VERSION ""

NS_ :

BS_:

BU_: CH DIPF DIPR ETH FC HVI HVS PARTY SDCV VEH VIRT

BO_ 1060 PCS_alertLog: 8 VEH
 SG_ PCS_alertSource : 61|3@1+ (1,0) [0|5] ""  gtw
 SG_ PCS_a038_dcdcPwmEnableLine m38 : 60|1@1+ (1,0) [0|1] ""  gtw
 SG_ PCS_a073_cpType m73 : 56|2@1+ (1,0) [0|3] ""  gtw
 SG_ PCS_a027_chgPhCNoFlowBucket m27 : 56|5@1+ (0.2,0) [0|6.2] "-"  gtw
 SG_ PCS_a054_phaseConfig m54 : 56|4@1+ (1,0) [0|8] ""  gtw
 SG_ PCS_a053_phaseConfig m53 : 56|4@1+ (1,0) [0|8] ""  gtw
 SG_ PCS_a079_eepromErrorCount m79 : 56|5@1+ (1,0) [0|31] ""  gtw
 SG_ PCS_a013_inputFrequency m13 : 54|7@1+ (1,40) [40|167] "Hz"  gtw
 SG_ PCS_a006_inputFrequency m6 : 54|7@1+ (1,40) [40|167] "Hz"  gtw
 SG_ PCS_a038_dcdcPwmEnableDeasserted m38 : 53|7@1+ (1,0) [0|127] ""  gtw
 SG_ PCS_a009_intBusV m9 : 52|8@1+ (2,0) [0|510] "V"  gtw
 SG_ PCS_a073_phaseConfig m73 : 52|4@1+ (1,0) [0|8] ""  gtw
 SG_ PCS_a090_evaluatedGridConfig m90 : 52|4@1+ (1,0) [0|8] ""  gtw
 SG_ PCS_a011_outputV m11 : 52|8@1+ (2,0) [0|510] "V"  gtw
 SG_ PCS_a091_phaseTemp m91 : 51|8@1- (1,0) [-40|120] "C"  gtw
 SG_ PCS_a051_intBusVTarget m51 : 49|9@1+ (1,0) [0|511] "V"  gtw
 SG_ PCS_a070_inputFrequency m70 : 49|9@1+ (0.1,40) [40|91.1] "Hz"  gtw
 SG_ PCS_a069_inputFrequency m69 : 49|9@1+ (0.1,40) [40|91.1] "Hz"  gtw
 SG_ PCS_a010_intBusVTarget m10 : 49|9@1+ (1,0) [0|511] "V"  gtw
 SG_ PCS_a089_Freq m89 : 49|10@1+ (0.5,0) [0|500] "kHz"  gtw
 SG_ PCS_a012_transientRetryCount m12 : 49|9@1+ (0.1,0) [0|51.1] "-"  gtw
 SG_ PCS_a088_pchgMinuCommand m88 : 49|12@1+ (0.000244140625,0) [0|1] "-"  gtw
 SG_ PCS_a071_llcFrequency m71 : 48|8@1+ (1,50) [50|305] "kHz"  gtw
 SG_ PCS_a078_ptCoolantTemp m78 : 48|8@1- (1,40) [-40|125] "C"  gtw
 SG_ PCS_a029_phaseConfig m29 : 48|4@1+ (1,0) [0|8] ""  gtw
 SG_ PCS_a027_chgPhBNoFlowBucket m27 : 48|5@1+ (0.2,0) [0|6.2] "-"  gtw
 SG_ PCS_a013_inputVToIntBusDeltaMax m13 : 47|7@1+ (1,0) [0|127] "V"  gtw
 SG_ PCS_a006_inputVToIntBusDeltaMax m6 : 47|7@1+ (1,0) [0|127] "V"  gtw
 SG_ PCS_a053_startingInputVrms m53 : 47|9@1+ (1,0) [0|511] "V"  gtw
 SG_ PCS_a054_startingInputVrms m54 : 47|9@1+ (1,0) [0|511] "V"  gtw
 SG_ PCS_a001_intBusV m1 : 45|9@1+ (1,0) [0|511] "V"  gtw
 SG_ PCS_a011_intBusV m11 : 44|8@1+ (2,0) [0|510] "V"  gtw
 SG_ PCS_a009_llcCurrent m9 : 44|8@1+ (0.1,0) [0|25.5] "A"  gtw
 SG_ PCS_a090_vRmsL1L2 m90 : 43|9@1+ (1,0) [0|511] "V"  gtw
 SG_ PCS_a038_dcdcLvBusCurrent_A m38 : 43|10@1- (0.78125,0) [-400|400] "A"  gtw
 SG_ PCS_a073_inputNGVrms m73 : 43|9@1+ (1,0) [0|511] "V"  gtw
 SG_ PCS_a019_phCFaulted m19 : 42|1@1+ (1,0) [0|1] ""  gtw
 SG_ PCS_a091_phaseInputVrms m91 : 42|9@1+ (1,0) [0|511] "A"  gtw
 SG_ PCS_a089_PhaseShift m89 : 42|7@1+ (0.0078125,0) [0|1] "-"  gtw
 SG_ PCS_a019_phBFaulted m19 : 41|1@1+ (1,0) [0|1] ""  gtw
 SG_ PCS_a010_intBusV m10 : 40|9@1+ (1,0) [0|511] "V"  gtw
 SG_ PCS_a012_batteryV m12 : 40|9@1+ (1,0) [0|511] "V"  gtw
 SG_ PCS_a029_bmsPowerCommand m29 : 40|8@1+ (0.1,0) [0|25.5] "kW"  gtw
 SG_ PCS_a014_phcTemperature m14 : 40|11@1- (0.1,40) [-40|125] "C"  gtw
 SG_ PCS_a082_faultedSubstate m82 : 40|5@1+ (1,0) [0|17] ""  gtw
 SG_ PCS_a007_inputIrms m7 : 40|10@1+ (0.1,0) [0|102.3] "A"  gtw
 SG_ PCS_a069_intBusV m69 : 40|9@1+ (1,0) [0|511] "V"  gtw
 SG_ PCS_a086_vcfrontPTCoolantTemp m86 : 40|12@1- (0.1,0) [-60|128] "C"  gtw
 SG_ PCS_a070_intBusV m70 : 40|9@1+ (1,0) [0|511] "V"  gtw
 SG_ PCS_a054_acChargeCurrentLimit m54 : 40|7@1+ (1,0) [0|127] "A"  gtw
 SG_ PCS_a053_acChargeCurrentLimit m53 : 40|7@1+ (1,0) [0|127] "A"  gtw
 SG_ PCS_a019_phAFaulted m19 : 40|1@1+ (1,0) [0|1] ""  gtw
 SG_ PCS_a081_faultedSubstate m81 : 40|5@1+ (1,0) [0|17] ""  gtw
 SG_ PCS_a043_hvPrechargeTargetV m43 : 40|12@1+ (0.146484375,0) [0|600] "V"  gtw
 SG_ PCS_a008_inputIrms m8 : 40|10@1+ (0.1,0) [0|102.3] "A"  gtw
 SG_ PCS_a078_dcdcTemperature m78 : 40|8@1- (1,40) [-40|125] "C"  gtw
 SG_ PCS_a079_operationAddress m79 : 40|16@1+ (1,0) [0|65535] ""  gtw
 SG_ PCS_a027_chgPhANoFlowBucket m27 : 40|5@1+ (0.2,0) [0|6.2] "-"  gtw
 SG_ PCS_a051_intBusV m51 : 40|9@1+ (1,0) [0|511] "V"  gtw
 SG_ PCS_a071_inputFrequency m71 : 39|9@1+ (0.1,40) [40|91.1] "Hz"  gtw
 SG_ PCS_a006_inputVrms m6 : 38|9@1+ (1,0) [0|511] "V"  gtw
 SG_ PCS_a013_inputVrms m13 : 38|9@1+ (1,0) [0|511] "V"  gtw
 SG_ PCS_a044_vTankPeak_abs_V m44 : 38|10@1+ (1,0) [0|1000] "V"  gtw
 SG_ PCS_a088_pchgLvBusMinPLim m88 : 37|12@1+ (0.000244140625,0) [0|1] "-"  gtw
 SG_ PCS_a011_llcFrequency m11 : 36|8@1+ (1,50) [50|305] "kHz"  gtw
 SG_ PCS_a067_vcfrontVcrightVoltage m67 : 36|10@1+ (0.1,0) [0|102.2] "V"  gtw
 SG_ PCS_a001_pfcCurrentRms m1 : 36|9@1+ (0.1,0) [0|51.1] "A"  gtw
 SG_ PCS_a090_vRmsL3N m90 : 34|9@1+ (1,0) [0|511] "V"  gtw
 SG_ PCS_a073_inputL3NVrms m73 : 34|9@1+ (1,0) [0|511] "V"  gtw
 SG_ PCS_a091_pfcCurrentIrms m91 : 34|8@1+ (0.1,0) [0|25.5] "A"  gtw
 SG_ PCS_a089_HV_busV m89 : 33|9@1+ (0.8203125,0) [0|420] "V"  gtw
 SG_ PCS_a038_dcdcHvBusV m38 : 33|10@1+ (0.5859375,0) [0|600] "V"  gtw
 SG_ PCS_a078_phcTemperature m78 : 32|8@1- (1,40) [-40|125] "C"  gtw
 SG_ PCS_a068_dcdcTankVoltOffset m68 : 32|16@1- (0.001525878906,0) [-50|49.99847] "V"  gtw
 SG_ PCS_a012_llcCurrent m12 : 32|8@1+ (0.1,0) [0|25.5] "A"  gtw
 SG_ PCS_a025_cpu2StoredAppCrcLsb16 m25 : 32|16@1+ (1,0) [0|65535] ""  gtw
 SG_ PCS_a009_pfcCurrentTarget m9 : 32|12@1+ (0.01,0) [0|40.95] "A"  gtw
 SG_ PCS_a029_chgInputPower m29 : 32|8@1+ (0.1,0) [0|25.5] "kW"  gtw
 SG_ PCS_a027_chgPhCTemp m27 : 32|8@1- (1,40) [-40|125] "C"  gtw
 SG_ PCS_a040_dcdcLvOutputCurrent m40 : 32|12@1+ (0.1,0) [0|409.5] "A"  gtw
 SG_ PCS_a019_userPowerRequest m19 : 32|8@1+ (0.1,0) [0|25.5] "kW"  gtw
 SG_ PCS_a010_llcCurrent m10 : 32|8@1+ (0.1,0) [0|25.5] "A"  gtw
 SG_ PCS_a051_llcCurrent m51 : 32|8@1+ (0.1,0) [0|25.5] "A"  gtw
 SG_ PCS_a079_eepromOperationErrorCod m79 : 32|5@1+ (1,0) [0|31] ""  gtw
 SG_ PCS_a001_phState m1 : 32|4@1+ (1,0) [0|6] ""  gtw
 SG_ PCS_a007_inputVrms m7 : 31|9@1+ (1,0) [0|511] "V"  gtw
 SG_ PCS_a008_inputVrms m8 : 31|9@1+ (1,0) [0|511] "V"  gtw
 SG_ PCS_a071_intBusV m71 : 30|9@1+ (1,0) [0|511] "V"  gtw
 SG_ PCS_a070_inputVrms m70 : 30|10@1+ (0.5,0) [0|511] "V"  gtw
 SG_ PCS_a069_inputVrms m69 : 30|10@1+ (0.5,0) [0|511.5] "V"  gtw
 SG_ PCS_a025_bootromRequestStatusFla m25 : 29|1@1+ (1,0) [0|1] ""  gtw
 SG_ PCS_a006_intBusV m6 : 29|9@1+ (1,0) [0|511] "V"  gtw
 SG_ PCS_a026_systemResetRegisters m26 : 29|11@1+ (1,0) [0|2047] ""  gtw
 SG_ PCS_a013_intBusV m13 : 29|9@1+ (1,0) [0|511] "V"  gtw
 SG_ PCS_a086_pcsAmbientTemperature m86 : 28|12@1- (0.1,0) [-60|128] "C"  gtw
 SG_ PCS_a066_hvpHvLinkVoltage m66 : 28|11@1- (1,0) [-550|550] "V"  gtw
 SG_ PCS_a025_bootromRequestFlag m25 : 28|1@1+ (1,0) [0|1] ""  gtw
 SG_ PCS_a044_dcdcLvBusCurrent_A m44 : 28|10@1+ (0.39100684261974583,0) [0|400] "A"  gtw
 SG_ PCS_a011_llcCurrentTarget m11 : 28|8@1+ (0.1,0) [0|25.5] "A"  gtw
 SG_ PCS_a080_phCNVRAMStoredState m80 : 27|3@1+ (1,0) [0|4] ""  gtw
 SG_ PCS_a088_pchgSlewRate m88 : 27|10@1+ (0.0009765625,0) [0|1] "-"  gtw
 SG_ PCS_a014_phbTemperature m14 : 27|11@1- (0.1,40) [-40|125] "C"  gtw
 SG_ PCS_a059_inputOvRmsThreshold m59 : 26|10@1+ (0.5,0) [0|511] "V"  gtw
 SG_ PCS_a057_inputFrequency m57 : 26|9@1+ (0.1,40) [40|91.1] "Hz"  gtw
 SG_ PCS_a074_dcdcHvBusV m74 : 26|12@1+ (0.146484375,0) [0|600] "V"  gtw
 SG_ PCS_a045_hvBusEstimated_R_kOhm m45 : 26|10@1+ (0.04887585532746823,0) [0|50] "kOhm"  gtw
 SG_ PCS_a065_inputFrequency m65 : 26|9@1+ (0.1,40) [40|91.1] "Hz"  gtw
 SG_ PCS_a067_vcfrontPcsEFuseV m67 : 26|10@1+ (0.1,0) [0|102.2] "V"  gtw
 SG_ PCS_a075_dcdcHvBusV m75 : 26|12@1+ (0.146484375,0) [0|600] "V"  gtw
 SG_ PCS_a082_dcdcHvBusV m82 : 26|12@1+ (0.146484375,0) [0|600] "V"  gtw
 SG_ PCS_a081_dcdcHvBusV m81 : 26|12@1+ (0.146484375,0) [0|600] "V"  gtw
 SG_ PCS_a058_inputFrequency m58 : 26|12@1+ (0.01,40) [40|80.95] "Hz"  gtw
 SG_ PCS_a063_hvpHvLinkVoltage m63 : 26|11@1- (1,0) [-550|550] "V"  gtw
 SG_ PCS_a028_outputVUvThreshold m28 : 26|10@1+ (0.5,0) [0|511] "V"  gtw
 SG_ PCS_a046_hvBusEstimated_R_kOhm m46 : 26|10@1+ (0.04887585532746823,0) [0|50] "kOhm"  gtw
 SG_ PCS_a060_inputOvPeakThreshold m60 : 26|10@1+ (0.5,0) [0|511] "V"  gtw
 SG_ PCS_a043_dcdcHvBusV m43 : 26|12@1+ (0.146484375,0) [0|600] "V"  gtw
 SG_ PCS_a073_inputL2NVrms m73 : 25|9@1+ (1,0) [0|511] "V"  gtw
 SG_ PCS_a091_intBusMaxRippleLevel m91 : 25|9@1+ (0.1,0) [0|50] "V"  gtw
 SG_ PCS_a054_inputIrms m54 : 25|10@1+ (0.1,0) [0|102.3] "A"  gtw
 SG_ PCS_a038_dcdcLvBusV m38 : 25|8@1+ (0.15625,0) [0|40] "V"  gtw
 SG_ PCS_a090_vRmsL2N m90 : 25|9@1+ (1,0) [0|511] "V"  gtw
 SG_ PCS_a053_inputIrms m53 : 25|10@1+ (0.1,0) [0|102.3] "A"  gtw
 SG_ PCS_a080_phBNVRAMStoredState m80 : 24|3@1+ (1,0) [0|4] ""  gtw
 SG_ PCS_a030_canID m30 : 24|16@1+ (1,0) [0|65535] ""  gtw
 SG_ PCS_a005_outputVOvThreshold m5 : 24|8@1+ (2,0) [0|510] "V"  gtw
 SG_ PCS_a040_dcdcLvVoltage m40 : 24|8@1+ (0.1,0) [0|25.5] "V"  gtw
 SG_ PCS_a012_llcFrequency m12 : 24|8@1+ (1,50) [50|305] "kHz"  gtw
 SG_ PCS_a001_llcCurrent m1 : 24|8@1+ (0.1,0) [0|25.5] "A"  gtw
 SG_ PCS_a089_G m89 : 24|9@1+ (0.1,0) [0|50] "-"  gtw
 SG_ PCS_a087_recordStatus m87 : 24|16@1+ (1,0) [0|65535] ""  gtw
 SG_ PCS_a027_chgPhBTemp m27 : 24|8@1- (1,40) [-40|125] "C"  gtw
 SG_ PCS_a078_phbTemperature m78 : 24|8@1- (1,40) [-40|125] "C"  gtw
 SG_ PCS_a025_bootloaderStatus m25 : 24|4@1+ (1,0) [0|15] ""  gtw
 SG_ PCS_a076_dcdcPwmEnableDeasserted m76 : 24|8@1+ (1,0) [0|255] ""  gtw
 SG_ PCS_a079_recordID m79 : 24|8@1+ (1,0) [0|255] ""  gtw
 SG_ PCS_a019_utilityPowerAvailable m19 : 24|8@1+ (0.1,0) [0|25.5] "kW"  gtw
 SG_ PCS_a076_dcdcEnableLine m76 : 23|1@1+ (1,0) [0|1] ""  gtw
 SG_ PCS_a069_inputIDelta m69 : 20|10@1+ (0.1,0) [0|102.3] "A"  gtw
 SG_ PCS_a011_llcCurrent m11 : 20|8@1+ (0.1,0) [0|25.5] "A"  gtw
 SG_ PCS_a009_pfcCurrentRms m9 : 20|9@1+ (0.1,0) [0|51.1] "A"  gtw
 SG_ PCS_a010_pfcCurrentRms m10 : 20|9@1+ (0.1,0) [0|51.1] "A"  gtw
 SG_ PCS_a007_phaseTemperature m7 : 20|11@1- (0.1,40) [-40|125] "C"  gtw
 SG_ PCS_a008_phaseTemperature m8 : 20|11@1- (0.1,40) [-40|125] "C"  gtw
 SG_ PCS_a025_bootromStatus m25 : 20|4@1+ (1,0) [0|15] ""  gtw
 SG_ PCS_a038_dcdcSubState m38 : 20|5@1+ (1,0) [0|17] ""  gtw
 SG_ PCS_a070_inputVDelta m70 : 20|10@1+ (0.1,0) [0|102.3] "V"  gtw
 SG_ PCS_a071_inputVrms m71 : 20|10@1+ (0.5,0) [0|511] "V"  gtw
 SG_ PCS_a013_intBusPrechargeTarget m13 : 20|9@1+ (1,0) [0|511] "V"  gtw
 SG_ PCS_a051_pfcCurrentRms m51 : 20|9@1+ (0.1,0) [0|51.1] "A"  gtw
 SG_ PCS_a079_eepromOperationRegion m79 : 20|2@1+ (1,0) [0|3] ""  gtw
 SG_ PCS_a006_intBusPrechargeTarget m6 : 20|9@1+ (1,0) [0|511] "V"  gtw
 SG_ PCS_a080_phANVRAMStoredState m80 : 19|3@1+ (1,0) [0|4] ""  gtw
 SG_ PCS_a026_NMIFlagRegisters m26 : 18|11@1+ (1,0) [0|2047] ""  gtw
 SG_ PCS_a024_VCFRONT_systemStatus m24 : 18|1@1+ (1,0) [0|1] ""  gtw
 SG_ PCS_a076_dcdcSubState m76 : 18|5@1+ (1,0) [0|17] ""  gtw
 SG_ PCS_a080_phCDamaged m80 : 18|1@1+ (1,0) [0|1] ""  gtw
 SG_ PCS_a044_shortTime_us m44 : 18|10@1+ (0.03128054740957967,0) [0|32] "us"  gtw
 SG_ PCS_a039_SDModuleClockFault_LV m39 : 17|1@1+ (1,0) [0|1] ""  gtw
 SG_ PCS_a088_pchgTargetVoltage m88 : 17|10@1+ (0.5859375,0) [0|600] "V"  gtw
 SG_ PCS_a023_CP_status m23 : 17|1@1+ (1,0) [0|1] ""  gtw
 SG_ PCS_a042_dcdcEnableCan m42 : 17|1@1+ (1,0) [0|1] ""  gtw
 SG_ PCS_a072_task2Stopped m72 : 17|1@1+ (1,0) [0|1] ""  gtw
 SG_ PCS_a080_phBDamaged m80 : 17|1@1+ (1,0) [0|1] ""  gtw
 SG_ PCS_a022_BMS_chargeStatus m22 : 17|1@1+ (1,0) [0|1] ""  gtw
 SG_ PCS_a020_chargeEnableCan m20 : 17|1@1+ (1,0) [0|1] ""  gtw
 SG_ PCS_a026_CPU2_watchdog_alarmed m26 : 17|1@1+ (1,0) [0|1] ""  gtw
 SG_ PCS_a024_VCFRONT_vehicleStatus m24 : 17|1@1+ (1,0) [0|1] ""  gtw
 SG_ PCS_a070_phState m70 : 16|4@1+ (1,0) [0|6] ""  gtw
 SG_ PCS_a089_hvSlewRate m89 : 16|8@1- (2,0) [-200|200] "V/sec"  gtw
 SG_ PCS_a072_task1Stopped m72 : 16|1@1+ (1,0) [0|1] ""  gtw
 SG_ PCS_a015_lvBusVoltage m15 : 16|8@1+ (0.15625,0) [0|40] "V"  gtw
 SG_ PCS_a069_phState m69 : 16|4@1+ (1,0) [0|6] ""  gtw
 SG_ PCS_a065_inputVrms m65 : 16|10@1+ (0.5,0) [0|511] "V"  gtw
 SG_ PCS_a087_recordID m87 : 16|8@1+ (1,0) [0|255] ""  gtw
 SG_ PCS_a022_BMS_chargerRequest m22 : 16|1@1+ (1,0) [0|1] ""  gtw
 SG_ PCS_a038_dcdcClaFaultCode m38 : 16|4@1+ (1,0) [0|8] ""  gtw
 SG_ PCS_a031_UI_chargeRequest m31 : 16|1@1+ (1,0) [0|1] ""  gtw
 SG_ PCS_a086_dcdcTemperature m86 : 16|12@1- (0.1,0) [-60|128] "C"  gtw
 SG_ PCS_a035_LV_busV m35 : 16|12@1+ (0.009765625,0) [0|39.99023] "V"  gtw
 SG_ PCS_a041_dcdcTemperature m41 : 16|11@1- (0.1,40) [-40|125] "C"  gtw
 SG_ PCS_a071_phState m71 : 16|4@1+ (1,0) [0|6] ""  gtw
 SG_ PCS_a060_inputVPeak m60 : 16|10@1+ (0.5,0) [0|511] "V"  gtw
 SG_ PCS_a042_dcdcEnableLine m42 : 16|1@1+ (1,0) [0|1] ""  gtw
 SG_ PCS_a045_hvBusEstimated_C_uF m45 : 16|10@1+ (7.820136852394917,0) [0|8000] "uF"  gtw
 SG_ PCS_a003_phState m3 : 16|4@1+ (1,0) [0|6] ""  gtw
 SG_ PCS_a026_CPU1_watchdog_alarmed m26 : 16|1@1+ (1,0) [0|1] ""  gtw
 SG_ PCS_a074_dcdcLvBusV m74 : 16|10@1+ (0.0390625,0) [0|40] "V"  gtw
 SG_ PCS_a028_outputV m28 : 16|10@1+ (0.5,0) [0|511] "V"  gtw
 SG_ PCS_a004_phState m4 : 16|4@1+ (1,0) [0|6] ""  gtw
 SG_ PCS_a079_eepromOperation m79 : 16|4@1+ (1,0) [0|15] ""  gtw
 SG_ PCS_a010_phState m10 : 16|4@1+ (1,0) [0|6] ""  gtw
 SG_ PCS_a080_phADamaged m80 : 16|1@1+ (1,0) [0|1] ""  gtw
 SG_ PCS_a067_dcdcLvBusVolt m67 : 16|10@1+ (0.0390625,0) [0|39.96094] "V"  gtw
 SG_ PCS_a001_llcFrequency m1 : 16|8@1+ (1,50) [50|305] "kHz"  gtw
 SG_ PCS_a088_pchgTargetFilterEn m88 : 16|1@1+ (1,0) [0|1] ""  gtw
 SG_ PCS_a091_intBusTarget m91 : 16|9@1+ (1,0) [0|511] "V"  gtw
 SG_ PCS_a025_cpu2ErrorCode m25 : 16|4@1+ (1,0) [0|10] ""  gtw
 SG_ PCS_a009_phState m9 : 16|4@1+ (1,0) [0|6] ""  gtw
 SG_ PCS_a057_inputVrms m57 : 16|10@1+ (0.5,0) [0|511] "V"  gtw
 SG_ PCS_a085_dcdcHalfPeriodUs m85 : 16|16@1+ (0.005,0) [0|325] "us"  gtw
 SG_ PCS_a021_HVP_pcsControl m21 : 16|1@1+ (1,0) [0|1] ""  gtw
 SG_ PCS_a030_canRxErrorType m30 : 16|3@1+ (1,0) [0|6] ""  gtw
 SG_ PCS_a002_phState m2 : 16|4@1+ (1,0) [0|6] ""  gtw
 SG_ PCS_a090_vRmsL1N m90 : 16|9@1+ (1,0) [0|511] "V"  gtw
 SG_ PCS_a063_chgOutputV m63 : 16|10@1+ (1,0) [0|1023] "V"  gtw
 SG_ PCS_a007_phState m7 : 16|4@1+ (1,0) [0|6] ""  gtw
 SG_ PCS_a024_VCFRONT_sensors m24 : 16|1@1+ (1,0) [0|1] ""  gtw
 SG_ PCS_a059_inputVrms m59 : 16|10@1+ (0.5,0) [0|511] "V"  gtw
 SG_ PCS_a014_phaTemperature m14 : 16|11@1- (0.1,40) [-40|125] "C"  gtw
 SG_ PCS_a029_inputVrms m29 : 16|9@1+ (1,0) [0|511] "V"  gtw
 SG_ PCS_a037_dcdcPwmDeassertedCount m37 : 16|8@1+ (1,0) [0|255] ""  gtw
 SG_ PCS_a068_dcdcTankVolt m68 : 16|16@1- (0.03051757813,0) [-1000|999.96948] "V"  gtw
 SG_ PCS_a076_pcsControlRequest m76 : 16|2@1+ (1,0) [0|3] ""  gtw
 SG_ PCS_a020_chargeEnableLine m20 : 16|1@1+ (1,0) [0|1] ""  gtw
 SG_ PCS_a043_dcdcLvBusV m43 : 16|10@1+ (0.0390625,0) [0|40] "V"  gtw
 SG_ PCS_a008_phState m8 : 16|4@1+ (1,0) [0|6] ""  gtw
 SG_ PCS_a011_phState m11 : 16|4@1+ (1,0) [0|6] ""  gtw
 SG_ PCS_a083_logId m83 : 16|4@1+ (1,0) [0|15] ""  gtw
 SG_ PCS_a062_chgInputIOffset m62 : 16|12@1- (0.01,0) [-20.48|20.47] "A"  gtw
 SG_ PCS_a075_dcdcLvBusV m75 : 16|10@1+ (0.0390625,0) [0|40] "V"  gtw
 SG_ PCS_a019_pcsMaxAvailablePower m19 : 16|8@1+ (0.1,0) [0|25.5] "kW"  gtw
 SG_ PCS_a046_hvBusEstimated_C_uF m46 : 16|10@1+ (7.820136852394917,0) [0|8000] "uF"  gtw
 SG_ PCS_a053_inputVrms m53 : 16|9@1+ (1,0) [0|511] "V"  gtw
 SG_ PCS_a082_dcdcLvBusV m82 : 16|10@1+ (0.0390625,0) [0|40] "V"  gtw
 SG_ PCS_a036_LV_busV m36 : 16|12@1+ (0.009765625,0) [0|39.99023] "V"  gtw
 SG_ PCS_a078_phaTemperature m78 : 16|8@1- (1,40) [-40|125] "C"  gtw
 SG_ PCS_a081_dcdcLvBusV m81 : 16|10@1+ (0.0390625,0) [0|40] "V"  gtw
 SG_ PCS_a049_dcdcTemperature m49 : 16|11@1- (0.1,40) [-40|125] "C"  gtw
 SG_ PCS_a058_inputVrms m58 : 16|10@1+ (0.5,0) [0|511] "V"  gtw
 SG_ PCS_a006_phState m6 : 16|4@1+ (1,0) [0|6] ""  gtw
 SG_ PCS_a034_HV_busV m34 : 16|12@1+ (0.146484375,0) [0|599.85352] "V"  gtw
 SG_ PCS_a005_outputV m5 : 16|8@1+ (2,0) [0|510] "V"  gtw
 SG_ PCS_a039_SDModuleClockFault_HV m39 : 16|1@1+ (1,0) [0|1] ""  gtw
 SG_ PCS_a023_CP_evseStatus m23 : 16|1@1+ (1,0) [0|1] ""  gtw
 SG_ PCS_a027_chgPhATemp m27 : 16|8@1- (1,40) [-40|125] "C"  gtw
 SG_ PCS_a012_phState m12 : 16|4@1+ (1,0) [0|6] ""  gtw
 SG_ PCS_a073_inputL1NVrms m73 : 16|9@1+ (1,0) [0|511] "V"  gtw
 SG_ PCS_a052_inputVrms m52 : 16|9@1+ (1,0) [0|511] "V"  gtw
 SG_ PCS_a044_FaultReasonCode m44 : 16|2@1+ (1,0) [0|3] ""  gtw
 SG_ PCS_a066_dcdcHvBusVolt m66 : 16|12@1+ (0.146484375,0) [0|599.85352] "V"  gtw
 SG_ PCS_a051_phState m51 : 16|4@1+ (1,0) [0|6] ""  gtw
 SG_ PCS_a033_HV_busV m33 : 16|12@1+ (0.146484375,0) [0|600] "V"  gtw
 SG_ PCS_a061_chgInputVOffset m61 : 16|13@1+ (0.1,0) [0|819.1] "V"  gtw
 SG_ PCS_a040_dcdcLvVoltageTarget m40 : 16|8@1+ (0.1,0) [0|25.5] "V"  gtw
 SG_ PCS_a064_chgOutputIOffset m64 : 16|12@1- (0.01,0) [-20.48|20.47] "A"  gtw
 SG_ PCS_a054_inputVrms m54 : 16|9@1+ (1,0) [0|511] "V"  gtw
 SG_ PCS_a013_phState m13 : 16|4@1+ (1,0) [0|6] ""  gtw
 SG_ PCS_alertType : 15|1@1+ (1,0) [0|1] ""  gtw
 SG_ PCS_alertID M : 0|7@1+ (1,0) [0|91] ""  dbg

BO_ 1009 VCFRONT_lighting: 8 VEH
 SG_ VCFRONT_lowBeamsCalibrated : 62|1@1+ (1,0) [0|1] ""  gtw
 SG_ VCFRONT_lowBeamsOnForDRL : 61|1@1+ (1,0) [0|1] ""  gtw
 SG_ VCFRONT_simLatchingStalk : 59|2@1+ (1,0) [0|3] ""  das
 SG_ VCFRONT_highBeamSwitchActive : 58|1@1+ (1,0) [0|1] ""  das
 SG_ VCFRONT_parkRightStatus : 56|2@1+ (1,0) [0|3] ""  gtw
 SG_ VCFRONT_parkLeftStatus : 54|2@1+ (1,0) [0|3] ""  gtw
 SG_ VCFRONT_turnSignalRightStatus : 52|2@1+ (1,0) [0|3] ""  das
 SG_ VCFRONT_turnSignalLeftStatus : 50|2@1+ (1,0) [0|3] ""  das
 SG_ VCFRONT_sideRepeaterRightStatus : 48|2@1+ (1,0) [0|3] ""  gtw
 SG_ VCFRONT_sideRepeaterLeftStatus : 46|2@1+ (1,0) [0|3] ""  gtw
 SG_ VCFRONT_sideMarkersStatus : 44|2@1+ (1,0) [0|3] ""  gtw
 SG_ VCFRONT_fogRightStatus : 42|2@1+ (1,0) [0|3] ""  gtw
 SG_ VCFRONT_fogLeftStatus : 40|2@1+ (1,0) [0|3] ""  gtw
 SG_ VCFRONT_DRLRightStatus : 38|2@1+ (1,0) [0|3] ""  gtw
 SG_ VCFRONT_DRLLeftStatus : 36|2@1+ (1,0) [0|3] ""  gtw
 SG_ VCFRONT_highBeamRightStatus : 34|2@1+ (1,0) [0|3] ""  das
 SG_ VCFRONT_highBeamLeftStatus : 32|2@1+ (1,0) [0|3] ""  das
 SG_ VCFRONT_lowBeamRightStatus : 30|2@1+ (1,0) [0|3] ""  das
 SG_ VCFRONT_lowBeamLeftStatus : 28|2@1+ (1,0) [0|3] ""  das
 SG_ VCFRONT_hazardSwitchBacklight : 27|1@1+ (1,0) [0|1] ""  vcleft
 SG_ VCFRONT_seeYouHomeLightingReq : 26|1@1+ (1,0) [0|1] ""  gtw
 SG_ VCFRONT_approachLightingRequest : 25|1@1+ (1,0) [0|1] ""  vcleft
 SG_ VCFRONT_courtesyLightingRequest : 24|1@1+ (1,0) [0|1] ""  vcleft
 SG_ VCFRONT_switchLightingBrightness : 16|8@1+ (0.5,0) [0|127] "%"  vcleft
 SG_ VCFRONT_ambientLightingBrightnes : 8|8@1+ (0.5,0) [0|127] "%"  vcleft
 SG_ VCFRONT_hazardLightRequest : 4|3@1+ (1,0) [0|7] ""  gtw
 SG_ VCFRONT_indicatorRightRequest : 2|2@1+ (1,0) [0|2] ""  das
 SG_ VCFRONT_indicatorLeftRequest : 0|2@1+ (1,0) [0|2] ""  das

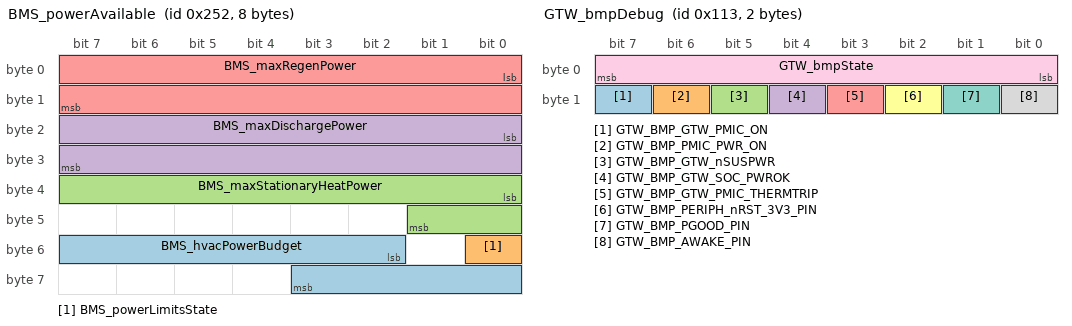
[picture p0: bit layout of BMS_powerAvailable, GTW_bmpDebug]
BO_ 594 BMS_powerAvailable: 8 VEH
 SG_ BMS_hvacPowerBudget : 50|10@1+ (0.02,0) [0|20.46] "kW"  gtw
 SG_ BMS_powerLimitsState : 48|1@1+ (1,0) [0|1] ""  di
 SG_ BMS_maxStationaryHeatPower : 32|10@1+ (0.01,0) [0|10.24] "kW"  di
 SG_ BMS_maxDischargePower : 16|16@1+ (0.01,0) [0|655.35] "kW"  di
 SG_ BMS_maxRegenPower : 0|16@1+ (0.01,0) [0|655.35] "kW"  di

BO_ 275 GTW_bmpDebug: 2 VEH
 SG_ GTW_BMP_GTW_PMIC_ON : 15|1@1+ (1,0) [0|1] ""  X
 SG_ GTW_BMP_PMIC_PWR_ON : 14|1@1+ (1,0) [0|1] ""  X
 SG_ GTW_BMP_GTW_nSUSPWR : 13|1@1+ (1,0) [0|1] ""  X
 SG_ GTW_BMP_GTW_SOC_PWROK : 12|1@1+ (1,0) [0|1] ""  X
 SG_ GTW_BMP_GTW_PMIC_THERMTRIP : 11|1@1+ (1,0) [0|1] ""  X
 SG_ GTW_BMP_PERIPH_nRST_3V3_PIN : 10|1@1+ (1,0) [0|1] ""  X
 SG_ GTW_BMP_PGOOD_PIN : 9|1@1+ (1,0) [0|1] ""  X
 SG_ GTW_BMP_AWAKE_PIN : 8|1@1+ (1,0) [0|1] ""  X
 SG_ GTW_bmpState : 7|8@0+ (1,0) [0|255] ""  X

BO_ 2006 DIS_dyno: 8 VEH
 SG_ DIS_torqueEstimate m32 : 48|13@1- (0.25,0.0) [-750|750] "Nm"  X
 SG_ DIS_IsMag m0 : 48|16@1- (0.1,0.0) [-3276.8|3276.7] "A"  dbg
 SG_ DIS_voltageForFlux m1 : 48|16@1+ (0.007629510949,0) [0|500.000000042715] "V"  dbg
 SG_ DIS_postPedalMaxTorque m33 : 44|12@1+ (0.25,0) [0|750] "Nm"  X
 SG_ DIS_Vsy m1 : 32|16@1- (4e-05,0.0) [-1.31072|1.31068] "mindex"  dbg
 SG_ DIS_motorRPM m32 : 32|16@1- (1,0) [-17000|17000] "RPM"  X
 SG_ DIS_Isy m0 : 32|16@1+ (1.52590218966965e-05,0) [0|1.00000000000001] "A"  dbg
 SG_ DIS_postPedalMinTorque m33 : 32|12@1+ (0.25,-750) [-750|0] "Nm"  X
 SG_ DIS_pedalMaxTorque m33 : 20|12@1+ (0.25,0) [0|750] "Nm"  X
 SG_ DIS_Vsx m1 : 16|16@1- (4e-05,0.0) [-1.31072|1.31068] "mindex"  dbg
 SG_ DIS_Isx m0 : 16|16@1+ (1.52590218966965e-05,0) [0|1.00000000000001] "A"  dbg
 SG_ DIS_torqueMotor m32 : 16|13@1- (0.25,0.0) [-750|750] "Nm"  X
 SG_ DIS_pedalMinTorque m33 : 8|12@1+ (0.25,-750) [-750|0] "Nm"  X
 SG_ DIS_dynoSelector M : 0|8@1+ (1,0) [0|33] ""  X

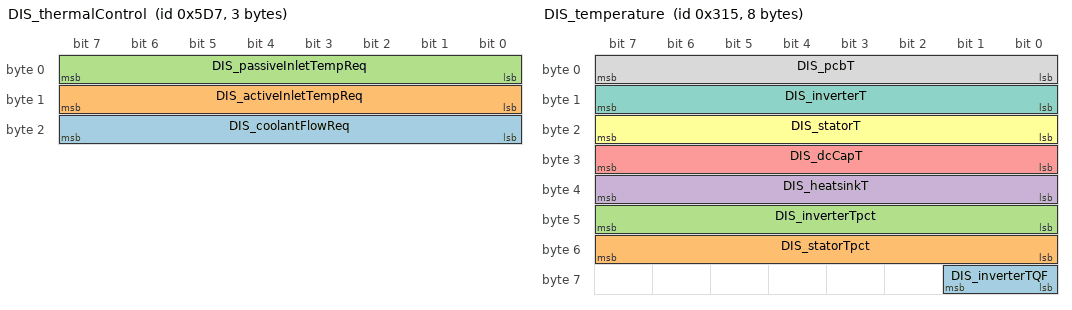
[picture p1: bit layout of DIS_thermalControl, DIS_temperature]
BO_ 1495 DIS_thermalControl: 3 VEH
 SG_ DIS_coolantFlowReq : 16|8@1+ (0.2,0) [0|50] "LPM"  gtw
 SG_ DIS_activeInletTempReq : 8|8@1+ (1,-40) [-40|120] "DegC"  gtw
 SG_ DIS_passiveInletTempReq : 0|8@1+ (1,-40) [-40|120] "DegC"  gtw

BO_ 789 DIS_temperature: 8 VEH
 SG_ DIS_inverterTQF : 56|2@1+ (1,0) [0|3] ""  gtw
 SG_ DIS_statorTpct : 48|8@1+ (0.4,0) [0|100] "%"  X
 SG_ DIS_inverterTpct : 40|8@1+ (0.4,0) [0|100] "%"  X
 SG_ DIS_heatsinkT : 32|8@1+ (1,-40) [-40|120] "DegC"  gtw
 SG_ DIS_dcCapT : 24|8@1+ (1,-40) [-40|120] "DegC"  X
 SG_ DIS_statorT : 16|8@1+ (1,-40) [-40|200] "DegC"  gtw
 SG_ DIS_inverterT : 8|8@1+ (1,-40) [-40|120] "DegC"  gtw
 SG_ DIS_pcbT : 0|8@1+ (1,-40) [-40|120] "DegC"  gtw

BO_ 2033 GTW_hrl: 7 VEH
 SG_ GTW_hrlTriggerBus m2 : 48|3@1+ (1,0) [0|4] ""  X
 SG_ GTW_hrlTriggerId m2 : 39|16@0+ (1,0) [0|65535] ""  X
 SG_ GTW_hrlTriggerType m2 : 24|4@1+ (1,0) [0|15] ""  X
 SG_ GTW_hrlTriggerDuration m2 : 15|16@0+ (1,0) [0|65535] "seconds"  X
 SG_ GTW_hrlPagesCount m1 : 15|32@0+ (1,0) [0|4294967295] ""  X
 SG_ GTW_hrlState m2 : 2|1@1+ (1,0) [0|1] ""  X
 SG_ GTW_hrlIndex M : 0|2@1+ (1,0) [1|2] ""  X

BO_ 541 CP_evseStatus: 8 VEH
 SG_ CP_acChargeState : 60|2@1+ (1,0) [0|2] ""  gtw
 SG_ CP_gbdcChargeAttempts : 58|2@1+ (1,0) [0|3] ""  X
 SG_ CP_gbdcFailureReason : 56|2@1+ (1,0) [0|3] ""  X
 SG_ CP_gbdcStopChargeReason : 53|3@1+ (1,0) [0|6] ""  X
 SG_ CP_gbState : 48|5@1+ (1,0) [0|16] ""  X
 SG_ CP_vehiclePrechargeRequired : 44|1@1+ (1,0) [0|1] ""  gtw
 SG_ CP_acNumRetries : 42|2@1+ (1,0) [0|3] ""  gtw
 SG_ CP_acChargeRetriesExceeded : 41|1@1+ (1,0) [0|1] ""  X
 SG_ CP_stopChargeRequest : 40|1@1+ (1,0) [0|1] ""  gtw
 SG_ CP_evseChargeType : 38|2@1+ (1,0) [0|2] ""  gtw
 SG_ CP_digitalCommsEstablished : 37|1@1+ (1,0) [0|1] ""  dbg
 SG_ CP_teslaSwcanState : 34|3@1+ (1,0) [0|6] ""  dbg
 SG_ CP_digitalCommsAttempts : 32|2@1+ (1,0) [0|3] ""  dbg
 SG_ CP_cableCurrentLimit : 24|7@1+ (1,0) [0|128] "A"  dbg
 SG_ CP_cableType : 16|3@1+ (1,0) [0|4] ""  dbg
 SG_ CP_pilotCurrent : 8|8@1+ (0.5,0) [0|127.5] "A"  dbg
 SG_ CP_pilot : 5|3@1+ (1,0) [0|7] ""  dbg
 SG_ CP_proximity : 3|2@1+ (1,0) [0|3] ""  dbg
 SG_ CP_lineVoltageRequested : 2|1@1+ (1,0) [0|1] ""  gtw
 SG_ CP_evseRequest : 1|1@1+ (1,0) [0|1] ""  dbg
 SG_ CP_evseAccept : 0|1@1+ (1,0) [0|1] ""  dbg

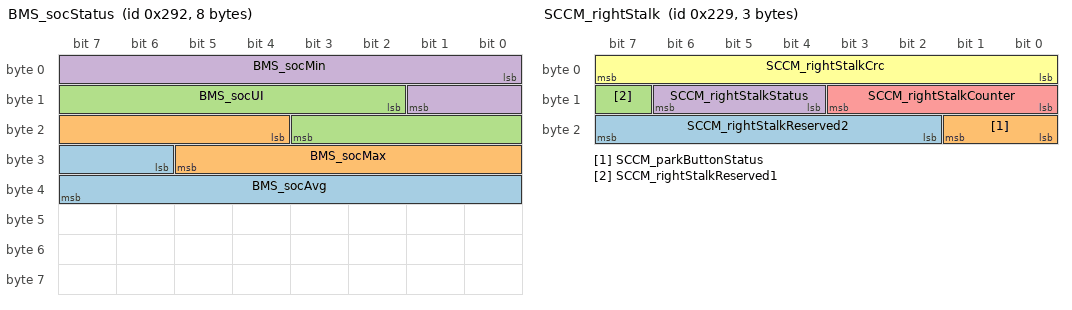
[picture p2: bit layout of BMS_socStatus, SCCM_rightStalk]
BO_ 658 BMS_socStatus: 8 VEH
 SG_ BMS_socAvg : 30|10@1+ (0.1,0) [0|102.2] "%"  gtw
 SG_ BMS_socMax : 20|10@1+ (0.1,0) [0|102.2] "%"  gtw
 SG_ BMS_socUI : 10|10@1+ (0.1,0) [0|100] "%"  gtw
 SG_ BMS_socMin : 0|10@1+ (0.1,0) [0|102.2] "%"  gtw

BO_ 680 EPBL_status: 8 VEH
 SG_ EPBL_statusChecksum : 56|8@1+ (1,0) [0|255] ""  X
 SG_ EPBL_statusCounter : 52|4@1+ (1,0) [0|15] ""  X
 SG_ EPBL_blockDrive : 51|1@1+ (1,0) [0|1] ""  vcfront
 SG_ EPBL_bothDisconnected : 50|1@1+ (1,0) [0|1] ""  X
 SG_ EPBL_winchModeAvailable : 49|1@1+ (1,0) [0|1] ""  X
 SG_ EPBL_hornRequest : 48|1@1+ (1,0) [0|1] ""  vcfront
 SG_ EPBL_okToPark : 47|1@1+ (1,0) [0|1] ""  di
 SG_ EPBL_espPowerRequest : 46|1@1+ (1,0) [0|1] ""  vcfront
 SG_ EPBL_winchModeTimer : 32|12@1+ (1,0) [0|4095] ""  X
 SG_ EPBL_brakeDiscWipeRequest : 30|2@1+ (1,0) [0|3] ""  X
 SG_ EPBL_cdpRequest : 27|1@1+ (1,0) [0|1] ""  X
 SG_ EPBL_updateMode : 24|1@1+ (1,0) [0|1] ""  X
 SG_ EPBL_winchModeActive : 23|1@1+ (1,0) [0|1] ""  X
 SG_ EPBL_requestUserConfirmation : 21|1@1+ (1,0) [0|1] ""  X
 SG_ EPBL_uiParkAvailable : 20|1@1+ (1,0) [0|1] ""  X
 SG_ EPBL_brakeHWConfigMismatch : 19|1@1+ (1,0) [0|1] ""  X
 SG_ EPBL_brakeLight : 18|1@1+ (1,0) [0|1] ""  vcleft
 SG_ EPBL_summonEnabled : 17|1@1+ (1,0) [0|1] ""  X
 SG_ EPBL_telltale : 8|3@1+ (1,0) [0|7] ""  X
 SG_ EPBL_systemStatus : 0|4@1+ (1,0) [0|8] ""  das

BO_ 1620 PMS_udsResponse: 8 VEH
 SG_ PMS_udsResponseData : 7|64@0+ (1,0) [0|18446744073709551615] ""  gtw

BO_ 1536 UDS_vcfrontRequest: 8 VEH
 SG_ UDS_vcfrontRequestData : 7|64@0+ (1,0) [0|18446744073709551615] ""  vcfront

BO_ 553 SCCM_rightStalk: 3 VEH
 SG_ SCCM_rightStalkReserved2 : 18|6@1+ (1,0) [0|63] ""  X
 SG_ SCCM_parkButtonStatus : 16|2@1+ (1,0) [0|3] ""  das
 SG_ SCCM_rightStalkReserved1 : 15|1@1+ (1,0) [0|1] ""  X
 SG_ SCCM_rightStalkStatus : 12|3@1+ (1,0) [0|6] ""  das
 SG_ SCCM_rightStalkCounter : 8|4@1+ (1,0) [0|15] ""  X
 SG_ SCCM_rightStalkCrc : 0|8@1+ (1,0) [0|255] ""  X

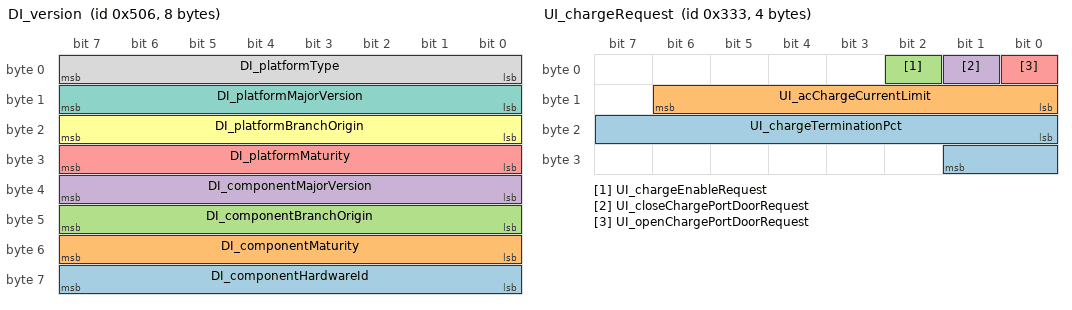
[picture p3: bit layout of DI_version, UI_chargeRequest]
BO_ 1286 DI_version: 8 VEH
 SG_ DI_componentHardwareId : 56|8@1+ (1,0) [0|255] ""  X
 SG_ DI_componentMaturity : 48|8@1+ (1,0) [0|255] ""  X
 SG_ DI_componentBranchOrigin : 40|8@1+ (1,0) [0|255] ""  X
 SG_ DI_componentMajorVersion : 32|8@1+ (1,0) [0|255] ""  X
 SG_ DI_platformMaturity : 24|8@1+ (1,0) [0|255] ""  X
 SG_ DI_platformBranchOrigin : 16|8@1+ (1,0) [0|255] ""  X
 SG_ DI_platformMajorVersion : 8|8@1+ (1,0) [0|255] ""  X
 SG_ DI_platformType : 0|8@1+ (1,0) [0|255] ""  X

BO_ 819 UI_chargeRequest: 4 VEH
 SG_ UI_chargeTerminationPct : 16|10@1+ (0.1,0) [25|100] "%"  bms
 SG_ UI_acChargeCurrentLimit : 8|7@1+ (1,0) [0|127] "A"  bms
 SG_ UI_chargeEnableRequest : 2|1@1+ (1,0) [0|1] ""  bms
 SG_ UI_closeChargePortDoorRequest : 1|1@1+ (1,0) [0|1] ""  bms
 SG_ UI_openChargePortDoorRequest : 0|1@1+ (1,0) [0|1] ""  bms

BO_ 1555 CMP_udsResponse: 8 VEH
 SG_ CMP_udsResponseData : 7|64@0+ (1,0) [0|18446744073709551615] ""  gtw

BO_ 1898 HVP_vehicleDbg: 8 VEH
 SG_ HVP_FcNegativeContPwmDuty m0 : 50|14@1+ (0.01,0) [0|100] "%"  dbg
 SG_ HVP_minRobinBrickId m1 : 48|7@1+ (1,1) [1|128] ""  X
 SG_ HVP_FcPositiveContPwmDuty m0 : 36|14@1+ (0.01,0) [0|100] "%"  dbg
 SG_ HVP_minRobinBrickV m1 : 32|16@1- (0.001,0) [-5|5] "V"  gtw
 SG_ HVP_maxRobinBrickId m1 : 24|7@1+ (1,1) [1|128] ""  X
 SG_ HVP_packPositiveContPwmDuty m0 : 22|14@1+ (0.01,0) [0|100] "%"  dbg
 SG_ HVP_packNegativeContPwmDuty m0 : 8|14@1+ (0.01,0) [0|100] "%"  dbg
 SG_ HVP_maxRobinBrickV m1 : 8|16@1- (0.001,0) [-5|5] "V"  gtw
 SG_ HVP_avgRobinBrickV m2 : 8|16@1- (0.001,0) [-32.768|32.767] "V"  X
 SG_ HVP_ecuLogUploadRequest : 5|2@1+ (1,0) [0|3] ""  gtw
 SG_ HVP_vehicleDebugMultiplexer M : 0|5@1+ (1,0) [0|2] ""  X

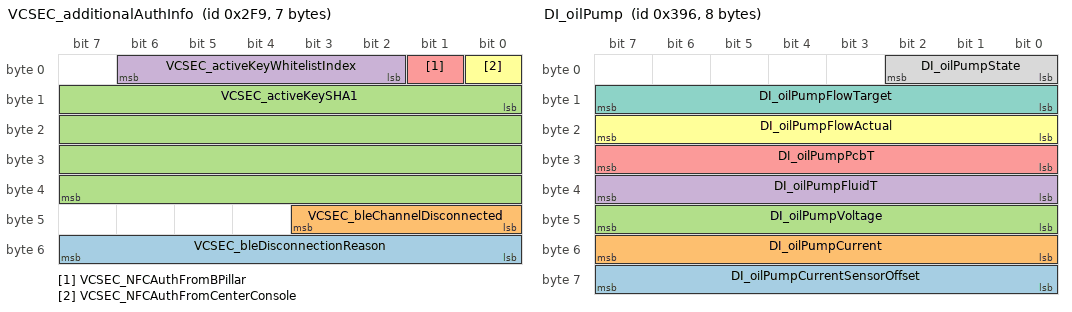
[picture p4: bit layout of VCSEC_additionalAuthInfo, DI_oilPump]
BO_ 761 VCSEC_additionalAuthInfo: 7 VEH
 SG_ VCSEC_bleDisconnectionReason : 48|8@1+ (1,0) [0|255] ""  gtw
 SG_ VCSEC_bleChannelDisconnected : 40|4@1+ (1,0) [0|15] ""  gtw
 SG_ VCSEC_activeKeySHA1 : 8|32@1+ (1,0) [0|4294967295] ""  gtw
 SG_ VCSEC_activeKeyWhitelistIndex : 2|5@1+ (1,0) [0|31] ""  gtw
 SG_ VCSEC_NFCAuthFromBPillar : 1|1@1+ (1,0) [0|1] ""  gtw
 SG_ VCSEC_NFCAuthFromCenterConsole : 0|1@1+ (1,0) [0|1] ""  gtw

BO_ 918 DI_oilPump: 8 VEH
 SG_ DI_oilPumpCurrentSensorOffset : 56|8@1+ (0.005,0) [0|1.27] "A"  gtw
 SG_ DI_oilPumpCurrent : 48|8@1+ (0.1,0) [0|25.4] "A"  gtw
 SG_ DI_oilPumpVoltage : 40|8@1+ (0.1,0) [0|25.4] "V"  gtw
 SG_ DI_oilPumpFluidT : 32|8@1+ (1,-40) [-40|214] "DegC"  gtw
 SG_ DI_oilPumpPcbT : 24|8@1+ (1,-40) [-40|214] "DegC"  gtw
 SG_ DI_oilPumpFlowActual : 16|8@1+ (0.06,0) [0|15] "LPM"  gtw
 SG_ DI_oilPumpFlowTarget : 8|8@1+ (0.06,0) [0|15] "LPM"  gtw
 SG_ DI_oilPumpState : 0|3@1+ (1,0) [0|7] ""  gtw

BO_ 818 BMS_bmbMinMax: 6 VEH
 SG_ BMS_brickNumVoltageMin m1 : 40|7@1+ (1,1) [1|128] ""  gtw
 SG_ BMS_modelTMin m0 : 40|8@1+ (0.5,-40) [-40|87.5] "DegC"  gtw
 SG_ BMS_modelTMax m0 : 32|8@1+ (0.5,-40) [-40|87.5] "DegC"  gtw
 SG_ BMS_brickNumVoltageMax m1 : 32|7@1+ (1,1) [1|128] ""  gtw
 SG_ BMS_thermistorTMin m0 : 24|8@1+ (0.5,-40) [-40|87.5] "DegC"  epbl
 SG_ BMS_thermistorTMax m0 : 16|8@1+ (0.5,-40) [-40|87.5] "DegC"  gtw
 SG_ BMS_brickVoltageMin m1 : 16|12@1+ (0.002,0) [0|5] "V"  gtw
 SG_ BMS_thermistorNumTMin m0 : 8|4@1+ (1,0) [0|15] ""  gtw
 SG_ BMS_thermistorNumTMax m0 : 2|4@1+ (1,0) [0|15] ""  gtw
 SG_ BMS_brickVoltageMax m1 : 2|12@1+ (0.002,0) [0|5] "V"  gtw
 SG_ BMS_bmbMinMaxMultiplexer M : 0|2@1+ (1,0) [0|2] ""  X

BO_ 1557 DIS_udsResponse: 8 VEH
 SG_ DIS_udsResponseData : 7|64@0+ (1,0) [0|18446744073709551615] ""  gtw

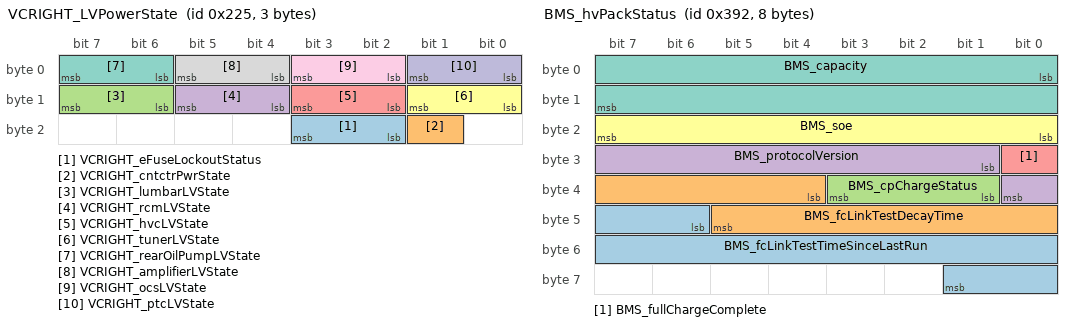
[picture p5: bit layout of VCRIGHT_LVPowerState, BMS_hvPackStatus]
BO_ 549 VCRIGHT_LVPowerState: 3 VEH
 SG_ VCRIGHT_eFuseLockoutStatus : 18|2@1+ (1,0) [0|2] ""  gtw
 SG_ VCRIGHT_cntctrPwrState : 17|1@1+ (1,0) [0|1] ""  gtw
 SG_ VCRIGHT_lumbarLVState : 14|2@1+ (1,0) [0|3] ""  gtw
 SG_ VCRIGHT_rcmLVState : 12|2@1+ (1,0) [0|3] ""  X
 SG_ VCRIGHT_hvcLVState : 10|2@1+ (1,0) [0|3] ""  X
 SG_ VCRIGHT_tunerLVState : 8|2@1+ (1,0) [0|3] ""  gtw
 SG_ VCRIGHT_rearOilPumpLVState : 6|2@1+ (1,0) [0|3] ""  gtw
 SG_ VCRIGHT_amplifierLVState : 4|2@1+ (1,0) [0|3] ""  vcfront
 SG_ VCRIGHT_ocsLVState : 2|2@1+ (1,0) [0|3] ""  X
 SG_ VCRIGHT_ptcLVState : 0|2@1+ (1,0) [0|3] ""  X

BO_ 914 BMS_hvPackStatus: 8 VEH
 SG_ BMS_fcLinkTestTimeSinceLastRun : 46|12@1+ (0.01758241758,0) [0|72] "Hours"  gtw
 SG_ BMS_fcLinkTestDecayTime : 36|10@1+ (2,0) [0|2044] "mS"  gtw
 SG_ BMS_cpChargeStatus : 33|3@1+ (1,0) [0|5] ""  gtw
 SG_ BMS_protocolVersion : 25|8@1+ (1,0) [0|255] ""  gtw
 SG_ BMS_fullChargeComplete : 24|1@1+ (1,0) [0|1] ""  gtw
 SG_ BMS_soe : 16|8@1+ (0.3937007875,0) [0|100] "%"  X
 SG_ BMS_capacity : 0|16@1+ (0.015258789063,0) [0|1000] "kWh"  X

BO_ 824 UMC_alertMatrix1: 8 VEH
 SG_ UMC_a023_adcSelfTest : 22|1@1+ (1,0) [0|1] ""  gtw
 SG_ UMC_a022_criticalRAM : 21|1@1+ (1,0) [0|1] ""  gtw
 SG_ UMC_a021_dataBus : 20|1@1+ (1,0) [0|1] ""  gtw
 SG_ UMC_a020_applicationCRC : 19|1@1+ (1,0) [0|1] ""  gtw
 SG_ UMC_a019_inputOTFoldback : 18|1@1+ (1,0) [0|1] ""  gtw
 SG_ UMC_a018_vehConnOTFoldback : 17|1@1+ (1,0) [0|1] ""  gtw
 SG_ UMC_a017_wallPlugOTFoldback : 16|1@1+ (1,0) [0|1] ""  gtw
 SG_ UMC_a016_pcbaOTFoldback : 15|1@1+ (1,0) [0|1] ""  gtw
 SG_ UMC_a015_SA_Connection : 14|1@1+ (1,0) [0|1] ""  gtw
 SG_ UMC_a014_SA_Genealogy : 13|1@1+ (1,0) [0|1] ""  gtw
 SG_ UMC_a013_SA_Temperature : 12|1@1+ (1,0) [0|1] ""  gtw
 SG_ UMC_a012_pilotFault : 11|1@1+ (1,0) [0|1] ""  gtw
 SG_ UMC_a011_proxDisconnected : 10|1@1+ (1,0) [0|1] ""  gtw
 SG_ UMC_a010_inputOT : 9|1@1+ (1,0) [0|1] ""  gtw
 SG_ UMC_a009_vehConnOT : 8|1@1+ (1,0) [0|1] ""  gtw
 SG_ UMC_a008_wallPlugOT : 7|1@1+ (1,0) [0|1] ""  gtw
 SG_ UMC_a007_pcbaOT : 6|1@1+ (1,0) [0|1] ""  gtw
 SG_ UMC_a006_contactorWelded : 5|1@1+ (1,0) [0|1] ""  gtw
 SG_ UMC_a005_inputUnderVoltage : 4|1@1+ (1,0) [0|1] ""  gtw
 SG_ UMC_a004_inputOverVoltage : 3|1@1+ (1,0) [0|1] ""  gtw
 SG_ UMC_a003_GFCISelfTestFault : 2|1@1+ (1,0) [0|1] ""  gtw
 SG_ UMC_a002_GFCITripped : 1|1@1+ (1,0) [0|1] ""  gtw
 SG_ UMC_a001_gndMonIntrptLineSide : 0|1@1+ (1,0) [0|1] ""  gtw

BO_ 1317 PM_alertLog: 8 VEH
 SG_ PM_a050_excessiveRearSlipRequest m50 : 63|1@1+ (1,0) [0|1] ""  gtw
 SG_ PM_a051_trackModeOn m51 : 63|1@1+ (1,0) [0|1] ""  gtw
 SG_ PM_a049_trackModeOn m49 : 63|1@1+ (1,0) [0|1] ""  gtw
 SG_ PM_a052_trackModeOn m52 : 62|1@1+ (1,0) [0|1] ""  gtw
 SG_ PM_a050_trackModeOn m50 : 62|1@1+ (1,0) [0|1] ""  gtw
 SG_ PM_a011_sampleFreeze m11 : 61|1@1+ (1,0) [0|1] ""  gtw
 SG_ PM_a011_badPhaseBsample m11 : 60|1@1+ (1,0) [0|1] ""  gtw
 SG_ PM_a011_badPhaseAsample m11 : 59|1@1+ (1,0) [0|1] ""  gtw
 SG_ PM_a052_masterCylinderPressure m52 : 55|7@1+ (2.4,-30) [-30|274.8] "bar"  gtw
 SG_ PM_a049_excessiveYawIntegral m49 : 54|9@1+ (10,0) [0|5110] "Nm.s"  gtw
 SG_ PM_a051_yawRateError m51 : 54|9@1- (0.008,0.008) [-2.04|2.048] "rad/s"  gtw
 SG_ PM_a023_accelEstimateDis m23 : 54|10@1- (0.05,-4.7) [-15|5.5] "m/s^2"  gtw
 SG_ PM_a055_diMIA m55 : 54|1@1+ (1,0) [0|1] ""  gtw
 SG_ PM_a050_excessiveYawIntegral m50 : 53|9@1+ (10,0) [0|5110] "Nm.s"  gtw
 SG_ PM_a055_claMIA m55 : 53|1@1+ (1,0) [0|1] ""  gtw
 SG_ PM_a055_diSpeedMismatch m55 : 52|1@1+ (1,0) [0|1] ""  gtw
 SG_ PM_a044_diVehicleHoldState m44 : 51|3@1+ (1,0) [0|7] ""  gtw
 SG_ PM_a055_diElecAngleMismatch m55 : 51|1@1+ (1,0) [0|1] ""  gtw
 SG_ PM_a055_phaseOutOfSpec m55 : 50|1@1+ (1,0) [0|1] ""  gtw
 SG_ PM_a055_noCarrier m55 : 49|1@1+ (1,0) [0|1] ""  gtw
 SG_ PM_a013_errorType m13 : 48|3@1+ (1,0) [0|5] ""  gtw
 SG_ PM_a028_w2 m28 : 48|8@1+ (1,0) [0|255] ""  gtw
 SG_ PM_a011_currentVref m11 : 48|11@1+ (0.005,0) [0|10.235] "V"  gtw
 SG_ PM_a003_w2 m3 : 48|16@1+ (1,0) [0|65535] ""  gtw
 SG_ PM_a034_motorRPM m34 : 48|16@1- (1,0) [-17000|17000] "RPM"  gtw
 SG_ PM_a027_w2 m27 : 48|16@1+ (1,0) [0|65535] ""  gtw
 SG_ PM_a005_w2 m5 : 48|16@1+ (1,0) [0|65535] ""  gtw
 SG_ PM_a012_badValue2 m12 : 48|16@1+ (1,0) [0|65535] ""  gtw
 SG_ PM_a052_brakeTorqueReR m52 : 48|7@1+ (128,0) [0|16256] "Nm"  gtw
 SG_ PM_a014_accelErrorType m14 : 48|2@1+ (1,0) [0|3] ""  gtw
 SG_ PM_a044_pmVehicleHoldState m44 : 48|3@1+ (1,0) [0|7] ""  gtw
 SG_ PM_a002_w2 m2 : 48|16@1+ (1,0) [0|65535] ""  gtw
 SG_ PM_a001_w2 m1 : 48|16@1+ (1,0) [0|65535] ""  gtw
 SG_ PM_a057_badValue2 m57 : 48|16@1+ (1,0) [0|65535] ""  gtw
 SG_ PM_a004_w2 m4 : 48|16@1+ (1,0) [0|65535] ""  gtw
 SG_ PM_a055_notReady m55 : 48|1@1+ (1,0) [0|1] ""  gtw
 SG_ PM_a038_pedalPos m38 : 48|8@1- (0.4,50.4) [0|100] "%"  gtw
 SG_ PM_a000_alertDataW2 m0 : 48|16@1+ (1,0) [0|65535] ""  X
 SG_ PM_a056_errorType m56 : 48|3@1+ (1,0) [0|5] ""  gtw
 SG_ PM_a044_diBrakeCommandType m44 : 45|3@1+ (1,0) [0|7] ""  gtw
 SG_ PM_a049_reversalYawIntegral m49 : 45|9@1+ (10,0) [0|5110] "Nm.s"  gtw
 SG_ PM_a050_reversalYawIntegral m50 : 45|8@1+ (20,0) [0|5100] "Nm.s"  gtw
 SG_ PM_a034_torqueType m34 : 45|2@1+ (1,0) [0|2] ""  gtw
 SG_ PM_a046_diBrakeCommandType m46 : 45|3@1+ (1,0) [0|7] ""  gtw
 SG_ PM_a051_vdcAllowedDecelTorque m51 : 44|10@1+ (10,0) [0|10235] "Nm"  gtw
 SG_ PM_a023_wheelSpdEstimateAbs m23 : 44|10@1+ (0.25,0) [0|255.75] "kph"  gtw
 SG_ PM_a031_stackSize m31 : 42|10@1+ (1,0) [0|1023] ""  gtw
 SG_ PM_a052_brakeTorqueReL m52 : 41|7@1+ (128,0) [0|16256] "Nm"  gtw
 SG_ PM_a055_commonGain m55 : 40|8@1+ (0.02,0) [0|5.1] "1"  gtw
 SG_ PM_a006_inputs m6 : 40|16@1+ (1,0) [0|65535] ""  gtw
 SG_ PM_a033_DSADC_Ib m33 : 40|16@1- (0.0939,0) [-3076.9152|3076.8213] "A"  gtw
 SG_ PM_a008_stackSize m8 : 40|16@1+ (1,0) [0|65535] ""  gtw
 SG_ PM_a010_DI_chassisControl m10 : 38|1@1+ (1,0) [0|1] ""  gtw
 SG_ PM_a010_DI_systemStatus m10 : 37|1@1+ (1,0) [0|1] ""  gtw
 SG_ PM_a049_reversalThreshold m49 : 36|9@1- (80,80) [-20400|20480] "Nm"  gtw
 SG_ PM_a010_DI_speed m10 : 36|1@1+ (1,0) [0|1] ""  gtw
 SG_ PM_a050_excessiveThreshold m50 : 36|9@1- (80,80) [-20400|20480] "Nm"  gtw
 SG_ PM_a010_DI_locStatus m10 : 35|1@1+ (1,0) [0|1] ""  gtw
 SG_ PM_a010_DI_slaveCommand m10 : 34|1@1+ (1,0) [0|1] ""  gtw
 SG_ PM_a051_masterCylinderPressure m51 : 34|10@1+ (0.3,-30) [-30|276.6] "bar"  gtw
 SG_ PM_a052_brakeTorqueFrR m52 : 34|7@1+ (128,0) [0|16256] "Nm"  gtw
 SG_ PM_a023_cruiseTorquePed m23 : 33|11@1- (1,0) [-1024|1023] "Nm"  gtw
 SG_ PM_a010_DI_torque m10 : 33|1@1+ (1,0) [0|1] ""  gtw
 SG_ PM_a031_stackUsedPrev m31 : 32|10@1+ (1,0) [0|1023] ""  gtw
 SG_ PM_a057_badValue1 m57 : 32|16@1+ (1,0) [0|65535] ""  gtw
 SG_ PM_a001_w1 m1 : 32|16@1+ (1,0) [0|65535] ""  gtw
 SG_ PM_a046_diBrakeTorqueCommand m46 : 32|13@1+ (2,0) [0|16382] "Nm"  gtw
 SG_ PM_a019_statorTslope1 m19 : 32|16@1- (0.1,0) [-3276.8|3276.7] "DegC/s"  gtw
 SG_ PM_a002_w1 m2 : 32|16@1+ (1,0) [0|65535] ""  gtw
 SG_ PM_a006_shiftState m6 : 32|3@1+ (1,0) [0|7] ""  gtw
 SG_ PM_a055_phaseAngle m55 : 32|8@1+ (0.00308,0) [0|0.7854] "1"  gtw
 SG_ PM_a012_badValue1 m12 : 32|16@1+ (1,0) [0|65535] ""  gtw
 SG_ PM_a030_diBrakeTorqueCommand m30 : 32|13@1+ (2,0) [0|16382] "Nm"  gtw
 SG_ PM_a034_parameterPM m34 : 32|13@1- (0.25,0.0) [-750|750] "Nm_or_%"  gtw
 SG_ PM_a013_canID m13 : 32|16@1+ (1,0) [0|65535] ""  gtw
 SG_ PM_a011_Ib m11 : 32|16@1- (0.0939,0) [-3076.9152|3076.8213] "A"  gtw
 SG_ PM_a000_alertDataW1 m0 : 32|16@1+ (1,0) [0|65535] ""  X
 SG_ PM_a044_diBrakeTorqueCommand m44 : 32|13@1+ (2,0) [0|16382] "Nm"  gtw
 SG_ PM_a003_w1 m3 : 32|16@1+ (1,0) [0|65535] ""  gtw
 SG_ PM_a056_canID m56 : 32|16@1+ (1,0) [0|65535] ""  gtw
 SG_ PM_a014_track2Voltage m14 : 32|16@1+ (0.001,0) [0|65.535] "V"  gtw
 SG_ PM_a004_w1 m4 : 32|16@1+ (1,0) [0|65535] ""  gtw
 SG_ PM_a010_DI_status m10 : 32|1@1+ (1,0) [0|1] ""  gtw
 SG_ PM_a028_w1 m28 : 32|16@1+ (1,0) [0|65535] ""  gtw
 SG_ PM_a038_slaveTorque m38 : 32|13@1- (0.4,0.0) [-1638.4|1638] "Nm"  gtw
 SG_ PM_a027_w1 m27 : 32|16@1+ (1,0) [0|65535] ""  gtw
 SG_ PM_a005_w1 m5 : 32|16@1+ (1,0) [0|65535] ""  gtw
 SG_ PM_a046_vhldCancelReason m46 : 31|1@1+ (1,0) [0|1] ""  gtw
 SG_ PM_a030_aebCancelReason m30 : 30|2@1+ (1,0) [0|2] ""  gtw
 SG_ PM_a023_crsCancelReason m23 : 29|4@1+ (1,0) [0|10] ""  gtw
 SG_ PM_a026_switchingActive m26 : 29|1@1+ (1,0) [0|1] ""  gtw
 SG_ PM_a057_errorType m57 : 28|3@1+ (1,0) [0|6] ""  gtw
 SG_ PM_a012_errorType m12 : 28|3@1+ (1,0) [0|6] ""  gtw
 SG_ PM_a046_vhldUnavailableReason m46 : 27|4@1+ (1,0) [0|9] ""  gtw
 SG_ PM_a043_brakeHWType m43 : 27|1@1+ (1,0) [0|1] ""  gtw
 SG_ PM_a030_aebUnavailableReason m30 : 27|3@1+ (1,0) [0|7] ""  gtw
 SG_ PM_a052_brakeTorqueFrL m52 : 27|7@1+ (128,0) [0|16256] "Nm"  gtw
 SG_ PM_a044_diAebState m44 : 27|3@1+ (1,0) [0|7] ""  gtw
 SG_ PM_a052_controllingReR m52 : 26|1@1+ (1,0) [0|1] ""  gtw
 SG_ PM_a050_yawRateError m50 : 26|10@1- (0.008,0.008) [-4.088|4.096] "rad/s"  gtw
 SG_ PM_a049_yawRateError m49 : 26|10@1- (0.008,0.008) [-4.088|4.096] "rad/s"  gtw
 SG_ PM_a043_expectedVdcType m43 : 26|1@1+ (1,0) [0|1] ""  gtw
 SG_ PM_a043_GTW_vdcType m43 : 25|1@1+ (1,0) [0|1] ""  gtw
 SG_ PM_a052_controllingReL m52 : 25|1@1+ (1,0) [0|1] ""  gtw
 SG_ PM_a051_maxDecelTorque m51 : 25|9@1+ (20,0) [0|10220] "Nm"  gtw
 SG_ PM_a043_performancePackage m43 : 24|1@1+ (1,0) [0|1] ""  gtw
 SG_ PM_a023_crsFaultReason m23 : 24|5@1+ (1,0) [0|18] ""  gtw
 SG_ PM_a040_messageId m40 : 24|16@1+ (1,0) [0|65535] ""  gtw
 SG_ PM_a052_controllingFrR m52 : 24|1@1+ (1,0) [0|1] ""  gtw
 SG_ PM_a046_vhldFaultReason m46 : 24|3@1+ (1,0) [0|7] ""  gtw
 SG_ PM_a033_DSADC_Ia m33 : 24|16@1- (0.0939,0) [-3076.9152|3076.8213] "A"  gtw
 SG_ PM_a047_autoparkCancelReason m47 : 24|2@1+ (1,0) [0|3] ""  gtw
 SG_ PM_a030_aebFaultReason m30 : 24|3@1+ (1,0) [0|6] ""  gtw
 SG_ PM_a061_pmIpcVersion m61 : 24|8@1+ (1,0) [0|255] ""  gtw
 SG_ PM_a026_isrCount m26 : 24|5@1+ (1,0) [0|31] ""  gtw
 SG_ PM_a044_pmAebState m44 : 24|3@1+ (1,0) [0|7] ""  gtw
 SG_ PM_a039_messageId m39 : 24|16@1+ (1,0) [0|65535] ""  gtw
 SG_ PM_a008_stackUsed m8 : 24|16@1+ (1,0) [0|65535] ""  gtw
 SG_ PM_a052_controllingFrL m52 : 23|1@1+ (1,0) [0|1] ""  gtw
 SG_ PM_a043_packEnergy m43 : 23|1@1+ (1,0) [0|1] ""  gtw
 SG_ PM_a026_diWdtUdsRqst m26 : 23|1@1+ (1,0) [0|1] ""  gtw
 SG_ PM_a030_dasAebEvent m30 : 22|2@1+ (1,0) [0|3] ""  gtw
 SG_ PM_a031_stackUsed m31 : 22|10@1+ (1,0) [0|1023] ""  gtw
 SG_ PM_a026_diLoopRunning m26 : 22|1@1+ (1,0) [0|1] ""  gtw
 SG_ PM_a026_diWdtHWEvent m26 : 21|1@1+ (1,0) [0|1] ""  gtw
 SG_ PM_a043_expectedDrivetrainType m43 : 21|2@1+ (1,0) [0|3] ""  gtw
 SG_ PM_a064_torqueCmdState m64 : 20|4@1+ (1,0) [0|8] ""  gtw
 SG_ PM_a023_pmCrsState m23 : 20|4@1+ (1,0) [0|15] ""  gtw
 SG_ PM_a047_diAutoparkState m47 : 20|4@1+ (1,0) [0|15] ""  gtw
 SG_ PM_a033_failReason m33 : 20|3@1+ (1,0) [0|7] ""  gtw
 SG_ PM_a026_diWdt1kHz m26 : 20|1@1+ (1,0) [0|1] ""  gtw
 SG_ PM_a044_diCruiseState m44 : 20|4@1+ (1,0) [0|15] ""  gtw
 SG_ PM_a030_pmAebState m30 : 19|3@1+ (1,0) [0|7] ""  gtw
 SG_ PM_a046_pmVhldState m46 : 19|3@1+ (1,0) [0|7] ""  gtw
 SG_ PM_a026_diWdt100Hz m26 : 19|1@1+ (1,0) [0|1] ""  gtw
 SG_ PM_a043_GTW_drivetrainType m43 : 19|2@1+ (1,0) [0|3] ""  gtw
 SG_ PM_a026_diWdt10Hz m26 : 18|1@1+ (1,0) [0|1] ""  gtw
 SG_ PM_a042_expectedPerformanceCfg m42 : 18|1@1+ (1,0) [0|1] ""  gtw
 SG_ PM_a043_expectedAutopilot m43 : 18|1@1+ (1,0) [0|1] ""  gtw
 SG_ PM_a009_ESP_party3 m9 : 18|1@1+ (1,0) [0|1] ""  gtw
 SG_ PM_a054_uiChassisControl m54 : 17|1@1+ (1,0) [0|1] ""  gtw
 SG_ PM_a053_coolant m53 : 17|1@1+ (1,0) [0|1] ""  gtw
 SG_ PM_a009_ESP_status m9 : 17|1@1+ (1,0) [0|1] ""  gtw
 SG_ PM_a042_GTW_drivetrainType m42 : 17|1@1+ (1,0) [0|1] ""  gtw
 SG_ PM_a039_DIS_torque m39 : 17|1@1+ (1,0) [0|1] ""  gtw
 SG_ PM_a043_GTW_autopilot m43 : 17|1@1+ (1,0) [0|1] ""  gtw
 SG_ PM_a026_diWdtIdle m26 : 17|1@1+ (1,0) [0|1] ""  gtw
 SG_ PM_a017_EPBR_status m17 : 17|1@1+ (1,0) [0|1] ""  gtw
 SG_ PM_a054_uiPowertrainControl m54 : 16|1@1+ (1,0) [0|1] ""  gtw
 SG_ PM_a002_w0 m2 : 16|16@1+ (1,0) [0|65535] ""  gtw
 SG_ PM_a005_w0 m5 : 16|16@1+ (1,0) [0|65535] ""  gtw
 SG_ PM_a056_mailboxID m56 : 16|16@1+ (1,0) [0|65535] ""  gtw
 SG_ PM_a027_w0 m27 : 16|16@1+ (1,0) [0|65535] ""  gtw
 SG_ PM_a039_DIS_status m39 : 16|1@1+ (1,0) [0|1] ""  gtw
 SG_ PM_a030_diAebState m30 : 16|3@1+ (1,0) [0|7] ""  gtw
 SG_ PM_a042_GTW_carConfig m42 : 16|1@1+ (1,0) [0|1] ""  gtw
 SG_ PM_a064_interventionType m64 : 16|4@1+ (1,0) [0|10] ""  gtw
 SG_ PM_a000_alertDataW0 m0 : 16|16@1+ (1,0) [0|65535] ""  X
 SG_ PM_a052_duration m52 : 16|7@1+ (0.04,0) [0|5.125] "s"  gtw
 SG_ PM_a059_PTC_feedbackStatus m59 : 16|1@1+ (1,0) [0|1] ""  gtw
 SG_ PM_a014_track1Voltage m14 : 16|16@1+ (0.001,0) [0|65.535] "V"  gtw
 SG_ PM_a023_diCrsState m23 : 16|4@1+ (1,0) [0|15] ""  gtw
 SG_ PM_a047_pmAutoparkState m47 : 16|4@1+ (1,0) [0|15] ""  gtw
 SG_ PM_a058_CMP_HVStatus m58 : 16|1@1+ (1,0) [0|1] ""  gtw
 SG_ PM_a017_EPBL_status m17 : 16|1@1+ (1,0) [0|1] ""  gtw
 SG_ PM_a001_w0 m1 : 16|16@1+ (1,0) [0|65535] ""  gtw
 SG_ PM_a046_diVhldState m46 : 16|3@1+ (1,0) [0|7] ""  gtw
 SG_ PM_a057_canID m57 : 16|12@1+ (1,0) [0|4095] ""  gtw
 SG_ PM_a004_w0 m4 : 16|16@1+ (1,0) [0|65535] ""  gtw
 SG_ PM_a049_measuredTorqueInTurn m49 : 16|10@1- (40,80) [-20400|20480] "Nm"  gtw
 SG_ PM_a050_measuredTorqueInTurn m50 : 16|10@1- (40,80) [-20400|20480] "Nm"  gtw
 SG_ PM_a041_DAS_control m41 : 16|1@1+ (1,0) [0|1] ""  gtw
 SG_ PM_a034_parameterDI m34 : 16|13@1- (0.25,0.0) [-750|750] "Nm_or_%"  gtw
 SG_ PM_a026_reason m26 : 16|1@1+ (1,0) [0|1] ""  gtw
 SG_ PM_a028_w0 m28 : 16|16@1+ (1,0) [0|65535] ""  gtw
 SG_ PM_a051_duration m51 : 16|9@1+ (0.02,0) [0|10.25] "s"  gtw
 SG_ PM_a061_diIpcVersion m61 : 16|8@1+ (1,0) [0|255] ""  gtw
 SG_ PM_a012_canID m12 : 16|12@1+ (1,0) [0|4095] ""  gtw
 SG_ PM_a043_configInconsistent m43 : 16|1@1+ (1,0) [0|1] ""  gtw
 SG_ PM_a019_statorTemp1 m19 : 16|16@1- (0.1,0) [-3276.8|3276.7] "DegC"  gtw
 SG_ PM_a031_taskID m31 : 16|6@1+ (1,0) [0|63] ""  gtw
 SG_ PM_a009_ESP_wheelSpeeds m9 : 16|1@1+ (1,0) [0|1] ""  gtw
 SG_ PM_a033_state m33 : 16|4@1+ (1,0) [0|11] ""  gtw
 SG_ PM_a038_masterTorque m38 : 16|13@1- (0.4,0.0) [-1638.4|1638] "Nm"  gtw
 SG_ PM_a010_messageId m10 : 16|16@1+ (1,0) [0|65535] ""  gtw
 SG_ PM_a003_w0 m3 : 16|16@1+ (1,0) [0|65535] ""  gtw
 SG_ PM_a006_gearsAllowed m6 : 16|16@1+ (1,0) [0|65535] ""  gtw
 SG_ PM_a015_SCCM_rightStalk m15 : 16|1@1+ (1,0) [0|1] ""  gtw
 SG_ PM_a055_motorRPM m55 : 16|16@1- (1,0) [-20000|20000] "RPM"  gtw
 SG_ PM_a053_LVPowerState m53 : 16|1@1+ (1,0) [0|1] ""  gtw
 SG_ PM_a040_PM_state m40 : 16|1@1+ (1,0) [0|1] ""  gtw
 SG_ PM_a044_pmCruiseState m44 : 16|4@1+ (1,0) [0|15] ""  gtw
 SG_ PM_a048_vdcFaultReason m48 : 16|3@1+ (1,0) [0|6] ""  gtw
 SG_ PM_a013_mailboxID m13 : 16|16@1+ (1,0) [0|65535] ""  gtw
 SG_ PM_a008_taskID m8 : 16|8@1+ (1,0) [0|255] ""  gtw
 SG_ PM_a011_Ia m11 : 16|16@1- (0.0939,0) [-3076.9152|3076.8213] "A"  gtw
 SG_ PM_alertType : 15|1@1+ (1,0) [0|1] ""  gtw
 SG_ PM_alertID M : 0|7@1+ (1,0) [0|64] ""  gtw

BO_ 1948 XCP_epbrRequest: 8 VEH
 SG_ XCP_epbrRequest : 7|64@0+ (1,0) [0|18446744073709551615] ""  epbr

BO_ 1318 DI_alertLog: 8 VEH
 SG_ DI_a153_spiError m153 : 63|1@1+ (1,0) [0|1] ""  gtw
 SG_ DI_a153_pumpTempIrrational m153 : 62|1@1+ (1,0) [0|1] ""  gtw
 SG_ DI_a014_tcEnabled m14 : 62|1@1+ (1,0) [0|1] ""  gtw
 SG_ DI_a153_pumpOverTemp m153 : 61|1@1+ (1,0) [0|1] ""  gtw
 SG_ DI_a199_vdcMode m199 : 61|2@1+ (1,0) [0|2] ""  gtw
 SG_ DI_a153_motorStall m153 : 60|1@1+ (1,0) [0|1] ""  gtw
 SG_ DI_a218_preControlActivationGain m218 : 60|4@1+ (0.1,0) [0|1.5] "rad/s"  gtw
 SG_ DI_a199_understeerdMzActive m199 : 60|1@1+ (1,0) [0|1] ""  gtw
 SG_ DI_a066_errorType m66 : 60|3@1+ (1,0) [0|6] ""  gtw
 SG_ DI_a199_decelControlActive m199 : 59|1@1+ (1,0) [0|1] ""  gtw
 SG_ DI_a153_motorSpeedTooHigh m153 : 59|1@1+ (1,0) [0|1] ""  gtw
 SG_ DI_a221_understeerdMzYawRateErro m221 : 58|6@1+ (0.006,0) [0|0.37] "rad/s"  gtw
 SG_ DI_a220_understeerDecelInitThres m220 : 58|6@1+ (0.006,0) [0|0.37] "rad/s"  gtw
 SG_ DI_a219_oversteerYawRateError m219 : 58|6@1- (0.006,-0.18) [-0.37|0] "rad/s"  gtw
 SG_ DI_a199_oversteerdMzActive m199 : 58|1@1+ (1,0) [0|1] ""  gtw
 SG_ DI_a153_motorSpeedIrrational m153 : 58|1@1+ (1,0) [0|1] ""  gtw
 SG_ DI_a199_preControlActive m199 : 57|1@1+ (1,0) [0|1] ""  gtw
 SG_ DI_a153_motorOverload m153 : 57|1@1+ (1,0) [0|1] ""  gtw
 SG_ DI_a024_rotorAngle m24 : 57|7@1- (3,0) [-180|180] "degrees"  gtw
 SG_ DI_a162_timeSinceCruiseCancel m162 : 56|7@1+ (0.5,0) [0|60] "second"  gtw
 SG_ DI_a135_vhldGrade m135 : 56|8@1+ (0.01,-1) [-1|1] "G"  gtw
 SG_ DI_a159_ESP_ebrStatus m159 : 56|2@1+ (1,0) [0|3] ""  gtw
 SG_ DI_a153_motorCurrentIrrational m153 : 56|1@1+ (1,0) [0|1] ""  gtw
 SG_ DI_a115_motorRPM m115 : 56|8@1- (150,0) [-17000|17000] "RPM"  gtw
 SG_ DI_a223_regenTCActive m223 : 55|1@1+ (1,0) [0|1] ""  gtw
 SG_ DI_a154_claMIA m154 : 55|1@1+ (1,0) [0|1] ""  gtw
 SG_ DI_a153_motorControl m153 : 55|1@1+ (1,0) [0|1] ""  gtw
 SG_ DI_a223_driveTCActive m223 : 54|1@1+ (1,0) [0|1] ""  gtw
 SG_ DI_a154_trackerIrrational m154 : 54|1@1+ (1,0) [0|1] ""  gtw
 SG_ DI_a153_memoryError m153 : 54|1@1+ (1,0) [0|1] ""  gtw
 SG_ DI_a218_vehicleVelocity m218 : 54|6@1+ (1,0) [0|62] "m/s"  gtw
 SG_ DI_a207_driverTorqueFrCurrVal m207 : 53|10@1- (14.649,0.0) [-7500|7500] "Nm"  gtw
 SG_ DI_a204_rollRateCurrVal m204 : 53|10@1- (0.006,0.0) [-3.2766|3.2766] "rad/s"  gtw
 SG_ DI_a215_wheelSpeedNonCGReRCurrVa m215 : 53|10@1- (0.11,35.09) [-20|90] "m/s"  gtw
 SG_ DI_a003_selftestDesat_H m3 : 53|1@1+ (1,0) [0|1] ""  gtw
 SG_ DI_a208_driverTorqueReCurrVal m208 : 53|10@1- (14.649,0.0) [-7500|7500] "Nm"  gtw
 SG_ DI_a205_pitchRateCurrVal m205 : 53|10@1- (0.006,0.0) [-3.2766|3.2766] "rad/s"  gtw
 SG_ DI_a195_wheelSlipFrRCurrValue m195 : 53|10@1+ (0.001,0) [0|1] "1"  gtw
 SG_ DI_a194_brakeTorqueReRCurrVal m194 : 53|10@1+ (8,0) [0|8190] "Nm"  gtw
 SG_ DI_a196_wheelSlipReRCurrValue m196 : 53|10@1+ (0.001,0) [0|1] "1"  gtw
 SG_ DI_a002_selftestDesat_H m2 : 53|1@1+ (1,0) [0|1] ""  gtw
 SG_ DI_a213_wheelSpeedCGReRCurrVal m213 : 53|10@1- (0.11,35.09) [-20|90] "m/s"  gtw
 SG_ DI_a212_wheelSpeedCGFrRCurrVal m212 : 53|10@1- (0.11,35.09) [-20|90] "m/s"  gtw
 SG_ DI_a193_brakeTorqueFrRCurrVal m193 : 53|10@1+ (8,0) [0|8189] "Nm"  gtw
 SG_ DI_a206_yawRateCurrVal m206 : 53|10@1- (0.006,0.0) [-3.2766|3.2766] "rad/s"  gtw
 SG_ DI_a211_motorSpeedReCurrVal m211 : 53|10@1- (0.11,35.09) [-20|90] "m/s"  gtw
 SG_ DI_a198_steeringAngleCurrVal m198 : 53|10@1- (1.6,0.0) [-819.2|819] "deg"  gtw
 SG_ DI_a154_carrierOffset m154 : 53|1@1+ (1,0) [0|1] ""  gtw
 SG_ DI_a153_linIDParityError m153 : 53|1@1+ (1,0) [0|1] ""  gtw
 SG_ DI_a214_wheelSpeedNonCGFrRCurrVa m214 : 53|10@1- (0.11,35.09) [-20|90] "m/s"  gtw
 SG_ DI_a001_selftestDesat_H m1 : 53|1@1+ (1,0) [0|1] ""  gtw
 SG_ DI_a001_selftestDesat_L m1 : 52|1@1+ (1,0) [0|1] ""  gtw
 SG_ DI_a220_vehicleVelocity m220 : 52|6@1+ (1,0) [0|62] "m/s"  gtw
 SG_ DI_a153_linFramingError m153 : 52|1@1+ (1,0) [0|1] ""  gtw
 SG_ DI_a014_rmsTorqueError m14 : 52|10@1+ (1,0) [0|750] "Nm"  gtw
 SG_ DI_a221_vehicleVelocity m221 : 52|6@1+ (1,0) [0|62] "m/s"  gtw
 SG_ DI_a219_vehicleVelocity m219 : 52|6@1+ (1,0) [0|62] "m/s"  gtw
 SG_ DI_a003_selftestDesat_L m3 : 52|1@1+ (1,0) [0|1] ""  gtw
 SG_ DI_a134_wheelSpeedDiffReR m134 : 52|12@1- (0.0625,0) [-256|255] "kph"  gtw
 SG_ DI_a038_reason m38 : 52|2@1+ (1,0) [0|2] ""  gtw
 SG_ DI_a154_errorTableInvalid m154 : 52|1@1+ (1,0) [0|1] ""  gtw
 SG_ DI_a002_selftestDesat_L m2 : 52|1@1+ (1,0) [0|1] ""  gtw
 SG_ DI_a223_musurfHigh m223 : 51|3@1+ (0.15,0.15) [0.15|1.2] "-"  gtw
 SG_ DI_a153_linDataError m153 : 51|1@1+ (1,0) [0|1] ""  gtw
 SG_ DI_a162_requestedGear m162 : 51|3@1+ (1,0) [0|7] ""  gtw
 SG_ DI_a154_notReady m154 : 51|1@1+ (1,0) [0|1] ""  gtw
 SG_ DI_a115_sensors m115 : 51|2@1+ (1,0) [0|3] ""  gtw
 SG_ DI_a154_noCarrier m154 : 50|1@1+ (1,0) [0|1] ""  gtw
 SG_ DI_a199_sensorYawRate m199 : 50|7@1- (0.024,0.0) [-1.5|1.5] "rad/s"  gtw
 SG_ DI_a153_linChecksumError m153 : 50|1@1+ (1,0) [0|1] ""  gtw
 SG_ DI_a153_fluidTempIrrational m153 : 49|1@1+ (1,0) [0|1] ""  gtw
 SG_ DI_a154_noPhaseLock m154 : 49|1@1+ (1,0) [0|1] ""  gtw
 SG_ DI_a058_pcbTempSlope m58 : 48|8@1- (0.5,0) [-64|63.5] "DegC/s"  gtw
 SG_ DI_a035_frequency m35 : 48|10@1+ (1,0) [0|255] "Hz"  gtw
 SG_ DI_a121_badFlux m121 : 48|16@1+ (0.0001,0) [0|6.5535] "Wb"  gtw
 SG_ DI_a133_badValue2 m133 : 48|16@1- (0.1,0) [-3276.8|3276.7] "C"  gtw
 SG_ DI_a033_vRefIa m33 : 48|16@1- (0.001,0) [-32.768|32.767] "V"  gtw
 SG_ DI_a170_driverCommand m170 : 48|13@1- (0.25,0.0) [-750|750] "Nm"  gtw
 SG_ DI_a103_rmsCurrent m103 : 48|16@1- (0.1,-0.4) [-3276|3275] "A"  gtw
 SG_ DI_a153_fluidPressureLow m153 : 48|1@1+ (1,0) [0|1] ""  gtw
 SG_ DI_a066_canID m66 : 48|12@1+ (1,0) [0|4095] ""  gtw
 SG_ DI_a003_gateDriveErrCounter m3 : 48|4@1+ (1,0) [0|15] ""  gtw
 SG_ DI_a028_iArmsSpeed m28 : 48|16@1+ (1,0) [0|65535] "RPM"  gtw
 SG_ DI_a027_motorSpeed m27 : 48|16@1+ (1,0) [0|65535] "RPM"  gtw
 SG_ DI_a223_musurf m223 : 48|3@1+ (0.15,0.15) [0.15|1.2] "-"  gtw
 SG_ DI_a150_energy m150 : 48|16@1+ (1,0) [0|65535] "J"  gtw
 SG_ DI_a094_badValue2 m94 : 48|16@1+ (1,0) [0|65535] ""  gtw
 SG_ DI_a034_vRefIb m34 : 48|16@1- (0.001,0) [-32.768|32.767] "V"  gtw
 SG_ DI_a029_iBrmsSpeed m29 : 48|16@1+ (1,0) [0|65535] "RPM"  gtw
 SG_ DI_a099_cpuUsage1kHz m99 : 48|8@1+ (1,0) [0|255] "%"  gtw
 SG_ DI_a045_outletTempSlope m45 : 48|8@1- (0.5,0) [-64|63.5] "DegC/s"  gtw
 SG_ DI_a131_warnTimeRemaining m131 : 48|16@1+ (1,0) [0|65535] ""  gtw
 SG_ DI_a002_gateDriveErrCounter m2 : 48|4@1+ (1,0) [0|15] ""  gtw
 SG_ DI_a160_energy m160 : 48|16@1+ (1,0) [0|65535] "J"  gtw
 SG_ DI_a162_currentGear m162 : 48|3@1+ (1,0) [0|7] ""  gtw
 SG_ DI_a074_motorSpeed2 m74 : 48|16@1- (1,0) [-17000|17000] "RPM"  gtw
 SG_ DI_a042_inletTempSlope m42 : 48|8@1- (0.5,0) [-64|63.5] "DegC/s"  gtw
 SG_ DI_a030_iCrmsSpeed m30 : 48|16@1+ (1,0) [0|65535] "RPM"  gtw
 SG_ DI_a125_minBusVoltage m125 : 48|16@1+ (0.1,0) [0|6553.5] "V"  gtw
 SG_ DI_a093_errorType m93 : 48|1@1+ (1,0) [0|1] ""  gtw
 SG_ DI_a149_responseError m149 : 48|1@1+ (1,0) [0|1] ""  gtw
 SG_ DI_a055_motorRPM m55 : 48|16@1- (1,0) [-17000|17000] "RPM"  gtw
 SG_ DI_a113_ph3Temp m113 : 48|16@1- (0.1,0) [-3276.8|3276.7] "C"  gtw
 SG_ DI_a232_steerAngleValid m232 : 48|1@1+ (1,0) [0|1] ""  gtw
 SG_ DI_a011_codeBranch m11 : 48|4@1+ (1,0) [0|15] ""  gtw
 SG_ DI_a172_timeSinceCruiseCancel m172 : 48|7@1+ (0.5,0) [0|60] "second"  gtw
 SG_ DI_a159_crsUi m159 : 48|8@1- (4,0) [-512|508] "Nm"  gtw
 SG_ DI_a001_gateDriveErrCounter m1 : 48|4@1+ (1,0) [0|15] ""  gtw
 SG_ DI_a000_alertDataW2 m0 : 48|16@1+ (1,0) [0|65535] ""  X
 SG_ DI_a154_noCalibration m154 : 48|1@1+ (1,0) [0|1] ""  gtw
 SG_ DI_a025_motorSpeed m25 : 48|16@1+ (1,0) [0|65535] "RPM"  gtw
 SG_ DI_a026_motorSpeed m26 : 48|16@1+ (1,0) [0|65535] "RPM"  gtw
 SG_ DI_a149_motorSpeedSNA m149 : 47|1@1+ (1,0) [0|1] ""  gtw
 SG_ DI_a003_deadtimeError_L m3 : 47|1@1+ (1,0) [0|1] ""  gtw
 SG_ DI_a002_deadtimeError_L m2 : 47|1@1+ (1,0) [0|1] ""  gtw
 SG_ DI_a148_overtorque2Mode m148 : 47|1@1+ (1,0) [0|1] ""  gtw
 SG_ DI_a153_fluidPressureIrrat m153 : 47|1@1+ (1,0) [0|1] ""  gtw
 SG_ DI_a001_deadtimeError_L m1 : 47|1@1+ (1,0) [0|1] ""  gtw
 SG_ DI_a232_yawRateValid m232 : 47|1@1+ (1,0) [0|1] ""  gtw
 SG_ DI_a224_brakeRRTemp m224 : 46|10@1- (1,300) [-100|700] "degC"  gtw
 SG_ DI_a232_longitudinalAccelValid m232 : 46|1@1+ (1,0) [0|1] ""  gtw
 SG_ DI_a153_fluidPressureHigh m153 : 46|1@1+ (1,0) [0|1] ""  gtw
 SG_ DI_a148_wearIsValid m148 : 46|1@1+ (1,0) [0|1] ""  gtw
 SG_ DI_a003_spiError_L m3 : 46|1@1+ (1,0) [0|1] ""  gtw
 SG_ DI_a149_motorShorted m149 : 46|1@1+ (1,0) [0|1] ""  gtw
 SG_ DI_a002_spiError_L m2 : 46|1@1+ (1,0) [0|1] ""  gtw
 SG_ DI_a001_spiError_L m1 : 46|1@1+ (1,0) [0|1] ""  gtw
 SG_ DI_a003_localRegError_L m3 : 45|1@1+ (1,0) [0|1] ""  gtw
 SG_ DI_a218_predictedYawRateError m218 : 45|9@1- (0.006,0.0) [-1.5|1.5] "rad/s"  gtw
 SG_ DI_a002_localRegError_L m2 : 45|1@1+ (1,0) [0|1] ""  gtw
 SG_ DI_a149_motorOpenPhase m149 : 45|1@1+ (1,0) [0|1] ""  gtw
 SG_ DI_a153_ecuReset m153 : 45|1@1+ (1,0) [0|1] ""  gtw
 SG_ DI_a024_maxCurrMagSqrd m24 : 45|12@1+ (500,0) [0|1960000] "A2"  gtw
 SG_ DI_a055_torqueType m55 : 45|2@1+ (1,0) [0|2] ""  gtw
 SG_ DI_a001_localRegError_L m1 : 45|1@1+ (1,0) [0|1] ""  gtw
 SG_ DI_a135_vhldPropulsiveTorque m135 : 45|10@1- (1,0) [-500|500] "Nm"  gtw
 SG_ DI_a199_vehicleVelocity m199 : 45|5@1+ (2,0) [0|62] "m/s"  gtw
 SG_ DI_a232_lateralAccelValid m232 : 45|1@1+ (1,0) [0|1] ""  gtw
 SG_ DI_a001_overvoltVDD_L m1 : 44|1@1+ (1,0) [0|1] ""  gtw
 SG_ DI_a149_insufficientFlow m149 : 44|1@1+ (1,0) [0|1] ""  gtw
 SG_ DI_a153_12vSupplyUV m153 : 44|1@1+ (1,0) [0|1] ""  gtw
 SG_ DI_a147_wearIsValid m147 : 44|1@1+ (1,0) [0|1] ""  gtw
 SG_ DI_a232_DIS_torqueMotorValid m232 : 44|1@1+ (1,0) [0|1] ""  gtw
 SG_ DI_a003_overvoltVDD_L m3 : 44|1@1+ (1,0) [0|1] ""  gtw
 SG_ DI_a041_reason m41 : 44|1@1+ (1,0) [0|1] ""  gtw
 SG_ DI_a002_overvoltVDD_L m2 : 44|1@1+ (1,0) [0|1] ""  gtw
 SG_ DI_a221_understeerdMzYawRateTar m221 : 43|9@1- (0.006,0.0) [-1.5|1.5] "rad/s"  gtw
 SG_ DI_a215_wheelSpeedNonCGReRLastVa m215 : 43|10@1- (0.11,35.09) [-20|90] "m/s"  gtw
 SG_ DI_a001_undervoltVDD_L m1 : 43|1@1+ (1,0) [0|1] ""  gtw
 SG_ DI_a194_brakeTorqueReRLastVal m194 : 43|10@1+ (8,0) [0|8190] "Nm"  gtw
 SG_ DI_a196_wheelSlipReRLastValue m196 : 43|10@1+ (0.001,0) [0|1] "1"  gtw
 SG_ DI_a195_wheelSlipFrRLastValue m195 : 43|10@1+ (0.001,0) [0|1] "1"  gtw
 SG_ DI_a220_understeerDecelYawRateTa m220 : 43|9@1- (0.006,0.0) [-1.5|1.5] "rad/s"  gtw
 SG_ DI_a213_wheelSpeedCGReRLastVal m213 : 43|10@1- (0.11,35.09) [-20|90] "m/s"  gtw
 SG_ DI_a212_wheelSpeedCGFrRLastVal m212 : 43|10@1- (0.11,35.09) [-20|90] "m/s"  gtw
 SG_ DI_a002_undervoltVDD_L m2 : 43|1@1+ (1,0) [0|1] ""  gtw
 SG_ DI_a204_rollRateLastVal m204 : 43|10@1- (0.006,0.0) [-3.2766|3.2766] "rad/s"  gtw
 SG_ DI_a153_12vSupplyOV m153 : 43|1@1+ (1,0) [0|1] ""  gtw
 SG_ DI_a198_steeringAngleLastVal m198 : 43|10@1- (1.6,0.0) [-819.2|819] "deg"  gtw
 SG_ DI_a205_pitchRateLastVal m205 : 43|10@1- (0.006,0.0) [-3.2766|3.2766] "rad/s"  gtw
 SG_ DI_a232_OversteerActiveValid m232 : 43|1@1+ (1,0) [0|1] ""  gtw
 SG_ DI_a208_driverTorqueReLastVal m208 : 43|10@1- (14.649,0.0) [-7500|7500] "Nm"  gtw
 SG_ DI_a003_undervoltVDD_L m3 : 43|1@1+ (1,0) [0|1] ""  gtw
 SG_ DI_a214_wheelSpeedNonCGFrRLastVa m214 : 43|10@1- (0.11,35.09) [-20|90] "m/s"  gtw
 SG_ DI_a149_fluidTempSNA m149 : 43|1@1+ (1,0) [0|1] ""  gtw
 SG_ DI_a207_driverTorqueFrLastVal m207 : 43|10@1- (14.649,0.0) [-7500|7500] "Nm"  gtw
 SG_ DI_a193_brakeTorqueFrRLastVal m193 : 43|10@1+ (8,0) [0|8189] "Nm"  gtw
 SG_ DI_a219_oversteerYawRateTar m219 : 43|9@1- (0.006,0.0) [-1.5|1.5] "rad/s"  gtw
 SG_ DI_a211_motorSpeedReLastVal m211 : 43|10@1- (0.11,35.09) [-20|90] "m/s"  gtw
 SG_ DI_a206_yawRateLastVal m206 : 43|10@1- (0.006,0.0) [-3.2766|3.2766] "rad/s"  gtw
 SG_ DI_a002_remoteRegError_L m2 : 42|1@1+ (1,0) [0|1] ""  gtw
 SG_ DI_a232_UndersteerActiveValid m232 : 42|1@1+ (1,0) [0|1] ""  gtw
 SG_ DI_a001_remoteRegError_L m1 : 42|1@1+ (1,0) [0|1] ""  gtw
 SG_ DI_a153_12vSupplyIrrational m153 : 42|1@1+ (1,0) [0|1] ""  gtw
 SG_ DI_a014_brakeMasterCylPress m14 : 42|10@1+ (0.25,-42.5) [-42.5|213.25] "bar"  gtw
 SG_ DI_a003_remoteRegError_L m3 : 42|1@1+ (1,0) [0|1] ""  gtw
 SG_ DI_a002_asynchStop_L m2 : 41|1@1+ (1,0) [0|1] ""  gtw
 SG_ DI_a001_asynchStop_L m1 : 41|1@1+ (1,0) [0|1] ""  gtw
 SG_ DI_a232_AbsBrakeEventActiveValid m232 : 41|1@1+ (1,0) [0|1] ""  gtw
 SG_ DI_a003_asynchStop_L m3 : 41|1@1+ (1,0) [0|1] ""  gtw
 SG_ DI_a097_argument m97 : 40|16@1+ (1,0) [0|65535] ""  gtw
 SG_ DI_a136_badValue2 m136 : 40|16@1+ (1,0) [0|65535] ""  gtw
 SG_ DI_a193_brakeTorqueFrR m193 : 40|3@1+ (1,0) [0|7] ""  gtw
 SG_ DI_a185_apcIntState m185 : 40|8@1+ (1,0) [0|255] ""  gtw
 SG_ DI_a207_driverTorqueFr m207 : 40|3@1+ (1,0) [0|7] ""  gtw
 SG_ DI_a115_motorCurrent m115 : 40|11@1+ (1,0) [0|2047] "A"  gtw
 SG_ DI_a187_systemTorqueCommand m187 : 40|16@1- (1,0) [-32768|32767] "Nm"  gtw
 SG_ DI_a215_wheelSpeedNonCGReR m215 : 40|3@1+ (1,0) [0|7] ""  gtw
 SG_ DI_a172_currentGear m172 : 40|3@1+ (1,0) [0|7] ""  gtw
 SG_ DI_a154_commonGain m154 : 40|8@1+ (0.02,0) [0|5.1] "1"  gtw
 SG_ DI_a189_motorSpeed m189 : 40|5@1- (0.5,0) [-8|7.5] "MPH"  gtw
 SG_ DI_a011_badDataExpected m11 : 40|8@1+ (1,0) [0|255] ""  gtw
 SG_ DI_a211_motorSpeedRe m211 : 40|3@1+ (1,0) [0|7] ""  gtw
 SG_ DI_a206_yawRate m206 : 40|3@1+ (1,0) [0|7] ""  gtw
 SG_ DI_a156_motorRPM m156 : 40|16@1- (1,0) [-20000|20000] "RPM"  gtw
 SG_ DI_a194_brakeTorqueReR m194 : 40|3@1+ (1,0) [0|7] ""  gtw
 SG_ DI_a003_gateOn_L m3 : 40|1@1+ (1,0) [0|1] ""  gtw
 SG_ DI_a170_pedalPos m170 : 40|8@1+ (0.4,0) [0|100] "%"  gtw
 SG_ DI_a149_state m149 : 40|3@1+ (1,0) [0|7] ""  gtw
 SG_ DI_a099_cpuUsage100Hz m99 : 40|8@1+ (1,0) [0|255] "%"  gtw
 SG_ DI_a123_badFlux m123 : 40|16@1+ (0.0001,0) [0|6.5535] "Wb"  gtw
 SG_ DI_a164_torqueDriver m164 : 40|14@1- (0.2,0) [-1638.4|1638.2] "Nm"  gtw
 SG_ DI_a038_iBat m38 : 40|12@1+ (0.5,0) [0|2047.5] "A"  gtw
 SG_ DI_a213_wheelSpeedCGReR m213 : 40|3@1+ (1,0) [0|7] ""  gtw
 SG_ DI_a162_pedalPos m162 : 40|8@1+ (0.4,0) [0|100] "%"  gtw
 SG_ DI_a159_crsUp m159 : 40|8@1- (4,0) [-512|508] "Nm"  gtw
 SG_ DI_a122_stackSize m122 : 40|16@1+ (1,0) [0|65535] ""  gtw
 SG_ DI_a232_WheelBrakeTorquesValid m232 : 40|1@1+ (1,0) [0|1] ""  gtw
 SG_ DI_a065_mailboxID m65 : 40|16@1+ (1,0) [0|65535] ""  gtw
 SG_ DI_a061_otherTemp m61 : 40|16@1- (0.1,0) [-3276.8|3276.7] "C"  gtw
 SG_ DI_a212_wheelSpeedCGFrR m212 : 40|3@1+ (1,0) [0|7] ""  gtw
 SG_ DI_a002_gateOn_L m2 : 40|1@1+ (1,0) [0|1] ""  gtw
 SG_ DI_a223_vehicleVelocity m223 : 40|6@1+ (1,0) [0|62] "m/s"  gtw
 SG_ DI_a001_gateOn_L m1 : 40|1@1+ (1,0) [0|1] ""  gtw
 SG_ DI_a134_wheelSpeedDiffReL m134 : 40|12@1- (0.0625,0) [-256|255] "kph"  gtw
 SG_ DI_a198_steeringAngle m198 : 40|3@1+ (1,0) [0|7] ""  gtw
 SG_ DI_a016_torqueMotor m16 : 40|16@1- (1,0) [-750|750] "Nm"  gtw
 SG_ DI_a204_rollRate m204 : 40|3@1+ (1,0) [0|7] ""  gtw
 SG_ DI_a195_wheelSlipFrR m195 : 40|3@1+ (1,0) [0|7] ""  gtw
 SG_ DI_a196_wheelSlipReR m196 : 40|3@1+ (1,0) [0|7] ""  gtw
 SG_ DI_a214_wheelSpeedNonCGFrR m214 : 40|3@1+ (1,0) [0|7] ""  gtw
 SG_ DI_a208_driverTorqueRe m208 : 40|3@1+ (1,0) [0|7] ""  gtw
 SG_ DI_a152_expectedValue m152 : 40|8@1+ (1,0) [0|255] ""  gtw
 SG_ DI_a184_apcIntState m184 : 40|8@1+ (1,0) [0|255] ""  gtw
 SG_ DI_a191_timeSinceCruiseCancel m191 : 40|7@1+ (0.5,0) [0|60] "second"  gtw
 SG_ DI_a096_word2 m96 : 40|16@1+ (1,0) [0|65535] ""  gtw
 SG_ DI_a160_elapsedMs m160 : 40|8@1+ (1,0) [0|255] "ms"  gtw
 SG_ DI_a205_pitchRate m205 : 40|3@1+ (1,0) [0|7] ""  gtw
 SG_ DI_a150_elapsedMs m150 : 40|8@1+ (1,0) [0|255] "ms"  gtw
 SG_ DI_a232_BrakeMasterCylPressValid m232 : 39|1@1+ (1,0) [0|1] ""  gtw
 SG_ DI_a218_lateralAccelFilt m218 : 39|6@1- (0.5,0.0) [-12|12] "m/s^2"  gtw
 SG_ DI_a003_overvoltVH_L m3 : 39|1@1+ (1,0) [0|1] ""  gtw
 SG_ DI_a001_overvoltVH_L m1 : 39|1@1+ (1,0) [0|1] ""  gtw
 SG_ DI_a002_overvoltVH_L m2 : 39|1@1+ (1,0) [0|1] ""  gtw
 SG_ DI_a153_state m153 : 39|3@1+ (1,0) [0|7] ""  gtw
 SG_ DI_a199_driverIntendedYawRate m199 : 38|7@1- (0.024,0.0) [-1.5|1.5] "rad/s"  gtw
 SG_ DI_a001_overvoltVL_L m1 : 38|1@1+ (1,0) [0|1] ""  gtw
 SG_ DI_a002_overvoltVL_L m2 : 38|1@1+ (1,0) [0|1] ""  gtw
 SG_ DI_a024_Ib m24 : 38|7@1- (22.5,0.0) [-1400|1400] "A"  gtw
 SG_ DI_a003_overvoltVL_L m3 : 38|1@1+ (1,0) [0|1] ""  gtw
 SG_ DI_a232_allWhlSpeedRotationAvail m232 : 38|1@1+ (1,0) [0|1] ""  gtw
 SG_ DI_a001_desat_L m1 : 37|1@1+ (1,0) [0|1] ""  gtw
 SG_ DI_a156_alertQueueOverrun m156 : 37|1@1+ (1,0) [0|1] ""  gtw
 SG_ DI_a220_lateralAccelFilt m220 : 37|6@1- (0.5,0.0) [-12|12] "m/s^2"  gtw
 SG_ DI_a221_lateralAccelFilt m221 : 37|6@1- (0.5,0.0) [-12|12] "m/s^2"  gtw
 SG_ DI_a003_desat_L m3 : 37|1@1+ (1,0) [0|1] ""  gtw
 SG_ DI_a002_desat_L m2 : 37|1@1+ (1,0) [0|1] ""  gtw
 SG_ DI_a219_lateralAccelFilt m219 : 37|6@1- (0.5,0.0) [-12|12] "m/s^2"  gtw
 SG_ DI_a002_sense_L m2 : 36|1@1+ (1,0) [0|1] ""  gtw
 SG_ DI_a003_sense_L m3 : 36|1@1+ (1,0) [0|1] ""  gtw
 SG_ DI_a148_accumulatedWear m148 : 36|10@1+ (0.005,0) [0|5.115] "1"  gtw
 SG_ DI_a191_requestedGear m191 : 36|3@1+ (1,0) [0|7] ""  gtw
 SG_ DI_a042_heatsinkTemp m42 : 36|10@1+ (0.25,-60) [-60|195] "DegC"  gtw
 SG_ DI_a045_heatsinkTemp m45 : 36|10@1+ (0.25,-60) [-60|195] "DegC"  gtw
 SG_ DI_a001_sense_L m1 : 36|1@1+ (1,0) [0|1] ""  gtw
 SG_ DI_a224_brakeRLTemp m224 : 36|10@1- (1,300) [-100|700] "degC"  gtw
 SG_ DI_a058_heatsinkTemp m58 : 36|10@1+ (0.25,-60) [-60|195] "DegC"  gtw
 SG_ DI_a003_undervoltVH_L m3 : 35|1@1+ (1,0) [0|1] ""  gtw
 SG_ DI_a223_UI_tractionControlMode m223 : 35|3@1+ (1,0) [0|5] ""  gtw
 SG_ DI_a002_undervoltVH_L m2 : 35|1@1+ (1,0) [0|1] ""  gtw
 SG_ DI_a156_safeStateRecommend m156 : 35|2@1+ (1,0) [0|3] ""  gtw
 SG_ DI_a001_undervoltVH_L m1 : 35|1@1+ (1,0) [0|1] ""  gtw
 SG_ DI_a232_musurfHigh m232 : 35|3@1+ (0.15,0.15) [0.15|1.2] "-"  gtw
 SG_ DI_a135_vhldTotalBrakeTorque m135 : 35|10@1+ (10,0) [0|10230] "Nm"  gtw
 SG_ DI_a041_espBrakeTorqueTarget m41 : 34|10@1+ (10,0) [0|10230] "Nm"  gtw
 SG_ DI_a002_undervoltVL_L m2 : 34|1@1+ (1,0) [0|1] ""  gtw
 SG_ DI_a001_undervoltVL_L m1 : 34|1@1+ (1,0) [0|1] ""  gtw
 SG_ DI_a147_accumulatedWear m147 : 34|10@1+ (0.005,0) [0|5.115] "1"  gtw
 SG_ DI_a003_undervoltVL_L m3 : 34|1@1+ (1,0) [0|1] ""  gtw
 SG_ DI_a162_reverseDeniedAfterCruise m162 : 33|1@1+ (1,0) [0|1] ""  gtw
 SG_ DI_a191_currentGear m191 : 33|3@1+ (1,0) [0|7] ""  gtw
 SG_ DI_a156_result m156 : 33|2@1+ (1,0) [0|2] ""  gtw
 SG_ DI_a003_thermalShutdown_L m3 : 33|1@1+ (1,0) [0|1] ""  gtw
 SG_ DI_a002_thermalShutdown_L m2 : 33|1@1+ (1,0) [0|1] ""  gtw
 SG_ DI_a001_thermalShutdown_L m1 : 33|1@1+ (1,0) [0|1] ""  gtw
 SG_ DI_a199_lateralAccelFilt m199 : 32|6@1- (0.5,0.0) [-12|12] "m/s^2"  gtw
 SG_ DI_a030_iCrmsTorque m30 : 32|16@1+ (0.25,0) [0|16383.75] "Nm"  gtw
 SG_ DI_a011_badDataRead m11 : 32|8@1+ (1,0) [0|255] ""  gtw
 SG_ DI_a173_pedalPos m173 : 32|8@1+ (0.4,0) [0|100] "%"  gtw
 SG_ DI_a189_systemTorque m189 : 32|8@1- (10,0) [-1280|1270] "Nm"  gtw
 SG_ DI_a082_track2Voltage m82 : 32|16@1+ (0.001,0) [0|65.535] "V"  gtw
 SG_ DI_a152_badValue m152 : 32|8@1+ (1,0) [0|255] ""  gtw
 SG_ DI_a054_heatsinkTemp m54 : 32|16@1- (0.1,0) [-3276.8|3276.7] "C"  gtw
 SG_ DI_a115_ph3Temp m115 : 32|8@1- (1,0) [-128|127] "C"  gtw
 SG_ DI_a014_torqueCommandFwd m14 : 32|10@1- (2,0) [-750|750] "Nm"  gtw
 SG_ DI_a184_crsNotAvailableReason m184 : 32|5@1+ (1,0) [0|20] ""  gtw
 SG_ DI_a154_phaseError m154 : 32|8@1- (0.004,0) [-0.512|0.508] "1"  gtw
 SG_ DI_a034_deltaIb m34 : 32|16@1- (1,0) [-32768|32767] "A"  gtw
 SG_ DI_a159_targetAccel m159 : 32|8@1+ (0.075,-10) [-10|9.125] "m/s^2"  gtw
 SG_ DI_a025_torqueMotor m25 : 32|13@1- (0.25,0.0) [-750|750] "Nm"  gtw
 SG_ DI_a162_essContClosed m162 : 32|1@1+ (1,0) [0|1] ""  gtw
 SG_ DI_a055_parameterPM m55 : 32|13@1- (0.25,0.0) [-750|750] "Nm"  gtw
 SG_ DI_a071_busVslope m71 : 32|16@1+ (0.1,0) [0|6553.5] "V/ms"  gtw
 SG_ DI_a074_motorSpeed1 m74 : 32|16@1- (1,0) [-17000|17000] "RPM"  gtw
 SG_ DI_a150_vBatFilteredRate m150 : 32|8@1- (100,0) [-12800|12700] "V/s"  gtw
 SG_ DI_a108_blockingAlert m108 : 32|8@1+ (1,0) [0|244] ""  gtw
 SG_ DI_a185_crsNotAvailableReason m185 : 32|5@1+ (1,0) [0|20] ""  gtw
 SG_ DI_a001_thermalWarning_L m1 : 32|1@1+ (1,0) [0|1] ""  gtw
 SG_ DI_a151_torqueDriver m151 : 32|16@1- (0.25,0) [-750|750] "Nm"  gtw
 SG_ DI_a153_temperature m153 : 32|7@1+ (2,-40) [-40|205] "DegC"  gtw
 SG_ DI_a065_errorType m65 : 32|1@1+ (1,0) [0|1] ""  gtw
 SG_ DI_a046_statorTemp2 m46 : 32|16@1- (0.1,0) [-3276.8|3276.7] "DegC"  gtw
 SG_ DI_a002_thermalWarning_L m2 : 32|1@1+ (1,0) [0|1] ""  gtw
 SG_ DI_a000_alertDataW1 m0 : 32|16@1+ (1,0) [0|65535] ""  X
 SG_ DI_a099_cpuUsage10Hz m99 : 32|8@1+ (1,0) [0|255] "%"  gtw
 SG_ DI_a035_phaseCurrent m35 : 32|16@1+ (1,0) [0|65535] "A"  gtw
 SG_ DI_a095_canID m95 : 32|16@1+ (1,0) [0|65535] ""  gtw
 SG_ DI_a075_absSpeed m75 : 32|16@1+ (1,0) [0|65535] "RPM"  gtw
 SG_ DI_a113_ph2Temp m113 : 32|16@1- (0.1,0) [-3276.8|3276.7] "C"  gtw
 SG_ DI_a160_vBatFilteredRate m160 : 32|8@1- (100,0) [-12800|12700] "V/s"  gtw
 SG_ DI_a223_DI_tractionControlMode m223 : 32|3@1+ (1,0) [0|5] ""  gtw
 SG_ DI_a124_cruiseFaultReason m124 : 32|5@1+ (1,0) [0|21] ""  gtw
 SG_ DI_a039_dragTorqueControlOff m39 : 32|1@1+ (1,0) [0|1] ""  gtw
 SG_ DI_a036_busHighLimit m36 : 32|16@1+ (0.1,0) [0|6553.5] "V"  gtw
 SG_ DI_a116_mechPower m116 : 32|16@1- (0.5,0) [-16384|16383.5] "KW"  gtw
 SG_ DI_a080_track2Voltage m80 : 32|16@1+ (0.001,0) [0|65.535] "V"  gtw
 SG_ DI_a026_torqueMotor m26 : 32|13@1- (0.25,0.0) [-750|750] "Nm"  gtw
 SG_ DI_a156_ucrPlausible m156 : 32|1@1+ (1,0) [0|1] ""  gtw
 SG_ DI_a029_iBrmsTorque m29 : 32|16@1+ (0.25,0) [0|16383.75] "Nm"  gtw
 SG_ DI_a012_accel2SupplyV m12 : 32|16@1+ (0.001,0) [0|65.535] "V"  gtw
 SG_ DI_a051_packCurrent m51 : 32|16@1- (0.1,0) [-3276.8|3276.7] "A"  gtw
 SG_ DI_a047_statorTslope1 m47 : 32|16@1- (0.1,0) [-3276.8|3276.7] "DegC/s"  gtw
 SG_ DI_a121_badCurrent m121 : 32|16@1- (0.1,0) [-3276.8|3276.7] "A"  gtw
 SG_ DI_a172_pedalPos m172 : 32|8@1+ (0.4,0) [0|100] "%"  gtw
 SG_ DI_a142_lashCheckCount m142 : 32|15@1+ (1,0) [0|32767] ""  gtw
 SG_ DI_a133_badValue1 m133 : 32|16@1- (0.1,0) [-3276.8|3276.7] "C"  gtw
 SG_ DI_a218_bankAngle m218 : 32|7@1- (0.008,0.0) [-0.5|0.5] "rad"  gtw
 SG_ DI_a098_fluxState m98 : 32|4@1+ (1,0) [0|9] ""  gtw
 SG_ DI_a003_thermalWarning_L m3 : 32|1@1+ (1,0) [0|1] ""  gtw
 SG_ DI_a125_maxChargeCurrent m125 : 32|16@1- (0.1,0) [-3276.8|3276.7] "A"  gtw
 SG_ DI_a191_reverseDeniedAfterCruise m191 : 32|1@1+ (1,0) [0|1] ""  gtw
 SG_ DI_a232_musurf m232 : 32|3@1+ (0.15,0.15) [0.15|1.2] "-"  gtw
 SG_ DI_a037_busLowLimit m37 : 32|16@1+ (0.1,0) [0|6553.5] "V"  gtw
 SG_ DI_a066_badValue2 m66 : 32|16@1+ (1,0) [0|65535] ""  gtw
 SG_ DI_a170_rawPedal m170 : 32|8@1+ (0.4,0) [0|100] "%"  gtw
 SG_ DI_a028_iArmsTorque m28 : 32|16@1+ (0.25,0) [0|16383.75] "Nm"  gtw
 SG_ DI_a081_track2Voltage m81 : 32|16@1+ (0.001,0) [0|65.535] "V"  gtw
 SG_ DI_a187_rawPedal m187 : 32|8@1+ (0.4,0) [0|100] "%"  gtw
 SG_ DI_a112_phaseBcurrent m112 : 32|16@1+ (1,0) [0|65535] "A"  gtw
 SG_ DI_a027_torqueMotor m27 : 32|13@1- (0.25,0.0) [-750|750] "Nm"  gtw
 SG_ DI_a131_warnSpeedLimit m131 : 32|16@1+ (1,0) [0|65535] "RPM"  gtw
 SG_ DI_a164_pedalPos m164 : 32|8@1+ (0.4,0) [0|100] "%"  gtw
 SG_ DI_a093_canID m93 : 32|16@1+ (1,0) [0|65535] ""  gtw
 SG_ DI_a114_absSpeed m114 : 32|16@1+ (1,0) [0|65535] "RPM"  gtw
 SG_ DI_a103_inletHeatsinkTemp m103 : 32|16@1- (0.1,67.5) [-60|195] "C"  gtw
 SG_ DI_a149_temperature m149 : 32|8@1+ (1,-40) [-40|205] "DegC"  gtw
 SG_ DI_a033_deltaIa m33 : 32|16@1- (1,0) [-32768|32767] "A"  gtw
 SG_ DI_a067_mailboxID m67 : 32|16@1+ (1,0) [0|65535] ""  gtw
 SG_ DI_a094_badValue1 m94 : 32|16@1+ (1,0) [0|65535] ""  gtw
 SG_ DI_a001_deadtimeError_H m1 : 31|1@1+ (1,0) [0|1] ""  gtw
 SG_ DI_a024_Ia m24 : 31|7@1- (22.5,0.0) [-1400|1400] "A"  gtw
 SG_ DI_a156_highMotorSpeed m156 : 31|1@1+ (1,0) [0|1] ""  gtw
 SG_ DI_a003_deadtimeError_H m3 : 31|1@1+ (1,0) [0|1] ""  gtw
 SG_ DI_a002_deadtimeError_H m2 : 31|1@1+ (1,0) [0|1] ""  gtw
 SG_ DI_a103_fluidImplausible m103 : 30|1@1+ (1,0) [0|1] ""  gtw
 SG_ DI_a002_spiError_H m2 : 30|1@1+ (1,0) [0|1] ""  gtw
 SG_ DI_a220_bankAngle m220 : 30|7@1- (0.008,0.0) [-0.5|0.5] "rad"  gtw
 SG_ DI_a001_spiError_H m1 : 30|1@1+ (1,0) [0|1] ""  gtw
 SG_ DI_a156_highCurrentMagnitude m156 : 30|1@1+ (1,0) [0|1] ""  gtw
 SG_ DI_a221_bankAngle m221 : 30|7@1- (0.008,0.0) [-0.5|0.5] "rad"  gtw
 SG_ DI_a219_bankAngle m219 : 30|7@1- (0.008,0.0) [-0.5|0.5] "rad"  gtw
 SG_ DI_a014_adState m14 : 30|2@1+ (1,0) [0|3] ""  gtw
 SG_ DI_a003_spiError_H m3 : 30|1@1+ (1,0) [0|1] ""  gtw
 SG_ DI_a214_wheelSpeedNonCGFrLCurrVa m214 : 29|10@1- (0.11,35.09) [-20|90] "m/s"  gtw
 SG_ DI_a103_lowFlowDetected m103 : 29|1@1+ (1,0) [0|1] ""  gtw
 SG_ DI_a207_motorTorqueFrCurrVal m207 : 29|10@1- (14.649,0.0) [-7500|7500] "Nm"  gtw
 SG_ DI_a198_MCPressCurrValue m198 : 29|10@1- (0.3,123.6) [-30|276.6] "bar"  gtw
 SG_ DI_a193_brakeTorqueFrLCurrVal m193 : 29|10@1+ (8,0) [0|8189] "Nm"  gtw
 SG_ DI_a011_badGateDriveIC m11 : 29|3@1+ (1,0) [0|7] ""  gtw
 SG_ DI_a001_localRegError_H m1 : 29|1@1+ (1,0) [0|1] ""  gtw
 SG_ DI_a208_motorTorqueReCurrVal m208 : 29|10@1- (14.649,0.0) [-7500|7500] "Nm"  gtw
 SG_ DI_a223_slaveADDState m223 : 29|2@1+ (1,0) [0|3] ""  gtw
 SG_ DI_a196_wheelSlipReLCurrValue m196 : 29|10@1+ (0.001,0) [0|1] "1"  gtw
 SG_ DI_a195_wheelSlipFrLCurrValue m195 : 29|10@1+ (0.001,0) [0|1] "1"  gtw
 SG_ DI_a194_brakeTorqueReLCurrVal m194 : 29|10@1+ (8,0) [0|8190] "Nm"  gtw
 SG_ DI_a215_wheelSpeedNonCGReLCurrVa m215 : 29|10@1- (0.11,35.09) [-20|90] "m/s"  gtw
 SG_ DI_a211_motorSpeedFrCurrVal m211 : 29|10@1- (0.11,35.09) [-20|90] "m/s"  gtw
 SG_ DI_a212_wheelSpeedCGFrLCurrVal m212 : 29|10@1- (0.11,35.09) [-20|90] "m/s"  gtw
 SG_ DI_a003_localRegError_H m3 : 29|1@1+ (1,0) [0|1] ""  gtw
 SG_ DI_a204_longAccelCurrVal m204 : 29|10@1- (0.08,0.0) [-40.9575|40.9575] "m/s^2"  gtw
 SG_ DI_a209_vehicleSpeedCurrVal m209 : 29|10@1- (0.11,35.09) [-20|90] "m/s"  gtw
 SG_ DI_a213_wheelSpeedCGReLCurrVal m213 : 29|10@1- (0.11,35.09) [-20|90] "m/s"  gtw
 SG_ DI_a205_latAccelCurrVal m205 : 29|10@1- (0.08,0.0) [-40.9575|40.9575] "m/s^2"  gtw
 SG_ DI_a206_verticalAccelCurrVal m206 : 29|10@1- (0.08,0.0) [-40.9575|40.9575] "m/s^2"  gtw
 SG_ DI_a002_localRegError_H m2 : 29|1@1+ (1,0) [0|1] ""  gtw
 SG_ DI_a094_errorType m94 : 28|3@1+ (1,0) [0|6] ""  gtw
 SG_ DI_a003_overvoltVDD_H m3 : 28|1@1+ (1,0) [0|1] ""  gtw
 SG_ DI_a038_vBat m38 : 28|12@1+ (0.2,0) [0|819] "V"  gtw
 SG_ DI_a002_overvoltVDD_H m2 : 28|1@1+ (1,0) [0|1] ""  gtw
 SG_ DI_a156_powerPolarity m156 : 28|2@1+ (1,0) [0|3] ""  gtw
 SG_ DI_a134_wheelSpeedDiffFrR m134 : 28|12@1- (0.0625,0) [-256|255] "kph"  gtw
 SG_ DI_a103_noFlowDetected m103 : 28|1@1+ (1,0) [0|1] ""  gtw
 SG_ DI_a001_overvoltVDD_H m1 : 28|1@1+ (1,0) [0|1] ""  gtw
 SG_ DI_a189_brakePressed m189 : 28|1@1+ (1,0) [0|1] ""  gtw
 SG_ DI_a197_wheelSaturationReR m197 : 27|3@1+ (1,0) [0|7] ""  gtw
 SG_ DI_a002_undervoltVDD_H m2 : 27|1@1+ (1,0) [0|1] ""  gtw
 SG_ DI_a024_state m24 : 27|4@1+ (1,0) [0|11] ""  gtw
 SG_ DI_a003_undervoltVDD_H m3 : 27|1@1+ (1,0) [0|1] ""  gtw
 SG_ DI_a223_addState m223 : 27|2@1+ (1,0) [0|3] ""  gtw
 SG_ DI_a001_undervoltVDD_H m1 : 27|1@1+ (1,0) [0|1] ""  gtw
 SG_ DI_a148_overtorque2UsedCount m148 : 26|10@1+ (1,0) [0|1023] ""  gtw
 SG_ DI_a001_remoteRegError_H m1 : 26|1@1+ (1,0) [0|1] ""  gtw
 SG_ DI_a156_phaseCPolarity m156 : 26|2@1+ (1,0) [0|3] ""  gtw
 SG_ DI_a130_aebBrakeTorqueCommand m130 : 26|13@1+ (2,0) [0|16382] "Nm"  gtw
 SG_ DI_a042_outletTemp m42 : 26|10@1+ (0.25,-60) [-60|195] "DegC"  gtw
 SG_ DI_a003_remoteRegError_H m3 : 26|1@1+ (1,0) [0|1] ""  gtw
 SG_ DI_a058_outletTemp m58 : 26|10@1+ (0.25,-60) [-60|195] "DegC"  gtw
 SG_ DI_a002_remoteRegError_H m2 : 26|1@1+ (1,0) [0|1] ""  gtw
 SG_ DI_a074_speed2Type m74 : 26|2@1+ (1,0) [0|3] ""  gtw
 SG_ DI_a045_outletTemp m45 : 26|10@1+ (0.25,-60) [-60|195] "DegC"  gtw
 SG_ DI_a199_bankAngle m199 : 26|6@1- (0.016,0.0) [-0.5|0.5] "rad"  gtw
 SG_ DI_a224_brakeFRTemp m224 : 26|10@1- (1,300) [-100|700] "degC"  gtw
 SG_ DI_a035_phaseDifference m35 : 25|7@1+ (1,0) [0|127] "%"  gtw
 SG_ DI_a003_asynchStop_H m3 : 25|1@1+ (1,0) [0|1] ""  gtw
 SG_ DI_a135_vhldBrakeTorqueCommand m135 : 25|10@1+ (10,0) [0|10230] "Nm"  gtw
 SG_ DI_a002_asynchStop_H m2 : 25|1@1+ (1,0) [0|1] ""  gtw
 SG_ DI_a001_asynchStop_H m1 : 25|1@1+ (1,0) [0|1] ""  gtw
 SG_ DI_a074_speed1Type m74 : 24|2@1+ (1,0) [0|3] ""  gtw
 SG_ DI_a153_voltage m153 : 24|8@1+ (0.1,0) [0|25.5] "V"  gtw
 SG_ DI_a108_toState m108 : 24|8@1+ (1,0) [0|255] ""  gtw
 SG_ DI_a223_velocityEstimatorState m223 : 24|3@1+ (1,0) [0|4] ""  gtw
 SG_ DI_a003_gateOn_H m3 : 24|1@1+ (1,0) [0|1] ""  gtw
 SG_ DI_a035_noDriveCurrent m35 : 24|1@1+ (1,0) [0|1] ""  gtw
 SG_ DI_a079_adcRefHighAvg m79 : 24|16@1+ (1,0) [0|65535] ""  gtw
 SG_ DI_a219_muVehicleDecFilt m219 : 24|6@1+ (0.025,0) [0|1.5] "-"  gtw
 SG_ DI_a078_adcRefLowAvg m78 : 24|16@1+ (1,0) [0|65535] ""  gtw
 SG_ DI_a232_vehicleVelocity m232 : 24|6@1+ (1,0) [0|62] "m/s"  gtw
 SG_ DI_a221_muVehicleDecFilt m221 : 24|6@1+ (0.025,0) [0|1.3] "-"  gtw
 SG_ DI_a184_apcUnavailableReason m184 : 24|4@1+ (1,0) [0|11] ""  gtw
 SG_ DI_a136_badValue1 m136 : 24|16@1+ (1,0) [0|65535] ""  gtw
 SG_ DI_a130_dasAebEvent m130 : 24|2@1+ (1,0) [0|3] ""  gtw
 SG_ DI_a123_badCurrent m123 : 24|16@1- (0.1,0) [-3276.8|3276.7] "A"  gtw
 SG_ DI_a002_gateOn_H m2 : 24|1@1+ (1,0) [0|1] ""  gtw
 SG_ DI_a097_lineNumber m97 : 24|16@1+ (1,0) [0|65535] ""  gtw
 SG_ DI_a159_targetSpeed m159 : 24|8@1+ (0.5,0) [0|127.5] "MPH"  gtw
 SG_ DI_a016_motorRPM m16 : 24|16@1- (1,0) [-20000|20000] "RPM"  gtw
 SG_ DI_a122_stackUsed m122 : 24|16@1+ (1,0) [0|65535] ""  gtw
 SG_ DI_a099_cpuUsage1Hz m99 : 24|8@1+ (1,0) [0|255] "%"  gtw
 SG_ DI_a096_word1 m96 : 24|16@1+ (1,0) [0|65535] ""  gtw
 SG_ DI_a001_gateOn_H m1 : 24|1@1+ (1,0) [0|1] ""  gtw
 SG_ DI_a127_temp m127 : 24|16@1- (0.1,0) [-3276.8|3276.7] "C"  gtw
 SG_ DI_a220_muVehicleDecFilt m220 : 24|6@1+ (0.025,0) [0|1.3] "-"  gtw
 SG_ DI_a189_grade m189 : 24|4@1- (4,0) [-32|28] "%"  gtw
 SG_ DI_a147_overtorque2UsedCount m147 : 24|10@1+ (1,0) [0|1023] ""  gtw
 SG_ DI_a135_vhldBrakeApply m135 : 24|1@1+ (1,0) [0|1] ""  gtw
 SG_ DI_a241_rotorMaxMagnetTemp m241 : 24|8@1- (1,88) [-40|215] "degC"  gtw
 SG_ DI_a011_regAddress m11 : 24|5@1+ (1,0) [0|31] ""  gtw
 SG_ DI_a152_frameId m152 : 24|8@1+ (1,0) [0|255] ""  gtw
 SG_ DI_a149_voltage m149 : 24|8@1+ (0.1,0) [0|25.5] "V"  gtw
 SG_ DI_a218_muVehicleDecFilt m218 : 24|6@1+ (0.025,0) [0|1.3] "-"  gtw
 SG_ DI_a061_phTemp m61 : 24|16@1- (0.1,0) [-3276.8|3276.7] "C"  gtw
 SG_ DI_a197_wheelSaturationReL m197 : 24|3@1+ (1,0) [0|7] ""  gtw
 SG_ DI_a115_ph2Temp m115 : 24|8@1- (1,0) [-128|127] "C"  gtw
 SG_ DI_a156_phaseBPolarity m156 : 24|2@1+ (1,0) [0|3] ""  gtw
 SG_ DI_a185_apcUnavailableReason m185 : 24|4@1+ (1,0) [0|11] ""  gtw
 SG_ DI_a024_failReason m24 : 24|3@1+ (1,0) [0|7] ""  gtw
 SG_ DI_a041_diBrakeTorqueCommand m41 : 24|10@1+ (10,0) [0|10230] "Nm"  gtw
 SG_ DI_a001_overvoltVH_H m1 : 23|1@1+ (1,0) [0|1] ""  gtw
 SG_ DI_a016_alertQueueOverrun m16 : 23|1@1+ (1,0) [0|1] ""  gtw
 SG_ DI_a002_overvoltVH_H m2 : 23|1@1+ (1,0) [0|1] ""  gtw
 SG_ DI_a003_overvoltVH_H m3 : 23|1@1+ (1,0) [0|1] ""  gtw
 SG_ DI_a144_inverterHardware m144 : 23|1@1+ (1,0) [0|1] ""  gtw
 SG_ DI_a153_lowFluidLevel m153 : 23|1@1+ (1,0) [0|1] ""  gtw
 SG_ DI_a155_vcleftSwitchStatus m155 : 23|1@1+ (1,0) [0|1] ""  gtw
 SG_ DI_a011_phaseCLow m11 : 23|1@1+ (1,0) [0|1] ""  gtw
 SG_ DI_a216_MBPFaultProbability m216 : 22|10@1+ (0.008,0) [0|8] "-"  gtw
 SG_ DI_a011_phaseCHigh m11 : 22|1@1+ (1,0) [0|1] ""  gtw
 SG_ DI_a200_MBPFaultProbability m200 : 22|10@1+ (0.008,0) [0|8] "-"  gtw
 SG_ DI_a035_reportingPhase m35 : 22|2@1+ (1,0) [0|3] ""  gtw
 SG_ DI_a003_overvoltVL_H m3 : 22|1@1+ (1,0) [0|1] ""  gtw
 SG_ DI_a106_ESP_wheelSpeeds m106 : 22|1@1+ (1,0) [0|1] ""  gtw
 SG_ DI_a117_systemStatus m117 : 22|1@1+ (1,0) [0|1] ""  gtw
 SG_ DI_a016_uncontrolledRegenZone m16 : 22|1@1+ (1,0) [0|1] ""  gtw
 SG_ DI_a223_btcTargetState m223 : 22|2@1+ (1,0) [0|3] ""  gtw
 SG_ DI_a156_phaseAPolarity m156 : 22|2@1+ (1,0) [0|3] ""  gtw
 SG_ DI_a091_ESP_party3 m91 : 22|1@1+ (1,0) [0|1] ""  gtw
 SG_ DI_a144_BMS_subUsageId m144 : 22|1@1+ (1,0) [0|1] ""  gtw
 SG_ DI_a155_rightDoorStatus m155 : 22|1@1+ (1,0) [0|1] ""  gtw
 SG_ DI_a001_overvoltVL_H m1 : 22|1@1+ (1,0) [0|1] ""  gtw
 SG_ DI_a002_overvoltVL_H m2 : 22|1@1+ (1,0) [0|1] ""  gtw
 SG_ DI_a091_ESP_status m91 : 21|1@1+ (1,0) [0|1] ""  gtw
 SG_ DI_a016_ascMonitor m16 : 21|1@1+ (1,0) [0|1] ""  gtw
 SG_ DI_a011_phaseBLow m11 : 21|1@1+ (1,0) [0|1] ""  gtw
 SG_ DI_a210_espActuatorState m210 : 21|2@1+ (1,0) [0|3] ""  gtw
 SG_ DI_a144_brakeHWType m144 : 21|1@1+ (1,0) [0|1] ""  gtw
 SG_ DI_a092_bmsInfo m92 : 21|1@1+ (1,0) [0|1] ""  gtw
 SG_ DI_a003_desat_H m3 : 21|1@1+ (1,0) [0|1] ""  gtw
 SG_ DI_a117_chassisControl m117 : 21|1@1+ (1,0) [0|1] ""  gtw
 SG_ DI_a002_desat_H m2 : 21|1@1+ (1,0) [0|1] ""  gtw
 SG_ DI_a199_muVehicleDecFilt m199 : 21|5@1+ (0.05,0) [0|1.5] "-"  gtw
 SG_ DI_a035_wontMoveCurrent m35 : 21|1@1+ (1,0) [0|1] ""  gtw
 SG_ DI_a001_desat_H m1 : 21|1@1+ (1,0) [0|1] ""  gtw
 SG_ DI_a106_WHL_STAT2 m106 : 21|1@1+ (1,0) [0|1] ""  gtw
 SG_ DI_a155_leftDoorStatus m155 : 21|1@1+ (1,0) [0|1] ""  gtw
 SG_ DI_a155_status m155 : 20|1@1+ (1,0) [0|1] ""  gtw
 SG_ DI_a003_sense_H m3 : 20|1@1+ (1,0) [0|1] ""  gtw
 SG_ DI_a223_ptcTargetState m223 : 20|2@1+ (1,0) [0|3] ""  gtw
 SG_ DI_a064_torqueCmdState m64 : 20|4@1+ (1,0) [0|8] ""  gtw
 SG_ DI_a001_sense_H m1 : 20|1@1+ (1,0) [0|1] ""  gtw
 SG_ DI_a117_speed m117 : 20|1@1+ (1,0) [0|1] ""  gtw
 SG_ DI_a226_hvStateNotUpForDrive m226 : 20|1@1+ (1,0) [0|1] ""  gtw
 SG_ DI_a130_aebSmState m130 : 20|3@1+ (1,0) [0|7] ""  gtw
 SG_ DI_a106_ECB1S04 m106 : 20|1@1+ (1,0) [0|1] ""  gtw
 SG_ DI_a091_ESP_offsets m91 : 20|1@1+ (1,0) [0|1] ""  gtw
 SG_ DI_a092_bmsBmbMinMax m92 : 20|1@1+ (1,0) [0|1] ""  gtw
 SG_ DI_a099_thread1kHz m99 : 20|1@1+ (1,0) [0|1] ""  gtw
 SG_ DI_a096_mem_regs m96 : 20|1@1+ (1,0) [0|1] ""  gtw
 SG_ DI_a035_unbalancedCurrent m35 : 20|1@1+ (1,0) [0|1] ""  gtw
 SG_ DI_a040_capability2 m40 : 20|1@1+ (1,0) [0|1] ""  gtw
 SG_ DI_a002_sense_H m2 : 20|1@1+ (1,0) [0|1] ""  gtw
 SG_ DI_a011_phaseBHigh m11 : 20|1@1+ (1,0) [0|1] ""  gtw
 SG_ DI_a144_vdcType m144 : 20|1@1+ (1,0) [0|1] ""  gtw
 SG_ DI_a016_gateDriveFaultLine m16 : 20|1@1+ (1,0) [0|1] ""  gtw
 SG_ DI_a135_vhldSmState m135 : 20|4@1+ (1,0) [0|15] ""  gtw
 SG_ DI_a193_brakeTorqueFrLLastVal m193 : 19|10@1+ (8,0) [0|8189] "Nm"  gtw
 SG_ DI_a099_thread100Hz m99 : 19|1@1+ (1,0) [0|1] ""  gtw
 SG_ DI_a155_vehicleStatus m155 : 19|1@1+ (1,0) [0|1] ""  gtw
 SG_ DI_a121_torqueDelta m121 : 19|13@1- (0.25,0.0) [-750|750] "Nm"  gtw
 SG_ DI_a106_ECB1S03 m106 : 19|1@1+ (1,0) [0|1] ""  gtw
 SG_ DI_a213_wheelSpeedCGReLLastVal m213 : 19|10@1- (0.11,35.09) [-20|90] "m/s"  gtw
 SG_ DI_a002_undervoltVH_H m2 : 19|1@1+ (1,0) [0|1] ""  gtw
 SG_ DI_a208_motorTorqueReLastVal m208 : 19|10@1- (14.649,0.0) [-7500|7500] "Nm"  gtw
 SG_ DI_a088_uiVehicleModes m88 : 19|1@1+ (1,0) [0|1] ""  gtw
 SG_ DI_a091_ESP_motorLimits m91 : 19|1@1+ (1,0) [0|1] ""  gtw
 SG_ DI_a223_btcState m223 : 19|1@1+ (1,0) [0|1] ""  gtw
 SG_ DI_a214_wheelSpeedNonCGFrLLastVa m214 : 19|10@1- (0.11,35.09) [-20|90] "m/s"  gtw
 SG_ DI_a001_undervoltVH_H m1 : 19|1@1+ (1,0) [0|1] ""  gtw
 SG_ DI_a197_wheelSaturationFrR m197 : 19|3@1+ (1,0) [0|7] ""  gtw
 SG_ DI_a144_performancePackage m144 : 19|1@1+ (1,0) [0|1] ""  gtw
 SG_ DI_a207_motorTorqueFrLastVal m207 : 19|10@1- (14.649,0.0) [-7500|7500] "Nm"  gtw
 SG_ DI_a109_ECT1S92 m109 : 19|1@1+ (1,0) [0|1] ""  gtw
 SG_ DI_a035_standbyCurrent m35 : 19|1@1+ (1,0) [0|1] ""  gtw
 SG_ DI_a096_mem_data m96 : 19|1@1+ (1,0) [0|1] ""  gtw
 SG_ DI_a204_longAccelLastVal m204 : 19|10@1- (0.08,0.0) [-40.9575|40.9575] "m/s^2"  gtw
 SG_ DI_a209_vehicleSpeedLastVal m209 : 19|10@1- (0.11,35.09) [-20|90] "m/s"  gtw
 SG_ DI_a083_brakeSwitchIrrationalNC m83 : 19|1@1+ (1,0) [0|1] ""  gtw
 SG_ DI_a011_phaseALow m11 : 19|1@1+ (1,0) [0|1] ""  gtw
 SG_ DI_a198_MCPressureLastValue m198 : 19|10@1- (0.3,123.6) [-30|276.6] "bar"  gtw
 SG_ DI_a227_vehiclePowerState m227 : 19|2@1+ (1,0) [0|3] ""  gtw
 SG_ DI_a205_latAccelLastVal m205 : 19|10@1- (0.08,0.0) [-40.9575|40.9575] "m/s^2"  gtw
 SG_ DI_a117_slaveCommand2 m117 : 19|1@1+ (1,0) [0|1] ""  gtw
 SG_ DI_a206_verticalAccelLastVal m206 : 19|10@1- (0.08,0.0) [-40.9575|40.9575] "m/s^2"  gtw
 SG_ DI_a090_state2 m90 : 19|1@1+ (1,0) [0|1] ""  gtw
 SG_ DI_a232_UI_tractionControlMode m232 : 19|3@1+ (1,0) [0|5] ""  gtw
 SG_ DI_a092_bmsPowerAvailable m92 : 19|1@1+ (1,0) [0|1] ""  gtw
 SG_ DI_a196_wheelSlipReLLastValue m196 : 19|10@1+ (0.001,0) [0|1] "1"  gtw
 SG_ DI_a195_wheelSlipFrLLastValue m195 : 19|10@1+ (0.001,0) [0|1] "1"  gtw
 SG_ DI_a194_brakeTorqueReLLastVal m194 : 19|10@1+ (8,0) [0|8190] "Nm"  gtw
 SG_ DI_a215_wheelSpeedNonCGReLLastVa m215 : 19|10@1- (0.11,35.09) [-20|90] "m/s"  gtw
 SG_ DI_a225_hsDeltaImplausible m225 : 19|1@1+ (1,0) [0|1] ""  gtw
 SG_ DI_a211_motorSpeedFrLastVal m211 : 19|10@1- (0.11,35.09) [-20|90] "m/s"  gtw
 SG_ DI_a202_movement m202 : 19|9@1+ (0.005,0) [0|2.5] "m"  gtw
 SG_ DI_a210_tractionControlState m210 : 19|2@1+ (1,0) [0|3] ""  gtw
 SG_ DI_a003_undervoltVH_H m3 : 19|1@1+ (1,0) [0|1] ""  gtw
 SG_ DI_a040_status m40 : 19|1@1+ (1,0) [0|1] ""  gtw
 SG_ DI_a212_wheelSpeedCGFrLLastVal m212 : 19|10@1- (0.11,35.09) [-20|90] "m/s"  gtw
 SG_ DI_a096_text_flash m96 : 18|1@1+ (1,0) [0|1] ""  gtw
 SG_ DI_a144_packEnergy m144 : 18|1@1+ (1,0) [0|1] ""  gtw
 SG_ DI_a035_phaseCerror m35 : 18|1@1+ (1,0) [0|1] ""  gtw
 SG_ DI_a225_fluidImplausible m225 : 18|1@1+ (1,0) [0|1] ""  gtw
 SG_ DI_a003_undervoltVL_H m3 : 18|1@1+ (1,0) [0|1] ""  gtw
 SG_ DI_a221_muVehicleLearnDown m221 : 18|6@1+ (0.025,0) [0|1.3] "-"  gtw
 SG_ DI_a219_muVehicleLearnDown m219 : 18|6@1+ (0.025,0) [0|1.5] "-"  gtw
 SG_ DI_a090_crossCheck m90 : 18|1@1+ (1,0) [0|1] ""  gtw
 SG_ DI_a092_bmsHvBusStatus m92 : 18|1@1+ (1,0) [0|1] ""  gtw
 SG_ DI_a002_undervoltVL_H m2 : 18|1@1+ (1,0) [0|1] ""  gtw
 SG_ DI_a083_brakeSwitchIrrationalNO m83 : 18|1@1+ (1,0) [0|1] ""  gtw
 SG_ DI_a040_power m40 : 18|1@1+ (1,0) [0|1] ""  gtw
 SG_ DI_a061_reason m61 : 18|1@1+ (1,0) [0|1] ""  gtw
 SG_ DI_a155_LVPowerState m155 : 18|1@1+ (1,0) [0|1] ""  gtw
 SG_ DI_a244_flybackFault m244 : 18|1@1+ (1,0) [0|1] ""  gtw
 SG_ DI_a117_power m117 : 18|1@1+ (1,0) [0|1] ""  gtw
 SG_ DI_a011_phaseAHigh m11 : 18|1@1+ (1,0) [0|1] ""  gtw
 SG_ DI_a109_EHV1S54 m109 : 18|1@1+ (1,0) [0|1] ""  gtw
 SG_ DI_a099_thread10Hz m99 : 18|1@1+ (1,0) [0|1] ""  gtw
 SG_ DI_a106_ABS_E m106 : 18|1@1+ (1,0) [0|1] ""  gtw
 SG_ DI_a001_undervoltVL_H m1 : 18|1@1+ (1,0) [0|1] ""  gtw
 SG_ DI_a218_muVehicleLearnDown m218 : 18|6@1+ (0.025,0) [0|1.3] "-"  gtw
 SG_ DI_a088_uiPowertrainControl m88 : 18|1@1+ (1,0) [0|1] ""  gtw
 SG_ DI_a220_muVehicleLearnDown m220 : 18|6@1+ (0.025,0) [0|1.3] "-"  gtw
 SG_ DI_a091_ESP_wheelRotation m91 : 18|1@1+ (1,0) [0|1] ""  gtw
 SG_ DI_a016_oldSafeState m16 : 18|2@1+ (1,0) [0|3] ""  gtw
 SG_ DI_a087_gtwUpdateStatus m87 : 18|1@1+ (1,0) [0|1] ""  gtw
 SG_ DI_a156_observation m156 : 18|4@1+ (1,0) [0|10] ""  gtw
 SG_ DI_a099_thread1Hz m99 : 17|1@1+ (1,0) [0|1] ""  gtw
 SG_ DI_a001_thermalShutdown_H m1 : 17|1@1+ (1,0) [0|1] ""  gtw
 SG_ DI_a092_bmsDriveLimits m92 : 17|1@1+ (1,0) [0|1] ""  gtw
 SG_ DI_a157_RCM_inertial2 m157 : 17|1@1+ (1,0) [0|1] ""  gtw
 SG_ DI_a109_EHV1S53 m109 : 17|1@1+ (1,0) [0|1] ""  gtw
 SG_ DI_a040_capability m40 : 17|1@1+ (1,0) [0|1] ""  gtw
 SG_ DI_a185_apcCancelReason m185 : 17|5@1+ (1,0) [0|22] ""  gtw
 SG_ DI_a225_hs2Implausible m225 : 17|1@1+ (1,0) [0|1] ""  gtw
 SG_ DI_a090_state m90 : 17|1@1+ (1,0) [0|1] ""  gtw
 SG_ DI_a087_gtwTime m87 : 17|1@1+ (1,0) [0|1] ""  gtw
 SG_ DI_a091_ESP_wheelSpeeds m91 : 17|1@1+ (1,0) [0|1] ""  gtw
 SG_ DI_a143_systemTorqueLimit m143 : 17|1@1+ (1,0) [0|1] ""  gtw
 SG_ DI_a035_phaseBerror m35 : 17|1@1+ (1,0) [0|1] ""  gtw
 SG_ DI_a083_brakeSwitchNC m83 : 17|1@1+ (1,0) [0|1] ""  gtw
 SG_ DI_a158_IBST_status m158 : 17|1@1+ (1,0) [0|1] ""  gtw
 SG_ DI_a155_coolant m155 : 17|1@1+ (1,0) [0|1] ""  gtw
 SG_ DI_a096_text_fast m96 : 17|1@1+ (1,0) [0|1] ""  gtw
 SG_ DI_a117_slaveCommand m117 : 17|1@1+ (1,0) [0|1] ""  gtw
 SG_ DI_a216_MBPFailedCase m216 : 17|5@1+ (1,0) [0|30] ""  gtw
 SG_ DI_a144_drivetrainType m144 : 17|1@1+ (1,0) [0|1] ""  gtw
 SG_ DI_a200_MBPFailedCase m200 : 17|5@1+ (1,0) [0|30] ""  gtw
 SG_ DI_a003_thermalShutdown_H m3 : 17|1@1+ (1,0) [0|1] ""  gtw
 SG_ DI_a161_EPAS3P_angleCalib m161 : 17|1@1+ (1,0) [0|1] ""  gtw
 SG_ DI_a110_EPBR_status m110 : 17|1@1+ (1,0) [0|1] ""  gtw
 SG_ DI_a002_thermalShutdown_H m2 : 17|1@1+ (1,0) [0|1] ""  gtw
 SG_ DI_a228_faulted m228 : 17|1@1+ (1,0) [0|1] ""  gtw
 SG_ DI_a141_DAS_status2 m141 : 17|1@1+ (1,0) [0|1] ""  gtw
 SG_ DI_a106_ABS_C m106 : 17|1@1+ (1,0) [0|1] ""  gtw
 SG_ DI_a244_singleSwitchShort m244 : 17|1@1+ (1,0) [0|1] ""  gtw
 SG_ DI_a088_uiCruiseControl m88 : 17|1@1+ (1,0) [0|1] ""  gtw
 SG_ DI_a003_thermalWarning_H m3 : 16|1@1+ (1,0) [0|1] ""  gtw
 SG_ DI_a095_mailboxID m95 : 16|16@1+ (1,0) [0|65535] ""  gtw
 SG_ DI_a224_brakeFLTemp m224 : 16|10@1- (1,300) [-100|700] "degC"  gtw
 SG_ DI_a079_adcRefChan m79 : 16|4@1+ (1,0) [0|15] ""  gtw
 SG_ DI_a231_PTC_feedbackStatus m231 : 16|1@1+ (1,0) [0|1] ""  gtw
 SG_ DI_a090_reason m90 : 16|1@1+ (1,0) [0|1] ""  gtw
 SG_ DI_a210_velocityEstimateState m210 : 16|3@1+ (1,0) [0|4] ""  gtw
 SG_ DI_a066_badValue1 m66 : 16|16@1+ (1,0) [0|65535] ""  gtw
 SG_ DI_a184_apcCancelReason m184 : 16|5@1+ (1,0) [0|22] ""  gtw
 SG_ DI_a133_capacitorTemp m133 : 16|16@1- (0.1,0) [-3276.8|3276.7] "C"  gtw
 SG_ DI_a065_canID m65 : 16|16@1+ (1,0) [0|65535] ""  gtw
 SG_ DI_a165_crsCancelReason m165 : 16|3@1+ (1,0) [0|7] ""  gtw
 SG_ DI_a221_vdcActivationAlertType m221 : 16|2@1+ (1,0) [0|2] ""  gtw
 SG_ DI_a039_maxRegenPower m39 : 16|16@1- (0.5,0) [-16384|16383.5] "KW"  gtw
 SG_ DI_a130_aebFaultReason m130 : 16|4@1+ (1,0) [0|15] ""  gtw
 SG_ DI_a211_motorSpeedFr m211 : 16|3@1+ (1,0) [0|7] ""  gtw
 SG_ DI_a037_busVoltage m37 : 16|16@1+ (0.1,0) [0|6553.5] "V"  gtw
 SG_ DI_a215_wheelSpeedNonCGReL m215 : 16|3@1+ (1,0) [0|7] ""  gtw
 SG_ DI_a146_panicReason m146 : 16|3@1+ (1,0) [0|6] ""  gtw
 SG_ DI_a185_summonActive m185 : 16|1@1+ (1,0) [0|1] ""  gtw
 SG_ DI_a241_statorEndWindingTemp m241 : 16|8@1- (1,88) [-40|215] "degC"  gtw
 SG_ DI_a050_statorTemp1 m50 : 16|16@1- (0.1,0) [-3276.8|3276.7] "DegC"  gtw
 SG_ DI_a033_phaseAcurrent m33 : 16|16@1- (1,0) [-32768|32767] "A"  gtw
 SG_ DI_a076_12vSupply m76 : 16|16@1+ (0.001,0) [0|65.535] "V"  gtw
 SG_ DI_a059_heatsinkTemp m59 : 16|16@1- (0.1,0) [-3276.8|3276.7] "C"  gtw
 SG_ DI_a045_inletTemp m45 : 16|10@1+ (0.25,-60) [-60|195] "DegC"  gtw
 SG_ DI_a117_torque m117 : 16|1@1+ (1,0) [0|1] ""  gtw
 SG_ DI_a064_interventionType m64 : 16|4@1+ (1,0) [0|10] ""  gtw
 SG_ DI_a200_MBPCheckStatus m200 : 16|1@1+ (1,0) [0|1] ""  gtw
 SG_ DI_a164_motorSpeed m164 : 16|16@1- (0.01,0) [-327.68|327.67] "MPH"  gtw
 SG_ DI_a057_pcbTemp m57 : 16|16@1- (0.1,0) [-3276.8|3276.7] "C"  gtw
 SG_ DI_a143_mechPowerLimit m143 : 16|1@1+ (1,0) [0|1] ""  gtw
 SG_ DI_a083_brakeSwitchNO m83 : 16|1@1+ (1,0) [0|1] ""  gtw
 SG_ DI_a044_outletTemp m44 : 16|16@1- (0.1,0) [-3276.8|3276.7] "C"  gtw
 SG_ DI_a160_vBatRawMinusFiltered m160 : 16|10@1- (1,0) [-512|511] "V"  gtw
 SG_ DI_a074_brazeFailCount m74 : 16|8@1+ (1,0) [0|255] ""  gtw
 SG_ DI_a011_reason m11 : 16|2@1+ (1,0) [0|3] ""  gtw
 SG_ DI_a055_parameterDI m55 : 16|13@1- (0.25,0.0) [-750|750] "Nm"  gtw
 SG_ DI_a193_brakeTorqueFrL m193 : 16|3@1+ (1,0) [0|7] ""  gtw
 SG_ DI_a103_fluidDeltaT m103 : 16|12@1- (0.1,67.5) [-60|195] "C"  gtw
 SG_ DI_a155_sensors m155 : 16|1@1+ (1,0) [0|1] ""  gtw
 SG_ DI_a071_busVslopeLimit m71 : 16|16@1+ (0.1,0) [0|6553.5] "V/ms"  gtw
 SG_ DI_a239_numRequests m239 : 16|16@1+ (1,0) [0|65535] ""  gtw
 SG_ DI_a177_newFitment m177 : 16|2@1+ (1,0) [0|3] ""  gtw
 SG_ DI_a243_logId m243 : 16|4@1+ (1,0) [0|15] ""  gtw
 SG_ DI_a032_phaseBoffset m32 : 16|16@1- (0.002,0) [-65.536|65.534] "A"  gtw
 SG_ DI_a162_motorSpeed m162 : 16|16@1- (0.01,0) [-327.68|327.67] "MPH"  gtw
 SG_ DI_a147_overtorque1UsedCount m147 : 16|8@1+ (1,0) [0|255] ""  gtw
 SG_ DI_a212_wheelSpeedCGFrL m212 : 16|3@1+ (1,0) [0|7] ""  gtw
 SG_ DI_a175_crsNotAvailableReason m175 : 16|5@1+ (1,0) [0|20] ""  gtw
 SG_ DI_a106_ABS_A m106 : 16|1@1+ (1,0) [0|1] ""  gtw
 SG_ DI_a000_alertDataW0 m0 : 16|16@1+ (1,0) [0|65535] ""  X
 SG_ DI_a170_foulTimer m170 : 16|16@1+ (1,0) [0|65535] ""  gtw
 SG_ DI_a028_phaseAirms m28 : 16|16@1+ (1,0) [0|65535] "A"  gtw
 SG_ DI_a051_dcCableCurrentEst m51 : 16|16@1- (0.1,0) [-3276.8|3276.7] "A"  gtw
 SG_ DI_a157_RCM_inertial1 m157 : 16|1@1+ (1,0) [0|1] ""  gtw
 SG_ DI_a087_gtwCarConfig m87 : 16|1@1+ (1,0) [0|1] ""  gtw
 SG_ DI_a116_elecPower m116 : 16|16@1- (0.5,0) [-16384|16383.5] "KW"  gtw
 SG_ DI_a113_ph1Temp m113 : 16|16@1- (0.1,0) [-3276.8|3276.7] "C"  gtw
 SG_ DI_a056_pcbTemp m56 : 16|16@1- (0.1,0) [-3276.8|3276.7] "C"  gtw
 SG_ DI_a152_errorType m152 : 16|3@1+ (1,0) [0|6] ""  gtw
 SG_ DI_a148_overtorque1UsedCount m148 : 16|10@1+ (1,0) [0|1023] ""  gtw
 SG_ DI_a208_motorTorqueRe m208 : 16|3@1+ (1,0) [0|7] ""  gtw
 SG_ DI_a075_motorSpeed m75 : 16|16@1+ (1,0) [0|65535] "RPM"  gtw
 SG_ DI_a217_IrrationalOutputReason m217 : 16|3@1+ (1,0) [0|4] ""  gtw
 SG_ DI_a082_track1Voltage m82 : 16|16@1+ (0.001,0) [0|65.535] "V"  gtw
 SG_ DI_a151_torqueMotor m151 : 16|16@1- (0.25,0) [-750|750] "Nm"  gtw
 SG_ DI_a077_12vSupply m77 : 16|16@1+ (0.001,0) [0|65.535] "V"  gtw
 SG_ DI_a054_outletTemp m54 : 16|16@1- (0.1,0) [-3276.8|3276.7] "C"  gtw
 SG_ DI_a027_rawIc m27 : 16|16@1- (1,0) [-32768|32767] ""  gtw
 SG_ DI_a220_vdcActivationAlertType m220 : 16|2@1+ (1,0) [0|2] ""  gtw
 SG_ DI_a036_busVoltage m36 : 16|16@1+ (0.1,0) [0|6553.5] "V"  gtw
 SG_ DI_a213_wheelSpeedCGReL m213 : 16|3@1+ (1,0) [0|7] ""  gtw
 SG_ DI_a026_rawIb m26 : 16|16@1- (1,0) [-32768|32767] ""  gtw
 SG_ DI_a093_mailboxID m93 : 16|16@1+ (1,0) [0|65535] ""  gtw
 SG_ DI_a034_phaseBcurrent m34 : 16|16@1- (1,0) [-32768|32767] "A"  gtw
 SG_ DI_a198_MCPressure m198 : 16|3@1+ (1,0) [0|7] ""  gtw
 SG_ DI_a025_rawIa m25 : 16|16@1- (1,0) [-32768|32767] ""  gtw
 SG_ DI_a029_phaseBirms m29 : 16|16@1+ (1,0) [0|65535] "A"  gtw
 SG_ DI_a092_bmsStatus m92 : 16|1@1+ (1,0) [0|1] ""  gtw
 SG_ DI_a041_numAppliedSamples m41 : 16|8@1+ (1,0) [0|255] ""  gtw
 SG_ DI_a158_IBST_party1 m158 : 16|1@1+ (1,0) [0|1] ""  gtw
 SG_ DI_a214_wheelSpeedNonCGFrL m214 : 16|3@1+ (1,0) [0|7] ""  gtw
 SG_ DI_a067_canID m67 : 16|16@1+ (1,0) [0|65535] ""  gtw
 SG_ DI_a114_motorSpeed m114 : 16|16@1+ (1,0) [0|65535] "RPM"  gtw
 SG_ DI_a035_phaseAerror m35 : 16|1@1+ (1,0) [0|1] ""  gtw
 SG_ DI_a062_limpReason m62 : 16|5@1+ (1,0) [0|30] ""  gtw
 SG_ DI_a153_speed m153 : 16|7@1+ (2,0) [0|100] "%"  gtw
 SG_ DI_a161_EPAS3P_sysStatus m161 : 16|1@1+ (1,0) [0|1] ""  gtw
 SG_ DI_a172_motorSpeed m172 : 16|16@1- (0.01,0) [-327.68|327.67] "MPH"  gtw
 SG_ DI_a110_EPBL_status m110 : 16|1@1+ (1,0) [0|1] ""  gtw
 SG_ DI_a196_wheelSlipReL m196 : 16|3@1+ (1,0) [0|7] ""  gtw
 SG_ DI_a042_inletTemp m42 : 16|10@1+ (0.25,-60) [-60|195] "DegC"  gtw
 SG_ DI_a195_wheelSlipFrL m195 : 16|3@1+ (1,0) [0|7] ""  gtw
 SG_ DI_a108_fromState m108 : 16|8@1+ (1,0) [0|255] ""  gtw
 SG_ DI_a115_ph1Temp m115 : 16|8@1- (1,0) [-128|127] "C"  gtw
 SG_ DI_a099_watchdogReset m99 : 16|1@1+ (1,0) [0|1] ""  gtw
 SG_ DI_a218_vdcActivationAlertType m218 : 16|2@1+ (1,0) [0|2] ""  gtw
 SG_ DI_a216_MBPCheckStatus m216 : 16|1@1+ (1,0) [0|1] ""  gtw
 SG_ DI_a144_autopilot m144 : 16|1@1+ (1,0) [0|1] ""  gtw
 SG_ DI_a112_phaseAcurrent m112 : 16|16@1+ (1,0) [0|65535] "A"  gtw
 SG_ DI_a191_motorSpeed m191 : 16|16@1- (0.01,0) [-327.68|327.67] "MPH"  gtw
 SG_ DI_a232_velocityEstimatorState m232 : 16|3@1+ (1,0) [0|4] ""  gtw
 SG_ DI_a104_proxIrrationalReason m104 : 16|1@1+ (1,0) [0|1] ""  gtw
 SG_ DI_a096_const_fast m96 : 16|1@1+ (1,0) [0|1] ""  gtw
 SG_ DI_a233_missedMsgCount m233 : 16|4@1+ (1,0) [0|15] ""  gtw
 SG_ DI_a081_track1Voltage m81 : 16|16@1+ (0.001,0) [0|65.535] "V"  gtw
 SG_ DI_a244_desat m244 : 16|1@1+ (1,0) [0|1] ""  gtw
 SG_ DI_a060_heatsinkTemp m60 : 16|16@1- (0.1,0) [-3276.8|3276.7] "C"  gtw
 SG_ DI_a016_newSafeState m16 : 16|2@1+ (1,0) [0|3] ""  gtw
 SG_ DI_a141_DAS_control m141 : 16|1@1+ (1,0) [0|1] ""  gtw
 SG_ DI_a207_motorTorqueFr m207 : 16|3@1+ (1,0) [0|7] ""  gtw
 SG_ DI_a030_phaseCirms m30 : 16|16@1+ (1,0) [0|65535] "A"  gtw
 SG_ DI_a156_initialSafeState m156 : 16|2@1+ (1,0) [0|3] ""  gtw
 SG_ DI_a159_gradeEst m159 : 16|8@1- (0.5,0) [-64|63.5] "%"  gtw
 SG_ DI_a230_CMP_HVStatus m230 : 16|1@1+ (1,0) [0|1] ""  gtw
 SG_ DI_a225_hs1Implausible m225 : 16|1@1+ (1,0) [0|1] ""  gtw
 SG_ DI_a199_muVehicleLearnDown m199 : 16|5@1+ (0.05,0) [0|1.5] "-"  gtw
 SG_ DI_a125_maxDischargeCurrent m125 : 16|16@1- (0.1,0) [-3276.8|3276.7] "C"  gtw
 SG_ DI_a024_vBat m24 : 16|8@1+ (2,0) [0|510] "V"  gtw
 SG_ DI_a187_filteredAccel m187 : 16|16@1- (0.01,0) [-327.68|327.67] "m/s^2"  gtw
 SG_ DI_a135_vhldFaultReason m135 : 16|4@1+ (1,0) [0|10] ""  gtw
 SG_ DI_a012_accel1SupplyV m12 : 16|16@1+ (0.001,0) [0|65.535] "V"  gtw
 SG_ DI_a134_wheelSpeedDiffFrL m134 : 16|12@1- (0.0625,0) [-256|255] "kph"  gtw
 SG_ DI_a073_motorSpeedrpm m73 : 16|16@1- (1,0) [-32768|32767] "RPM"  gtw
 SG_ DI_a123_lossReason m123 : 16|2@1+ (1,0) [1|3] ""  gtw
 SG_ DI_a001_thermalWarning_H m1 : 16|1@1+ (1,0) [0|1] ""  gtw
 SG_ DI_a094_canID m94 : 16|12@1+ (1,0) [0|4095] ""  gtw
 SG_ DI_a040_torque m40 : 16|1@1+ (1,0) [0|1] ""  gtw
 SG_ DI_a202_reason m202 : 16|3@1+ (1,0) [0|7] ""  gtw
 SG_ DI_a189_accelPedal m189 : 16|5@1+ (3.125,0) [0|96.875] "%"  gtw
 SG_ DI_a204_longAccel m204 : 16|3@1+ (1,0) [0|7] ""  gtw
 SG_ DI_a078_adcRefChan m78 : 16|4@1+ (1,0) [0|15] ""  gtw
 SG_ DI_a080_track1Voltage m80 : 16|16@1+ (0.001,0) [0|65.535] "V"  gtw
 SG_ DI_a226_systState m226 : 16|4@1+ (1,0) [0|8] ""  gtw
 SG_ DI_a150_vBatRawMinusFiltered m150 : 16|10@1- (1,0) [-512|511] "V"  gtw
 SG_ DI_a002_thermalWarning_H m2 : 16|1@1+ (1,0) [0|1] ""  gtw
 SG_ DI_a209_vehicleSpeed m209 : 16|3@1+ (1,0) [0|7] ""  gtw
 SG_ DI_a154_motorRPM m154 : 16|16@1- (1,0) [-20000|20000] "RPM"  gtw
 SG_ DI_a219_vdcActivationAlertType m219 : 16|2@1+ (1,0) [0|2] ""  gtw
 SG_ DI_a122_taskID m122 : 16|4@1+ (1,0) [0|8] ""  gtw
 SG_ DI_a121_badRegReason m121 : 16|3@1+ (1,0) [1|5] ""  gtw
 SG_ DI_a014_motorSpeed m14 : 16|14@1- (2,0) [-16000|16000] "RPM"  gtw
 SG_ DI_a047_statorTemp1 m47 : 16|16@1- (0.1,0) [-3276.8|3276.7] "DegC"  gtw
 SG_ DI_a089_SCCM_rightStalk m89 : 16|1@1+ (1,0) [0|1] ""  gtw
 SG_ DI_a031_phaseAoffset m31 : 16|16@1- (0.002,0) [-65.536|65.534] "A"  gtw
 SG_ DI_a061_sensor m61 : 16|2@1+ (1,0) [0|2] ""  gtw
 SG_ DI_a063_gpoReason m63 : 16|4@1+ (1,0) [0|8] ""  gtw
 SG_ DI_a126_limpReason m126 : 16|5@1+ (1,0) [0|30] ""  gtw
 SG_ DI_a038_vBMS m38 : 16|12@1+ (0.2,0) [0|819] "V"  gtw
 SG_ DI_a227_hvState m227 : 16|3@1+ (1,0) [0|6] ""  gtw
 SG_ DI_a205_latAccel m205 : 16|3@1+ (1,0) [0|7] ""  gtw
 SG_ DI_a091_ESP_brakeTorque m91 : 16|1@1+ (1,0) [0|1] ""  gtw
 SG_ DI_a097_errorType m97 : 16|3@1+ (1,0) [0|6] ""  gtw
 SG_ DI_a173_brakeApply m173 : 16|16@1- (0.01,0) [-327.68|327.67] "bar"  gtw
 SG_ DI_a234_PCS_dcdcStatus m234 : 16|1@1+ (1,0) [0|1] ""  gtw
 SG_ DI_a136_spiErrorType m136 : 16|3@1+ (1,0) [0|7] ""  gtw
 SG_ DI_a206_verticalAccel m206 : 16|3@1+ (1,0) [0|7] ""  gtw
 SG_ DI_a201_maxRegenPower m201 : 16|16@1- (0.5,0) [-16384|16383.5] "KW"  gtw
 SG_ DI_a180_crsNotAvailableReason m180 : 16|5@1+ (1,0) [0|20] ""  gtw
 SG_ DI_a109_STW_ACTN_RQ m109 : 16|1@1+ (1,0) [0|1] ""  gtw
 SG_ DI_a228_bteDegraded m228 : 16|1@1+ (1,0) [0|1] ""  gtw
 SG_ DI_a149_speed m149 : 16|8@1+ (0.4,0) [0|100] "%"  gtw
 SG_ DI_a223_ptcState m223 : 16|3@1+ (1,0) [0|4] ""  gtw
 SG_ DI_a105_cpStatus m105 : 16|1@1+ (1,0) [0|1] ""  gtw
 SG_ DI_a088_uiChassisControl m88 : 16|1@1+ (1,0) [0|1] ""  gtw
 SG_ DI_a098_pwmCount m98 : 16|16@1+ (1,0) [0|65535] ""  gtw
 SG_ DI_a142_lashAngle m142 : 16|10@1+ (0.06,0) [0|60] "Deg"  gtw
 SG_ DI_a127_gpoReason m127 : 16|4@1+ (1,0) [0|8] ""  gtw
 SG_ DI_a043_outletTemp m43 : 16|16@1- (0.1,0) [-3276.8|3276.7] "C"  gtw
 SG_ DI_a124_undrivenWheelMPH m124 : 16|16@1+ (0.1,0) [0|6553.5] "MPH"  gtw
 SG_ DI_a058_pcbTemp m58 : 16|10@1+ (0.25,-60) [-60|195] "DegC"  gtw
 SG_ DI_a015_reason m15 : 16|1@1+ (1,0) [0|1] ""  gtw
 SG_ DI_a046_statorTemp1 m46 : 16|16@1- (0.1,0) [-3276.8|3276.7] "DegC"  gtw
 SG_ DI_a194_brakeTorqueReL m194 : 16|3@1+ (1,0) [0|7] ""  gtw
 SG_ DI_a131_totalTimeRemaining m131 : 16|16@1+ (1,0) [0|65535] ""  gtw
 SG_ DI_a197_wheelSaturationFrL m197 : 16|3@1+ (1,0) [0|7] ""  gtw
 SG_ DI_alertType : 15|1@1+ (1,0) [0|1] ""  gtw
 SG_ DI_alertID M : 0|8@1+ (1,0) [0|244] ""  gtw

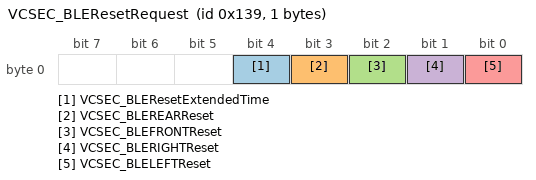
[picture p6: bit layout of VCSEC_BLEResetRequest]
BO_ 313 VCSEC_BLEResetRequest: 1 VEH
 SG_ VCSEC_BLEResetExtendedTime : 4|1@1+ (1,0) [0|1] ""  vcleft
 SG_ VCSEC_BLEREARReset : 3|1@1+ (1,0) [0|1] ""  vcleft
 SG_ VCSEC_BLEFRONTReset : 2|1@1+ (1,0) [0|1] ""  vcfront
 SG_ VCSEC_BLERIGHTReset : 1|1@1+ (1,0) [0|1] ""  vcright
 SG_ VCSEC_BLELEFTReset : 0|1@1+ (1,0) [0|1] ""  vcleft

BA_DEF_ SG_  "SystemSignalLongSymbol" STRING ;
BA_DEF_DEF_  "SystemSignalLongSymbol" "";
BA_ "SystemSignalLongSymbol" SG_ 1060 PCS_a038_dcdcPwmEnableDeasserted "PCS_a038_dcdcPwmEnableDeassertedCount";
BA_ "SystemSignalLongSymbol" SG_ 1060 PCS_a079_eepromOperationErrorCod "PCS_a079_eepromOperationErrorCode";
BA_ "SystemSignalLongSymbol" SG_ 1060 PCS_a025_bootromRequestStatusFla "PCS_a025_bootromRequestStatusFlag";
BA_ "SystemSignalLongSymbol" SG_ 1060 PCS_a076_dcdcPwmEnableDeasserted "PCS_a076_dcdcPwmEnableDeassertedCount";
BA_ "SystemSignalLongSymbol" SG_ 1318 DI_a221_understeerdMzYawRateErro "DI_a221_understeerdMzYawRateError";
BA_ "SystemSignalLongSymbol" SG_ 1318 DI_a220_understeerDecelInitThres "DI_a220_understeerDecelInitThresh";
BA_ "SystemSignalLongSymbol" SG_ 1318 DI_a215_wheelSpeedNonCGReRCurrVa "DI_a215_wheelSpeedNonCGReRCurrVal";
BA_ "SystemSignalLongSymbol" SG_ 1318 DI_a214_wheelSpeedNonCGFrRCurrVa "DI_a214_wheelSpeedNonCGFrRCurrVal";
BA_ "SystemSignalLongSymbol" SG_ 1318 DI_a215_wheelSpeedNonCGReRLastVa "DI_a215_wheelSpeedNonCGReRLastVal";
BA_ "SystemSignalLongSymbol" SG_ 1318 DI_a220_understeerDecelYawRateTa "DI_a220_understeerDecelYawRateTar";
BA_ "SystemSignalLongSymbol" SG_ 1318 DI_a214_wheelSpeedNonCGFrRLastVa "DI_a214_wheelSpeedNonCGFrRLastVal";
BA_ "SystemSignalLongSymbol" SG_ 1318 DI_a214_wheelSpeedNonCGFrLCurrVa "DI_a214_wheelSpeedNonCGFrLCurrVal";
BA_ "SystemSignalLongSymbol" SG_ 1318 DI_a215_wheelSpeedNonCGReLCurrVa "DI_a215_wheelSpeedNonCGReLCurrVal";
BA_ "SystemSignalLongSymbol" SG_ 1318 DI_a214_wheelSpeedNonCGFrLLastVa "DI_a214_wheelSpeedNonCGFrLLastVal";
BA_ "SystemSignalLongSymbol" SG_ 1318 DI_a215_wheelSpeedNonCGReLLastVa "DI_a215_wheelSpeedNonCGReLLastVal";
VAL_ 1060 PCS_alertSource 4 "PCS_ALERT_SOURCE_CHG_SYSTEM" 5 "PCS_ALERT_SOURCE_DCDC" 3 "PCS_ALERT_SOURCE_CHG_PHC" 0 "PCS_ALERT_SOURCE_DEFAULT" 2 "PCS_ALERT_SOURCE_CHG_PHB" 1 "PCS_ALERT_SOURCE_CHG_PHA" ;
VAL_ 1060 PCS_a073_cpType 1 "CP_TYPE_EURO_IEC" 0 "CP_TYPE_US_TESLA" 3 "CP_TYPE_IEC_CCS" 2 "CP_TYPE_GB" ;
VAL_ 1060 PCS_a054_phaseConfig 3 "PHASE_CONFIG_THREE_PHASE_DELTA" 1 "PHASE_CONFIG_SINGLE_PHASE" 4 "PHASE_CONFIG_SINGLE_PHASE_IEC_GB" 5 "PHASE_CONFIG_MFG_TEST_CONFIG_1" 2 "PHASE_CONFIG_THREE_PHASE" 0 "PHASE_CONFIG_SNA" 7 "PHASE_CONFIG_RELIABILITY_SINGLE_PHASE" 6 "PHASE_CONFIG_MFG_TEST_CONFIG_2" 8 "PHASE_CONFIG_TOTAL_NUM" ;
VAL_ 1060 PCS_a053_phaseConfig 3 "PHASE_CONFIG_THREE_PHASE_DELTA" 1 "PHASE_CONFIG_SINGLE_PHASE" 4 "PHASE_CONFIG_SINGLE_PHASE_IEC_GB" 5 "PHASE_CONFIG_MFG_TEST_CONFIG_1" 2 "PHASE_CONFIG_THREE_PHASE" 0 "PHASE_CONFIG_SNA" 7 "PHASE_CONFIG_RELIABILITY_SINGLE_PHASE" 6 "PHASE_CONFIG_MFG_TEST_CONFIG_2" 8 "PHASE_CONFIG_TOTAL_NUM" ;
VAL_ 1060 PCS_a013_inputFrequency 0 "FREQUENCY_UNKNOWN" ;
VAL_ 1060 PCS_a006_inputFrequency 0 "FREQUENCY_UNKNOWN" ;
VAL_ 1060 PCS_a073_phaseConfig 3 "PHASE_CONFIG_THREE_PHASE_DELTA" 1 "PHASE_CONFIG_SINGLE_PHASE" 4 "PHASE_CONFIG_SINGLE_PHASE_IEC_GB" 5 "PHASE_CONFIG_MFG_TEST_CONFIG_1" 2 "PHASE_CONFIG_THREE_PHASE" 0 "PHASE_CONFIG_SNA" 7 "PHASE_CONFIG_RELIABILITY_SINGLE_PHASE" 6 "PHASE_CONFIG_MFG_TEST_CONFIG_2" 8 "PHASE_CONFIG_TOTAL_NUM" ;
VAL_ 1060 PCS_a090_evaluatedGridConfig 3 "PHASE_CONFIG_THREE_PHASE_DELTA" 1 "PHASE_CONFIG_SINGLE_PHASE" 4 "PHASE_CONFIG_SINGLE_PHASE_IEC_GB" 5 "PHASE_CONFIG_MFG_TEST_CONFIG_1" 2 "PHASE_CONFIG_THREE_PHASE" 0 "PHASE_CONFIG_SNA" 7 "PHASE_CONFIG_RELIABILITY_SINGLE_PHASE" 6 "PHASE_CONFIG_MFG_TEST_CONFIG_2" 8 "PHASE_CONFIG_TOTAL_NUM" ;
VAL_ 1060 PCS_a070_inputFrequency 0 "FREQUENCY_UNKNOWN" ;
VAL_ 1060 PCS_a069_inputFrequency 0 "FREQUENCY_UNKNOWN" ;
VAL_ 1060 PCS_a029_phaseConfig 3 "PHASE_CONFIG_THREE_PHASE_DELTA" 1 "PHASE_CONFIG_SINGLE_PHASE" 4 "PHASE_CONFIG_SINGLE_PHASE_IEC_GB" 5 "PHASE_CONFIG_MFG_TEST_CONFIG_1" 2 "PHASE_CONFIG_THREE_PHASE" 0 "PHASE_CONFIG_SNA" 7 "PHASE_CONFIG_RELIABILITY_SINGLE_PHASE" 6 "PHASE_CONFIG_MFG_TEST_CONFIG_2" 8 "PHASE_CONFIG_TOTAL_NUM" ;
VAL_ 1060 PCS_a082_faultedSubstate 13 "DCDC_SUBSTATE_DIS_HVBUS_FAULTED" 4 "DCDC_SUBSTATE_PCHG_FAST_DIS_HVBUS" 15 "DCDC_SUBSTATE_CLEAR_FAULTS" 7 "DCDC_SUBSTATE_PCHG_DWELL_WAIT" 12 "DCDC_SUBSTATE_12V_SUPPORT_FAULTED" 8 "DCDC_SUBSTATE_PCHG_DI_RECOVERY_WAIT" 17 "DCDC_SUBSTATE_NUM" 10 "DCDC_SUBSTATE_PCHG_FLT_FAST_DIS_HVBUS" 2 "DCDC_SUBSTATE_12V_SUPPORT_ACTIVE" 3 "DCDC_SUBSTATE_DIS_HVBUS" 14 "DCDC_SUBSTATE_PCHG_FAULTED" 11 "DCDC_SUBSTATE_SHUTDOWN" 1 "DCDC_SUBSTATE_STANDBY" 9 "DCDC_SUBSTATE_PCHG_ACTIVE" 16 "DCDC_SUBSTATE_FAULTED" 6 "DCDC_SUBSTATE_PCHG_DWELL_CHARGE" 5 "DCDC_SUBSTATE_PCHG_SLOW_DIS_HVBUS" 0 "DCDC_SUBSTATE_PWR_UP_INIT" ;
VAL_ 1060 PCS_a081_faultedSubstate 13 "DCDC_SUBSTATE_DIS_HVBUS_FAULTED" 4 "DCDC_SUBSTATE_PCHG_FAST_DIS_HVBUS" 15 "DCDC_SUBSTATE_CLEAR_FAULTS" 7 "DCDC_SUBSTATE_PCHG_DWELL_WAIT" 12 "DCDC_SUBSTATE_12V_SUPPORT_FAULTED" 8 "DCDC_SUBSTATE_PCHG_DI_RECOVERY_WAIT" 17 "DCDC_SUBSTATE_NUM" 10 "DCDC_SUBSTATE_PCHG_FLT_FAST_DIS_HVBUS" 2 "DCDC_SUBSTATE_12V_SUPPORT_ACTIVE" 3 "DCDC_SUBSTATE_DIS_HVBUS" 14 "DCDC_SUBSTATE_PCHG_FAULTED" 11 "DCDC_SUBSTATE_SHUTDOWN" 1 "DCDC_SUBSTATE_STANDBY" 9 "DCDC_SUBSTATE_PCHG_ACTIVE" 16 "DCDC_SUBSTATE_FAULTED" 6 "DCDC_SUBSTATE_PCHG_DWELL_CHARGE" 5 "DCDC_SUBSTATE_PCHG_SLOW_DIS_HVBUS" 0 "DCDC_SUBSTATE_PWR_UP_INIT" ;
VAL_ 1060 PCS_a071_inputFrequency 0 "FREQUENCY_UNKNOWN" ;
VAL_ 1060 PCS_a067_vcfrontVcrightVoltage 1023 "SNA" ;
VAL_ 1060 PCS_a001_phState 4 "PCS_PH_STATE_FAULT" 2 "PCS_PH_STATE_PRECHARGE" 1 "PCS_PH_STATE_IDLE" 5 "PCS_PH_STATE_CLEAR_FAULTS" 0 "PCS_PH_STATE_INIT" 6 "PCS_PH_STATE_SHUTTING_DOWN" 3 "PCS_PH_STATE_ENABLE" ;
VAL_ 1060 PCS_a080_phCNVRAMStoredState 1 "CHG_PH_BOOTCHECK_NVRAM_RUNNING_CNT_0" 2 "CHG_PH_BOOTCHECK_NVRAM_RUNNING_CNT_1" 0 "CHG_PH_BOOTCHECK_NVRAM_PENDING" 4 "CHG_PH_BOOTCHECK_NVRAM_RUNNING_CNT_EXPIRED" 3 "CHG_PH_BOOTCHECK_NVRAM_RUNNING_CNT_2" ;
VAL_ 1060 PCS_a057_inputFrequency 0 "FREQUENCY_UNKNOWN" ;
VAL_ 1060 PCS_a065_inputFrequency 0 "FREQUENCY_UNKNOWN" ;
VAL_ 1060 PCS_a067_vcfrontPcsEFuseV 1023 "SNA" ;
VAL_ 1060 PCS_a058_inputFrequency 0 "FREQUENCY_UNKNOWN" ;
VAL_ 1060 PCS_a080_phBNVRAMStoredState 1 "CHG_PH_BOOTCHECK_NVRAM_RUNNING_CNT_0" 2 "CHG_PH_BOOTCHECK_NVRAM_RUNNING_CNT_1" 0 "CHG_PH_BOOTCHECK_NVRAM_PENDING" 4 "CHG_PH_BOOTCHECK_NVRAM_RUNNING_CNT_EXPIRED" 3 "CHG_PH_BOOTCHECK_NVRAM_RUNNING_CNT_2" ;
VAL_ 1060 PCS_a038_dcdcSubState 13 "DCDC_SUBSTATE_DIS_HVBUS_FAULTED" 4 "DCDC_SUBSTATE_PCHG_FAST_DIS_HVBUS" 15 "DCDC_SUBSTATE_CLEAR_FAULTS" 7 "DCDC_SUBSTATE_PCHG_DWELL_WAIT" 12 "DCDC_SUBSTATE_12V_SUPPORT_FAULTED" 8 "DCDC_SUBSTATE_PCHG_DI_RECOVERY_WAIT" 17 "DCDC_SUBSTATE_NUM" 10 "DCDC_SUBSTATE_PCHG_FLT_FAST_DIS_HVBUS" 2 "DCDC_SUBSTATE_12V_SUPPORT_ACTIVE" 3 "DCDC_SUBSTATE_DIS_HVBUS" 14 "DCDC_SUBSTATE_PCHG_FAULTED" 11 "DCDC_SUBSTATE_SHUTDOWN" 1 "DCDC_SUBSTATE_STANDBY" 9 "DCDC_SUBSTATE_PCHG_ACTIVE" 16 "DCDC_SUBSTATE_FAULTED" 6 "DCDC_SUBSTATE_PCHG_DWELL_CHARGE" 5 "DCDC_SUBSTATE_PCHG_SLOW_DIS_HVBUS" 0 "DCDC_SUBSTATE_PWR_UP_INIT" ;
VAL_ 1060 PCS_a079_eepromOperationRegion 1 "EEPROM_PRIMARY_REGION" 3 "EEPROM_UNDEFINED_REGION" 2 "EEPROM_SECONDARY_REGION" 0 "EEPROM_VALIDITY_REGION" ;
VAL_ 1060 PCS_a080_phANVRAMStoredState 1 "CHG_PH_BOOTCHECK_NVRAM_RUNNING_CNT_0" 2 "CHG_PH_BOOTCHECK_NVRAM_RUNNING_CNT_1" 0 "CHG_PH_BOOTCHECK_NVRAM_PENDING" 4 "CHG_PH_BOOTCHECK_NVRAM_RUNNING_CNT_EXPIRED" 3 "CHG_PH_BOOTCHECK_NVRAM_RUNNING_CNT_2" ;
VAL_ 1060 PCS_a076_dcdcSubState 13 "DCDC_SUBSTATE_DIS_HVBUS_FAULTED" 4 "DCDC_SUBSTATE_PCHG_FAST_DIS_HVBUS" 15 "DCDC_SUBSTATE_CLEAR_FAULTS" 7 "DCDC_SUBSTATE_PCHG_DWELL_WAIT" 12 "DCDC_SUBSTATE_12V_SUPPORT_FAULTED" 8 "DCDC_SUBSTATE_PCHG_DI_RECOVERY_WAIT" 17 "DCDC_SUBSTATE_NUM" 10 "DCDC_SUBSTATE_PCHG_FLT_FAST_DIS_HVBUS" 2 "DCDC_SUBSTATE_12V_SUPPORT_ACTIVE" 3 "DCDC_SUBSTATE_DIS_HVBUS" 14 "DCDC_SUBSTATE_PCHG_FAULTED" 11 "DCDC_SUBSTATE_SHUTDOWN" 1 "DCDC_SUBSTATE_STANDBY" 9 "DCDC_SUBSTATE_PCHG_ACTIVE" 16 "DCDC_SUBSTATE_FAULTED" 6 "DCDC_SUBSTATE_PCHG_DWELL_CHARGE" 5 "DCDC_SUBSTATE_PCHG_SLOW_DIS_HVBUS" 0 "DCDC_SUBSTATE_PWR_UP_INIT" ;
VAL_ 1060 PCS_a070_phState 4 "PCS_PH_STATE_FAULT" 2 "PCS_PH_STATE_PRECHARGE" 1 "PCS_PH_STATE_IDLE" 5 "PCS_PH_STATE_CLEAR_FAULTS" 0 "PCS_PH_STATE_INIT" 6 "PCS_PH_STATE_SHUTTING_DOWN" 3 "PCS_PH_STATE_ENABLE" ;
VAL_ 1060 PCS_a069_phState 4 "PCS_PH_STATE_FAULT" 2 "PCS_PH_STATE_PRECHARGE" 1 "PCS_PH_STATE_IDLE" 5 "PCS_PH_STATE_CLEAR_FAULTS" 0 "PCS_PH_STATE_INIT" 6 "PCS_PH_STATE_SHUTTING_DOWN" 3 "PCS_PH_STATE_ENABLE" ;
VAL_ 1060 PCS_a038_dcdcClaFaultCode 7 "PCS_DCDC_CLA_FAULT_VTANK_DVDT" 4 "PCS_DCDC_CLA_FAULT_LV_BRD_A_BOOTSTRAP_PRD" 0 "PCS_DCDC_CLA_FAULT_NOT_FAULTED" 6 "PCS_DCDC_CLA_FAULT_TBCTR_TIMEOUT" 8 "PCS_DCDC_CLA_FAULT_DEBUG_FORCED" 1 "PCS_DCDC_CLA_FAULT_UNEQUAL_PERIOD" 5 "PCS_DCDC_CLA_FAULT_LV_BRD_B_BOOTSTRAP_PRD" 2 "PCS_DCDC_CLA_FAULT_UNEQUAL_ONTIME" 3 "PCS_DCDC_CLA_FAULT_UNEQUAL_ONTIME_ACCUM" ;
VAL_ 1060 PCS_a071_phState 4 "PCS_PH_STATE_FAULT" 2 "PCS_PH_STATE_PRECHARGE" 1 "PCS_PH_STATE_IDLE" 5 "PCS_PH_STATE_CLEAR_FAULTS" 0 "PCS_PH_STATE_INIT" 6 "PCS_PH_STATE_SHUTTING_DOWN" 3 "PCS_PH_STATE_ENABLE" ;
VAL_ 1060 PCS_a003_phState 4 "PCS_PH_STATE_FAULT" 2 "PCS_PH_STATE_PRECHARGE" 1 "PCS_PH_STATE_IDLE" 5 "PCS_PH_STATE_CLEAR_FAULTS" 0 "PCS_PH_STATE_INIT" 6 "PCS_PH_STATE_SHUTTING_DOWN" 3 "PCS_PH_STATE_ENABLE" ;
VAL_ 1060 PCS_a004_phState 4 "PCS_PH_STATE_FAULT" 2 "PCS_PH_STATE_PRECHARGE" 1 "PCS_PH_STATE_IDLE" 5 "PCS_PH_STATE_CLEAR_FAULTS" 0 "PCS_PH_STATE_INIT" 6 "PCS_PH_STATE_SHUTTING_DOWN" 3 "PCS_PH_STATE_ENABLE" ;
VAL_ 1060 PCS_a079_eepromOperation 0 "EEPROM_READ_REGION_VALIDITY" 7 "EEPROM_WRITE_RECORD_METADATA" 4 "EEPROM_READ_RECORD_DATA" 15 "EEPROM_OPERATION_SNA" 1 "EEPROM_READ_REGION_VALIDITY_MARKERS" 9 "EEPROM_WRITE_RECORD_DATA" 6 "EEPROM_WRITE_VALIDITY_MARKER" 2 "EEPROM_READ_RECORD_METADATA" 5 "EEPROM_WRITE_REGION_VALIDITY" 8 "EEPROM_WRITE_RECORD_DESC" 3 "EEPROM_READ_RECORD_DESC" ;
VAL_ 1060 PCS_a010_phState 4 "PCS_PH_STATE_FAULT" 2 "PCS_PH_STATE_PRECHARGE" 1 "PCS_PH_STATE_IDLE" 5 "PCS_PH_STATE_CLEAR_FAULTS" 0 "PCS_PH_STATE_INIT" 6 "PCS_PH_STATE_SHUTTING_DOWN" 3 "PCS_PH_STATE_ENABLE" ;
VAL_ 1060 PCS_a025_cpu2ErrorCode 1 "PCS_CPU2_ERROR_LOSSCOMMS_BOOTLOADER" 10 "PCS_CPU2_ERROR_CPU2_HWID_CHK_INCOMPLETED" 3 "PCS_CPU2_ERROR_APPCRC_MISMATCH" 0 "PCS_CPU2_ERROR_NONE" 6 "PCS_CPU2_ERROR_BOOTLOADER_STATUS_INVALID" 9 "PCS_CPU2_ERROR_CRC_VALIDATION_FAILED" 4 "PCS_CPU2_ERROR_BOOTSTATUS_INVALID" 8 "PCS_CPU2_ERROR_APP_HWID_BAD" 7 "PCS_CPU2_ERROR_FAILED_TO_RETRIEVE_HWID" 2 "PCS_CPU2_ERROR_NO_APP_INSTALLED" 5 "PCS_CPU2_ERROR_FAILED_TO_RETRIEVE_APPCRC" ;
VAL_ 1060 PCS_a009_phState 4 "PCS_PH_STATE_FAULT" 2 "PCS_PH_STATE_PRECHARGE" 1 "PCS_PH_STATE_IDLE" 5 "PCS_PH_STATE_CLEAR_FAULTS" 0 "PCS_PH_STATE_INIT" 6 "PCS_PH_STATE_SHUTTING_DOWN" 3 "PCS_PH_STATE_ENABLE" ;
VAL_ 1060 PCS_a030_canRxErrorType 1 "PCS_CAN_ERR_LENGTH_SHORT" 2 "PCS_CAN_ERR_LENGTH_LONG" 4 "PCS_CAN_ERR_SEQUENCE" 0 "PCS_CAN_ERR_NONE" 6 "PCS_CAN_ERR_UNKNOWN_ID" 5 "PCS_CAN_ERR_DATAINVALID" 3 "PCS_CAN_ERR_CHECKSUM" ;
VAL_ 1060 PCS_a002_phState 4 "PCS_PH_STATE_FAULT" 2 "PCS_PH_STATE_PRECHARGE" 1 "PCS_PH_STATE_IDLE" 5 "PCS_PH_STATE_CLEAR_FAULTS" 0 "PCS_PH_STATE_INIT" 6 "PCS_PH_STATE_SHUTTING_DOWN" 3 "PCS_PH_STATE_ENABLE" ;
VAL_ 1060 PCS_a007_phState 4 "PCS_PH_STATE_FAULT" 2 "PCS_PH_STATE_PRECHARGE" 1 "PCS_PH_STATE_IDLE" 5 "PCS_PH_STATE_CLEAR_FAULTS" 0 "PCS_PH_STATE_INIT" 6 "PCS_PH_STATE_SHUTTING_DOWN" 3 "PCS_PH_STATE_ENABLE" ;
VAL_ 1060 PCS_a076_pcsControlRequest 1 "SUPPORT" 0 "SHUTDOWN" 3 "DISCHARGE" 2 "PRECHARGE" ;
VAL_ 1060 PCS_a008_phState 4 "PCS_PH_STATE_FAULT" 2 "PCS_PH_STATE_PRECHARGE" 1 "PCS_PH_STATE_IDLE" 5 "PCS_PH_STATE_CLEAR_FAULTS" 0 "PCS_PH_STATE_INIT" 6 "PCS_PH_STATE_SHUTTING_DOWN" 3 "PCS_PH_STATE_ENABLE" ;
VAL_ 1060 PCS_a011_phState 4 "PCS_PH_STATE_FAULT" 2 "PCS_PH_STATE_PRECHARGE" 1 "PCS_PH_STATE_IDLE" 5 "PCS_PH_STATE_CLEAR_FAULTS" 0 "PCS_PH_STATE_INIT" 6 "PCS_PH_STATE_SHUTTING_DOWN" 3 "PCS_PH_STATE_ENABLE" ;
VAL_ 1060 PCS_a006_phState 4 "PCS_PH_STATE_FAULT" 2 "PCS_PH_STATE_PRECHARGE" 1 "PCS_PH_STATE_IDLE" 5 "PCS_PH_STATE_CLEAR_FAULTS" 0 "PCS_PH_STATE_INIT" 6 "PCS_PH_STATE_SHUTTING_DOWN" 3 "PCS_PH_STATE_ENABLE" ;
VAL_ 1060 PCS_a012_phState 4 "PCS_PH_STATE_FAULT" 2 "PCS_PH_STATE_PRECHARGE" 1 "PCS_PH_STATE_IDLE" 5 "PCS_PH_STATE_CLEAR_FAULTS" 0 "PCS_PH_STATE_INIT" 6 "PCS_PH_STATE_SHUTTING_DOWN" 3 "PCS_PH_STATE_ENABLE" ;
VAL_ 1060 PCS_a044_FaultReasonCode 2 "PCS_DCDC_12V_REGULATOR_WRONG_DIRECTION" 3 "PCS_DCDC_12V_REGULATOR_IRRATIONAL_SHORTTIME" 1 "PCS_DCDC_12V_REGULATOR_HIGH_CURRENT" 0 "PCS_DCDC_12V_REGULATOR_SNA" ;
VAL_ 1060 PCS_a051_phState 4 "PCS_PH_STATE_FAULT" 2 "PCS_PH_STATE_PRECHARGE" 1 "PCS_PH_STATE_IDLE" 5 "PCS_PH_STATE_CLEAR_FAULTS" 0 "PCS_PH_STATE_INIT" 6 "PCS_PH_STATE_SHUTTING_DOWN" 3 "PCS_PH_STATE_ENABLE" ;
VAL_ 1060 PCS_a013_phState 4 "PCS_PH_STATE_FAULT" 2 "PCS_PH_STATE_PRECHARGE" 1 "PCS_PH_STATE_IDLE" 5 "PCS_PH_STATE_CLEAR_FAULTS" 0 "PCS_PH_STATE_INIT" 6 "PCS_PH_STATE_SHUTTING_DOWN" 3 "PCS_PH_STATE_ENABLE" ;
VAL_ 1060 PCS_alertType 0 "ALERT_CLEARED" 1 "ALERT_SET" ;
VAL_ 1060 PCS_alertID 47 "PCS_a047_lvBusLowImpedance" 13 "PCS_a013_chgPrechargeFailedBoost" 61 "PCS_a061_chgVLineRationality" 42 "PCS_a042_dcdcEnableLineMismatch" 20 "PCS_a020_chgEnableLineMismatch" 74 "PCS_a074_hvBusDischargeFailure" 69 "PCS_a069_chgPfcLineDidt" 80 "PCS_a080_damagedPhaseDetected" 54 "PCS_a054_chgInputVDropTooHigh" 14 "PCS_a014_chgTempRationality" 35 "PCS_a035_lvBusUv" 45 "PCS_a045_hvBusLowImpedance" 31 "PCS_a031_uiMia" 26 "PCS_a026_watchdogAlarmed" 78 "PCS_a078_chgStopDcdcTooHot" 30 "PCS_a030_canRationality" 28 "PCS_a028_chgOutputUv" 73 "PCS_a073_unexpectedAcInputVoltage" 3 "PCS_a003_chgHwInputOv" 5 "PCS_a005_chgOutputOv" 0 "PCS_ALERT_DO_NOT_USE_ZERO" 48 "PCS_a048_lvBusHighImpedance" 65 "PCS_a065_chgPllNotLocked" 10 "PCS_a010_chgIntBusVRegulation" 66 "PCS_a066_dcdcHvRationality" 76 "PCS_a076_dcdcEnDeassertedErr" 9 "PCS_a009_chgPfcCurrentRegulation" 16 "PCS_a016_chgAllPhasesFaulted" 17 "PCS_a017_chgWallPowerRemoval" 53 "PCS_a053_chgInputVDropHigh" 32 "PCS_a032_unused" 91 "PCS_a091_chgIntBusRationality" 67 "PCS_a067_dcdcLvRationality" 29 "PCS_a029_chgPowerRationality" 89 "PCS_a089_hvBusDischargeIrrational" 37 "PCS_a037_resonantTankOc" 88 "PCS_a088_pchgParameters" 57 "PCS_a057_chgInputOverFreq" 68 "PCS_a068_dcdcTankvRationality" 6 "PCS_a006_chgPrechargeFailedScr" 90 "PCS_a090_expectedAcVoltageSourceMissing" 15 "PCS_a015_chg12vUv" 81 "PCS_a081_dcdcPchgTimeout" 85 "PCS_a085_dcdcFetsNotSwitching" 72 "PCS_a072_cpu2ClaStopped" 46 "PCS_a046_hvBusHighImpedence" 38 "PCS_a038_claFaulted" 44 "PCS_a044_12vSupportRegulation" 79 "PCS_a079_eepromOperationError" 40 "PCS_a040_dcdcMaxPowerReached" 7 "PCS_a007_chgPhaseTempHot" 12 "PCS_a012_chgPfcIBandTracerFault" 59 "PCS_a059_chgInputOvRms" 82 "PCS_a082_dcdcPchgUnsafeDiVoltage" 19 "PCS_a019_acChargePowerLimited" 27 "PCS_a027_chgInsufficientCooling" 51 "PCS_a051_chgIntBusUv" 71 "PCS_a071_chgPfcILoopRationality" 86 "PCS_a086_dcdcInsufficientCooling" 34 "PCS_a034_hvBusOv" 77 "PCS_a077_microGridEnergyLow" 50 "PCS_a050_dcdc12VsupportFaulted" 8 "PCS_a008_chgPhaseOverTemp" 39 "PCS_a039_sdModuleClkFault" 52 "PCS_a052_acVoltageNotPresent" 62 "PCS_a062_chgILineRationality" 33 "PCS_a033_hvBusUv" 22 "PCS_a022_bmsMia" 25 "PCS_a025_cpu2Malfunction" 4 "PCS_a004_chgHwIntBusOv" 11 "PCS_a011_chgLlcCurrentRegulation" 2 "PCS_a002_chgHwOutputOc" 70 "PCS_a070_chgPfcLineDvdt" 36 "PCS_a036_lvBusOv" 60 "PCS_a060_chgInputOvPeak" 49 "PCS_a049_dcdcTempRationality" 41 "PCS_a041_dcdcOverTemp" 83 "PCS_a083_triggerOdin" 56 "PCS_a056_chgLineImedanceTooHigh" 58 "PCS_a058_chgInputUnderFreq" 64 "PCS_a064_chgIOutRationality" 23 "PCS_a023_cpMia" 63 "PCS_a063_chgVOutRationality" 75 "PCS_a075_hvBusDischargeTimeout" 18 "PCS_a018_chgUnknownGridConfig" 24 "PCS_a024_vcfrontMia" 1 "PCS_a001_chgHwInputOc" 21 "PCS_a021_hvpMia" 87 "PCS_a087_nvramRecordStatusError" 55 "PCS_a055_chgLineImedanceHigh" 43 "PCS_a043_hvBusPrechargeFailure" 84 "PCS_a084_unused" ;
VAL_ 1009 VCFRONT_simLatchingStalk 0 "SIMULATED_LATCHING_STALK_IDLE" 3 "SIMULATED_LATCHING_STALK_SNA" 1 "SIMULATED_LATCHING_STALK_LEFT" 2 "SIMULATED_LATCHING_STALK_RIGHT" ;
VAL_ 1009 VCFRONT_parkRightStatus 3 "LIGHT_SNA" 1 "LIGHT_ON" 0 "LIGHT_OFF" 2 "LIGHT_FAULT" ;
VAL_ 1009 VCFRONT_parkLeftStatus 3 "LIGHT_SNA" 1 "LIGHT_ON" 0 "LIGHT_OFF" 2 "LIGHT_FAULT" ;
VAL_ 1009 VCFRONT_turnSignalRightStatus 3 "LIGHT_SNA" 1 "LIGHT_ON" 0 "LIGHT_OFF" 2 "LIGHT_FAULT" ;
VAL_ 1009 VCFRONT_turnSignalLeftStatus 3 "LIGHT_SNA" 1 "LIGHT_ON" 0 "LIGHT_OFF" 2 "LIGHT_FAULT" ;
VAL_ 1009 VCFRONT_sideRepeaterRightStatus 3 "LIGHT_SNA" 1 "LIGHT_ON" 0 "LIGHT_OFF" 2 "LIGHT_FAULT" ;
VAL_ 1009 VCFRONT_sideRepeaterLeftStatus 3 "LIGHT_SNA" 1 "LIGHT_ON" 0 "LIGHT_OFF" 2 "LIGHT_FAULT" ;
VAL_ 1009 VCFRONT_sideMarkersStatus 3 "LIGHT_SNA" 1 "LIGHT_ON" 0 "LIGHT_OFF" 2 "LIGHT_FAULT" ;
VAL_ 1009 VCFRONT_fogRightStatus 3 "LIGHT_SNA" 1 "LIGHT_ON" 0 "LIGHT_OFF" 2 "LIGHT_FAULT" ;
VAL_ 1009 VCFRONT_fogLeftStatus 3 "LIGHT_SNA" 1 "LIGHT_ON" 0 "LIGHT_OFF" 2 "LIGHT_FAULT" ;
VAL_ 1009 VCFRONT_DRLRightStatus 3 "LIGHT_SNA" 1 "LIGHT_ON" 0 "LIGHT_OFF" 2 "LIGHT_FAULT" ;
VAL_ 1009 VCFRONT_DRLLeftStatus 3 "LIGHT_SNA" 1 "LIGHT_ON" 0 "LIGHT_OFF" 2 "LIGHT_FAULT" ;
VAL_ 1009 VCFRONT_highBeamRightStatus 3 "LIGHT_SNA" 1 "LIGHT_ON" 0 "LIGHT_OFF" 2 "LIGHT_FAULT" ;
VAL_ 1009 VCFRONT_highBeamLeftStatus 3 "LIGHT_SNA" 1 "LIGHT_ON" 0 "LIGHT_OFF" 2 "LIGHT_FAULT" ;
VAL_ 1009 VCFRONT_lowBeamRightStatus 3 "LIGHT_SNA" 1 "LIGHT_ON" 0 "LIGHT_OFF" 2 "LIGHT_FAULT" ;
VAL_ 1009 VCFRONT_lowBeamLeftStatus 3 "LIGHT_SNA" 1 "LIGHT_ON" 0 "LIGHT_OFF" 2 "LIGHT_FAULT" ;
VAL_ 1009 VCFRONT_switchLightingBrightness 255 "SNA" ;
VAL_ 1009 VCFRONT_ambientLightingBrightnes 255 "SNA" ;
VAL_ 1009 VCFRONT_hazardLightRequest 1 "HAZARD_REQUEST_BUTTON" 5 "HAZARD_REQUEST_CRASH" 4 "HAZARD_REQUEST_MISLOCK" 6 "HAZARD_REQUEST_CAR_ALARM" 0 "HAZARD_REQUEST_NONE" 3 "HAZARD_REQUEST_UNLOCK" 7 "HAZARD_REQUEST_DAS" 2 "HAZARD_REQUEST_LOCK" ;
VAL_ 1009 VCFRONT_indicatorRightRequest 1 "TURN_SIGNAL_ACTIVE_LOW" 0 "TURN_SIGNAL_OFF" 2 "TURN_SIGNAL_ACTIVE_HIGH" ;
VAL_ 1009 VCFRONT_indicatorLeftRequest 1 "TURN_SIGNAL_ACTIVE_LOW" 0 "TURN_SIGNAL_OFF" 2 "TURN_SIGNAL_ACTIVE_HIGH" ;
VAL_ 594 BMS_powerLimitsState 1 "POWER_CALCULATED_FOR_DRIVE" 0 "POWER_NOT_CALCULATED_FOR_DRIVE" ;
VAL_ 275 GTW_bmpState 3 "BMP_STATE_MIA" 5 "BMP_STATE_POWER_CYCLE" 2 "BMP_STATE_ASLEEP" 0 "BMP_STATE_OFF" 4 "BMP_STATE_RESET" 255 "DUMMY" 1 "BMP_STATE_ON" ;
VAL_ 2006 DIS_dynoSelector 33 "Mux33" 32 "Mux32" 0 "Mux0" 1 "Mux1" ;
VAL_ 789 DIS_inverterTQF 2 "INVERTERT_RATIONAL" 3 "INVERTERT_UNKNOWN" 0 "INVERTERT_INIT" 1 "INVERTERT_IRRATIONAL" ;
VAL_ 2033 GTW_hrlTriggerBus 2 "CH" 0 "VEH" 1 "PARTY" 4 "VIRT" 3 "ETH" ;
VAL_ 2033 GTW_hrlTriggerType 15 "HRL_TRIGGER_NONE" 0 "HRL_TRIGGER_UDPAPI" 1 "HRL_TRIGGER_EVENT" ;
VAL_ 2033 GTW_hrlState 1 "ENABLED" 0 "DISABLED" ;
VAL_ 2033 GTW_hrlIndex 2 "Mux2" 1 "Mux1" ;
VAL_ 541 CP_acChargeState 2 "AC_CHARGE_SHUTDOWN" 0 "AC_CHARGE_INACTIVE" 1 "AC_CHARGE_ACTIVE" ;
VAL_ 541 CP_gbdcFailureReason 2 "GBDC_SHUTDOWN_FAILURE" 1 "GBDC_ATTEMPTS_EXPIRED" 3 "GBDC_CRITICAL_FAILURE" 0 "GBDC_FAILURE_NONE" ;
VAL_ 541 CP_gbdcStopChargeReason 6 "GBDC_LIVE_DISCONNECT" 2 "GBDC_EVSE_REQUESTED" 0 "GBDC_STOP_REASON_NONE" 5 "GBDC_EVSE_CRITICAL_FAULT" 4 "GBDC_EVSE_FAULT" 3 "GBDC_COMMS_TIMEOUT" 1 "GBDC_VEH_REQUESTED" ;
VAL_ 541 CP_gbState 13 "GBDC_EVSE_ERROR" 6 "GBDC_READY_TO_CHARGE" 4 "GBDC_CHARGE_CONFIG" 1 "GBDC_WAIT_FOR_HANDSHAKE" 14 "GBDC_WAIT_FOR_ERROR_SHUTDOWN" 11 "GBDC_END_OF_CHARGE" 10 "GBDC_NORMAL_SHUTDOWN" 2 "GBDC_HANDSHAKING" 15 "GBDC_RESTART_CHARGE" 5 "GBDC_VEH_PACK_PRECHARGE" 8 "GBDC_CHARGING" 3 "GBDC_RECOGNITION" 7 "GBDC_CHARGING_START" 16 "GBDC_FAILURE" 12 "GBDC_EVSE_READY_TO_RESTART" 9 "GBDC_STOP_CHARGE" 0 "GBDC_IDLE" ;
VAL_ 541 CP_evseChargeType 1 "DC_CHARGER_PRESENT" 0 "NO_CHARGER_PRESENT" 2 "AC_CHARGER_PRESENT" ;
VAL_ 541 CP_teslaSwcanState 0 "TESLA_SWCAN_INACTIVE" 1 "TESLA_SWCAN_ACCEPT" 4 "TESLA_SWCAN_FAULT" 5 "TESLA_SWCAN_GO_TO_SLEEP" 3 "TESLA_SWCAN_ESTABLISHED" 2 "TESLA_SWCAN_RECEIVE" 6 "TESLA_SWCAN_OFFBOARD_UPDATE_IN_PROGRESS" ;
VAL_ 541 CP_cableType 3 "CHG_CABLE_TYPE_GB_DC" 2 "CHG_CABLE_TYPE_GB_AC" 0 "CHG_CABLE_TYPE_IEC" 1 "CHG_CABLE_TYPE_SAE" 4 "CHG_CABLE_TYPE_SNA" ;
VAL_ 541 CP_pilot 6 "CHG_PILOT_UNUSED_6" 3 "CHG_PILOT_FAST_CHARGE" 7 "CHG_PILOT_SNA" 4 "CHG_PILOT_IDLE" 2 "CHG_PILOT_LINE_CHARGE" 0 "CHG_PILOT_NONE" 5 "CHG_PILOT_INVALID" 1 "CHG_PILOT_FAULTED" ;
VAL_ 541 CP_proximity 3 "CHG_PROXIMITY_LATCHED" 0 "CHG_PROXIMITY_SNA" 2 "CHG_PROXIMITY_UNLATCHED" 1 "CHG_PROXIMITY_DISCONNECTED" ;
VAL_ 680 EPBL_brakeDiscWipeRequest 1 "EPB_BRAKEDISCWIPE_REQUEST_LIGHT" 3 "EPB_BRAKEDISCWIPE_REQUEST_SNA" 0 "EPB_BRAKEDISCWIPE_REQUEST_NONE" 2 "EPB_BRAKEDISCWIPE_REQUEST_STRONG" ;
VAL_ 680 EPBL_cdpRequest 0 "EPB_CDP_NOT_REQUESTED" 1 "EPB_CDP_REQUESTED" ;
VAL_ 680 EPBL_telltale 0 "EPB_TELLTALE_LAMP_OFF" 2 "EPB_TELLTALE_LAMP_AMBER_ON" 3 "EPB_TELLTALE_LAMP_RED_FLASH" 1 "EPB_TELLTALE_LAMP_RED_ON" 7 "EPB_TELLTALE_SNA" ;
VAL_ 680 EPBL_systemStatus 0 "EPB_VEHICLE_STATUS_UNKNOWN" 2 "EPB_VEHICLE_STATUS_PARKED" 6 "EPB_VEHICLE_STATUS_FAULT" 3 "EPB_VEHICLE_STATUS_DYNAMIC" 1 "EPB_VEHICLE_STATUS_RELEASED" 4 "EPB_VEHICLE_STATUS_PARKING" 5 "EPB_VEHICLE_STATUS_RELEASING" 8 "EPB_VEHICLE_STATUS_MISMATCH" 7 "EPB_VEHICLE_STATUS_FAULT_SECURE" ;
VAL_ 553 SCCM_parkButtonStatus 3 "SNA" 0 "NOT_PRESSED" 2 "INIT" 1 "PRESSED" ;
VAL_ 553 SCCM_rightStalkStatus 3 "DOWN_1" 6 "SNA" 0 "IDLE" 5 "INIT" 1 "UP_1" 4 "DOWN_2" 2 "UP_2" ;
VAL_ 819 UI_acChargeCurrentLimit 127 "SNA" ;
VAL_ 1898 HVP_ecuLogUploadRequest 3 "REQUEST_PRIORITY_3" 2 "REQUEST_PRIORITY_2" 0 "REQUEST_PRIORITY_NONE" 1 "REQUEST_PRIORITY_1" ;
VAL_ 1898 HVP_vehicleDebugMultiplexer 2 "Mux2" 0 "Mux0" 1 "Mux1" ;
VAL_ 761 VCSEC_bleDisconnectionReason 0 "UNKNOWN_REASON_0" 255 "UNKNOWN_REASON_FF" 34 "CONTROL_PACKET_TIMEOUT" 61 "MIC_FAILURE" 40 "CONTROL_PACKET_INSTANT_PASSED" 20 "REMOTE_DEVICE_LOW_RESOURCES" 22 "HOST_REQUESTED_TERMINATION" 5 "AUTHENTICATION_FAILURE" 26 "UNSUPPORTED_REMOTE_FEATURE" 19 "REMOTE_USER_TERMINATED" 59 "UNACCEPTABLE_CONNECTION_INTERVAL" 8 "CONNECTION_SUPERVISION_TIMEOUT" 21 "REMOTE_DEVICE_POWER_OFF" 41 "KEY_PAIRING_NOT_SUPPORTED" ;
VAL_ 918 DI_oilPumpCurrentSensorOffset 255 "SNA" ;
VAL_ 918 DI_oilPumpCurrent 255 "SNA" ;
VAL_ 918 DI_oilPumpVoltage 255 "SNA" ;
VAL_ 918 DI_oilPumpFluidT 255 "SNA" ;
VAL_ 918 DI_oilPumpPcbT 255 "SNA" ;
VAL_ 918 DI_oilPumpFlowActual 255 "SNA" ;
VAL_ 918 DI_oilPumpFlowTarget 255 "SNA" ;
VAL_ 918 DI_oilPumpState 2 "OIL_PUMP_COLD_STARTUP" 0 "OIL_PUMP_STANDBY" 1 "OIL_PUMP_ENABLE" 6 "OIL_PUMP_FAULTED" 7 "OIL_PUMP_SNA" ;
VAL_ 818 BMS_bmbMinMaxMultiplexer 1 "BMB_VOLT_MUX1" 2 "BMB_END" 0 "BMB_THERM_MUX0" ;
VAL_ 549 VCRIGHT_eFuseLockoutStatus 0 "EFUSE_LOCKOUT_STATUS_IDLE" 1 "EFUSE_LOCKOUT_STATUS_PENDING" 2 "EFUSE_LOCKOUT_STATUS_ACTIVE" ;
VAL_ 549 VCRIGHT_lumbarLVState 1 "LV_ON" 2 "LV_GOING_DOWN" 3 "LV_FAULT" 0 "LV_OFF" ;
VAL_ 549 VCRIGHT_rcmLVState 1 "LV_ON" 2 "LV_GOING_DOWN" 3 "LV_FAULT" 0 "LV_OFF" ;
VAL_ 549 VCRIGHT_hvcLVState 1 "LV_ON" 2 "LV_GOING_DOWN" 3 "LV_FAULT" 0 "LV_OFF" ;
VAL_ 549 VCRIGHT_tunerLVState 1 "LV_ON" 2 "LV_GOING_DOWN" 3 "LV_FAULT" 0 "LV_OFF" ;
VAL_ 549 VCRIGHT_rearOilPumpLVState 1 "LV_ON" 2 "LV_GOING_DOWN" 3 "LV_FAULT" 0 "LV_OFF" ;
VAL_ 549 VCRIGHT_amplifierLVState 1 "LV_ON" 2 "LV_GOING_DOWN" 3 "LV_FAULT" 0 "LV_OFF" ;
VAL_ 549 VCRIGHT_ocsLVState 1 "LV_ON" 2 "LV_GOING_DOWN" 3 "LV_FAULT" 0 "LV_OFF" ;
VAL_ 549 VCRIGHT_ptcLVState 1 "LV_ON" 2 "LV_GOING_DOWN" 3 "LV_FAULT" 0 "LV_OFF" ;
VAL_ 914 BMS_fcLinkTestDecayTime 1023 "SNA" ;
VAL_ 914 BMS_cpChargeStatus 4 "BMS_CHARGING_ENABLING" 1 "BMS_CHARGING_ACTIVE" 2 "BMS_CHARGING_COMPLETE" 5 "BMS_CHARGING_UPDATE_IN_PROGRESS" 0 "BMS_CHARGING_INACTIVE" 3 "BMS_CHARGING_FAULT" ;
VAL_ 914 BMS_soe 255 "SNA" ;
VAL_ 1317 PM_a013_errorType 3 "PM_CAN_ERR_TX_OVERRUN" 2 "PM_CAN_ERR_RX_OVERRUN" 4 "PM_CAN_ERR_IPC_RX_OVERRUN" 1 "PM_CAN_ERR_TX" 5 "PM_CAN_ERR_IPC_TX_OVERRUN" 0 "PM_CAN_ERR_RX" ;
VAL_ 1317 PM_a014_accelErrorType 0 "SNA" 3 "AccelTracksOutOfSync" 2 "Accel2RangeError" 1 "Accel1RangeError" ;
VAL_ 1317 PM_a056_errorType 3 "PM_CAN_ERR_TX_OVERRUN" 2 "PM_CAN_ERR_RX_OVERRUN" 4 "PM_CAN_ERR_IPC_RX_OVERRUN" 1 "PM_CAN_ERR_TX" 5 "PM_CAN_ERR_IPC_TX_OVERRUN" 0 "PM_CAN_ERR_RX" ;
VAL_ 1317 PM_a034_torqueType 2 "PEDAL_POSITION" 1 "TORQUE_COMMAND" 0 "TORQUE_ESTIMATE" ;
VAL_ 1317 PM_a046_vhldCancelReason 1 "PM_VHLD_CANCEL_PEDAL_OVERRIDE" 0 "PM_VHLD_CANCEL_NONE" ;
VAL_ 1317 PM_a030_aebCancelReason 0 "PM_AEB_CANCEL_NONE" 1 "PM_AEB_CANCEL_DAS" 2 "PM_AEB_CANCEL_EPB_FAULT" ;
VAL_ 1317 PM_a023_crsCancelReason 0 "PM_CRS_CANCEL_NONE" 3 "PM_CRS_CANCEL_GEAR" 7 "PM_CRS_CANCEL_EPB" 8 "PM_CRS_CANCEL_BRAKE" 5 "PM_CRS_CANCEL_TC" 9 "PM_CRS_CANCEL_STALK_CMD" 6 "PM_CRS_CANCEL_DAS" 4 "PM_CRS_CANCEL_ESP" 2 "PM_CRS_CANCEL_AEB_ACTIVE" 10 "PM_CRS_CANCEL_SKID" 1 "PM_CRS_CANCEL_OFF_BTN" ;
VAL_ 1317 PM_a057_errorType 4 "CAN_RECEIVE_ERROR_SEQUENCE" 5 "CAN_RECEIVE_ERROR_DATA_INVALID" 1 "CAN_RECEIVE_ERROR_LENGTH_SHORT" 2 "CAN_RECEIVE_ERROR_LENGTH_LONG" 6 "CAN_RECEIVE_ERROR_UNKNOWN_ID" 0 "CAN_RECEIVE_ERROR_NONE" 3 "CAN_RECEIVE_ERROR_CHECKSUM" ;
VAL_ 1317 PM_a012_errorType 4 "CAN_RECEIVE_ERROR_SEQUENCE" 5 "CAN_RECEIVE_ERROR_DATA_INVALID" 1 "CAN_RECEIVE_ERROR_LENGTH_SHORT" 2 "CAN_RECEIVE_ERROR_LENGTH_LONG" 6 "CAN_RECEIVE_ERROR_UNKNOWN_ID" 0 "CAN_RECEIVE_ERROR_NONE" 3 "CAN_RECEIVE_ERROR_CHECKSUM" ;
VAL_ 1317 PM_a046_vhldUnavailableReason 2 "PM_VHLD_UNAVAILABLE_EPB_FAULT" 9 "PM_VHLD_UNAVAILABLE_EBR" 8 "PM_VHLD_UNAVAILABLE_AEB_ACTIVE" 4 "PM_VHLD_UNAVAILABLE_SKID" 7 "PM_VHLD_UNAVAILABLE_CRUISE_ACTIVE" 6 "PM_VHLD_UNAVAILABLE_SPEED" 0 "PM_VHLD_UNAVAILABLE_NONE" 5 "PM_VHLD_UNAVAILABLE_GEAR" 3 "PM_VHLD_UNAVAILABLE_DI_FAULT" 1 "PM_VHLD_UNAVAILABLE_EPB" ;
VAL_ 1317 PM_a030_aebUnavailableReason 0 "PM_AEB_UNAVAILABLE_NONE" 1 "PM_AEB_UNAVAILBLE_EPB_PARK" 5 "PM_AEB_UNAVAILABLE_GEAR" 3 "PM_AEB_UNAVAILABLE_ESP_UNAVAILABLE" 2 "PM_AEB_UNAVAILABLE_DI_STATE" 6 "PM_AEB_UNAVAILABLE_NEGATIVE_SPEED" 7 "PM_AEB_UNAVAILABLE_EBR" 4 "PM_AEB_UNAVAILABLE_SKID" ;
VAL_ 1317 PM_a023_crsFaultReason 5 "PM_CRS_FAULT_EPB_MIA" 14 "PM_CRS_FAULT_TORQUE" 1 "PM_CRS_FAULT_EBR_FAULT" 13 "PM_CRS_FAULT_DI_MIA" 17 "PM_CRS_FAULT_APC_FAULT" 0 "PM_CRS_FAULT_NONE" 7 "PM_CRS_FAULT_CONFIG" 12 "PM_CRS_FAULT_JERK_RQ" 11 "PM_CRS_FAULT_ACCEL_RQ" 3 "PM_CRS_FAULT_ESP_MIA" 4 "PM_CRS_FAULT_SCCM_MIA" 18 "PM_CRS_FAULT_VDC_FAULT" 2 "PM_CRS_FAULT_ESP_FAULT" 16 "PM_CRS_FAULT_DECEL" 8 "PM_CRS_FAULT_DAS" 15 "PM_CRS_FAULT_ACCEL" 9 "PM_CRS_FAULT_EPB_FAULT" 10 "PM_CRS_FAULT_TC_FAULT" 6 "PM_CRS_FAULT_WHEEL_SPDS_INVAL" ;
VAL_ 1317 PM_a046_vhldFaultReason 4 "PM_VHLD_FAULT_ESP_MIA" 6 "PM_VHLD_FAULT_WHEEL_SPDS_INVAL" 1 "PM_VHLD_FAULT_EBR_FAULT" 7 "PM_VHLD_FAULT_REQUESTED" 0 "PM_VHLD_FAULT_NONE" 2 "PM_VHLD_FAULT_BRAKE_INVALID" 3 "PM_VHLD_FAULT_ESP_FAULT" 5 "PM_VHLD_FAULT_EPB_MIA" ;
VAL_ 1317 PM_a047_autoparkCancelReason 0 "PM_APC_CANCEL_NONE" 3 "PM_APC_CANCEL_SPEED_VIOLATION" 1 "PM_APC_CANCEL_BRAKE_APPLY" 2 "PM_APC_CRUISE_CANCEL_TIMEOUT" ;
VAL_ 1317 PM_a030_aebFaultReason 0 "PM_AEB_FAULT_NONE" 5 "PM_AEB_FAULT_ESP_FAULT" 6 "PM_AEB_FAULT_SPEED_DELTA" 2 "PM_AEB_FAULT_ESP_MIA" 1 "PM_AEB_FAULT_DAS_CONTROL_MIA" 3 "PM_AEB_FAULT_WHEEL_SPEEDS_INVALID" 4 "PM_AEB_FAULT_EBR_FAULT" ;
VAL_ 1317 PM_a030_dasAebEvent 2 "AEB_FAULT" 0 "AEB_NOT_ACTIVE" 3 "AEB_SNA" 1 "AEB_ACTIVE" ;
VAL_ 1317 PM_a064_torqueCmdState 8 "TorqueCmd_Invalid" 6 "TorqueCmd_Valid" 0 "TorqueCmd_SNA" ;
VAL_ 1317 PM_a047_diAutoparkState 6 "DI_APC_ABORTED" 8 "DI_APC_UNPARK_COMPLETE" 7 "DI_APC_RESUMED" 0 "DI_APC_UNAVAILABLE" 4 "DI_APC_COMPLETE" 5 "DI_APC_PAUSED" 9 "DI_APC_SELFPARK_STARTED" 1 "DI_APC_STANDBY" 3 "DI_APC_ACTIVE" 15 "DI_APC_SNA" 2 "DI_APC_STARTED" ;
VAL_ 1317 PM_a033_failReason 4 "SOPT_FAIL_TIMEDOUT" 2 "SOPT_FAIL_NEG_CURRENT" 1 "SOPT_FAIL_POS_CURRENT" 3 "SOPT_FAIL_DISAGREE" 5 "SOPT_FAIL_GATE_DRIVE_ERROR" 6 "SOPT_FAIL_FAULT_PRESENT" 0 "SOPT_FAIL_CACHED" 7 "SOPT_FAIL_ASC_TEST" ;
VAL_ 1317 PM_a030_pmAebState 2 "AEB_CAN_STATE_ENABLED" 1 "AEB_CAN_STATE_STANDBY" 3 "AEB_CAN_STATE_STANDSTILL" 0 "AEB_CAN_STATE_UNAVAILABLE" 4 "AEB_CAN_STATE_FAULT" 7 "AEB_CAN_STATE_SNA" ;
VAL_ 1317 PM_a046_pmVhldState 1 "DI_VHLD_STATE_STANDBY" 2 "DI_VHLD_STATE_BLEND_IN" 5 "DI_VHLD_STATE_PARK" 4 "DI_VHLD_STATE_BLEND_OUT" 3 "DI_VHLD_STATE_STANDSTILL" 7 "DI_VHLD_STATE_INIT" 0 "DI_VHLD_STATE_UNAVAILABLE" 6 "DI_VHLD_STATE_FAULT" ;
VAL_ 1317 PM_a042_expectedPerformanceCfg 1 "AWD" 0 "RWD" ;
VAL_ 1317 PM_a042_GTW_drivetrainType 1 "AWD" 0 "RWD" ;
VAL_ 1317 PM_a030_diAebState 2 "AEB_CAN_STATE_ENABLED" 1 "AEB_CAN_STATE_STANDBY" 3 "AEB_CAN_STATE_STANDSTILL" 0 "AEB_CAN_STATE_UNAVAILABLE" 4 "AEB_CAN_STATE_FAULT" 7 "AEB_CAN_STATE_SNA" ;
VAL_ 1317 PM_a064_interventionType 7 "TRQP_excessiveRegenTorque" 8 "TRQP_torqueInNeutral" 0 "TRQP_masterTorqueMonitorShutoff" 2 "TRQP_torqueCmdInvalid" 1 "TRQP_resolver" 3 "TRQP_cruiseFault" 10 "TRQP_switchOffPathTestFail" 5 "TRQP_accumulatedTorque" 9 "TRQP_inconsistentTorqueSign" 6 "TRQP_torqueReversal" 4 "TRQP_motorMovementDetected" ;
VAL_ 1317 PM_a047_pmAutoparkState 6 "DI_APC_ABORTED" 8 "DI_APC_UNPARK_COMPLETE" 7 "DI_APC_RESUMED" 0 "DI_APC_UNAVAILABLE" 4 "DI_APC_COMPLETE" 5 "DI_APC_PAUSED" 9 "DI_APC_SELFPARK_STARTED" 1 "DI_APC_STANDBY" 3 "DI_APC_ACTIVE" 15 "DI_APC_SNA" 2 "DI_APC_STARTED" ;
VAL_ 1317 PM_a046_diVhldState 1 "DI_VHLD_STATE_STANDBY" 2 "DI_VHLD_STATE_BLEND_IN" 5 "DI_VHLD_STATE_PARK" 4 "DI_VHLD_STATE_BLEND_OUT" 3 "DI_VHLD_STATE_STANDSTILL" 7 "DI_VHLD_STATE_INIT" 0 "DI_VHLD_STATE_UNAVAILABLE" 6 "DI_VHLD_STATE_FAULT" ;
VAL_ 1317 PM_a026_reason 0 "TooSlow" 1 "TooFast" ;
VAL_ 1317 PM_a033_state 1 "SOPT_STATE_PSTG_BRING_UP" 5 "SOPT_STATE_CURRENT_TEST_POS" 6 "SOPT_STATE_CURRENT_TEST_NEG" 2 "SOPT_STATE_ASC_TEST" 0 "SOPT_STATE_INIT" 10 "SOPT_STATE_TEST_FAILED" 3 "SOPT_STATE_ASC_TEST_PASSED" 4 "SOPT_STATE_PWM_ENABLE" 9 "SOPT_STATE_TEST_SKIPPED" 8 "SOPT_STATE_TEST_PASSED" 7 "SOPT_STATE_TEST_PRE_PASSED" 11 "SOPT_STATE_TEST_RESTART" ;
VAL_ 1317 PM_a048_vdcFaultReason 4 "PM_VDC_FAULT_EXCESSIVE_YAW_TORQUE" 1 "PM_VDC_FAULT_DECEL_INABILITY" 0 "PM_VDC_FAULT_NONE" 2 "PM_VDC_FAULT_DECEL_UNINTENDED" 5 "PM_VDC_FAULT_INVALID_GEAR" 6 "PM_VDC_FAULT_INVALID_REQUEST" 3 "PM_VDC_FAULT_REVERSAL_YAW_TORQUE" ;
VAL_ 1317 PM_alertType 0 "ALERT_CLEARED" 1 "ALERT_SET" ;
VAL_ 1317 PM_alertID 44 "PM_a044_ebrIntervention" 28 "PM_a028_torqueCmdError" 51 "PM_a051_unintDecelStbCtrl" 41 "PM_a041_dasMIA" 1 "PM_a001_absoluteTorque" 2 "PM_a002_accumulatedTorque" 55 "PM_a055_resolver" 16 "PM_a016_cruiseMIA" 14 "PM_a014_accelPedalError" 39 "PM_a039_disMIA" 18 "PM_a018_encoderIrrational" 45 "PM_a045_motorMovementDetected" 53 "PM_a053_vcfrontMIA" 42 "PM_a042_gtwMIA" 31 "PM_a031_highStackUsage" 0 "PM_ALERT_DO_NOT_USE_ZERO" 4 "PM_a004_regenTorque" 7 "PM_a007_watchdogReset" 50 "PM_a050_excessiveStbCtrlTrq" 48 "PM_a048_stabilityControlInhibit" 64 "PM_a064_torqueIntervention" 63 "PM_a063_debugAlert" 43 "PM_a043_inconsistentConfig" 32 "PM_a032_registerConfigError" 49 "PM_a049_stbCtrlInWrongDir" 13 "PM_a013_canHardwareBusA" 30 "PM_a030_inconsistentAebState" 6 "PM_a006_inconsistentDIGear" 47 "PM_a047_inconsAutoparkState" 23 "PM_a023_crsCmdOffStateOn" 57 "PM_a057_canDataBusB" 54 "PM_a054_uiMIA" 34 "PM_a034_trqCrossCheck" 24 "PM_a024_brakeIrrational" 3 "PM_a003_torqueReversal" 15 "PM_a015_shifterMIA" 58 "PM_a058_cmpMIA" 27 "PM_a027_torqueOutOfMap" 59 "PM_a059_ptcMIA" 8 "PM_a008_memoryError" 61 "PM_a061_DIPMVersionMismatch" 10 "PM_a010_diMIA" 52 "PM_a052_stbCtrlDrvrDecelCflct" 17 "PM_a017_brakeMIA" 26 "PM_a026_diHeartBeatMIA" 40 "PM_a040_pmMIA" 46 "PM_a046_inconsVehicleHoldState" 5 "PM_a005_torqueInNeutral" 11 "PM_a011_phaseCurrentIrrational" 56 "PM_a056_canHardwareBusB" 38 "PM_a038_inconsistentTorqueSign" 12 "PM_a012_canDataBusA" 9 "PM_a009_espMIA" 33 "PM_a033_selfTest" 19 "PM_a019_statorTempIrrational" ;
VAL_ 1318 DI_a199_vdcMode 2 "VDC_MODE_TRACK" 0 "VDC_MODE_OFF" 1 "VDC_MODE_ON" ;
VAL_ 1318 DI_a199_understeerdMzActive 0 "VDC_REGULATOR_NOT_ACTIVE" 1 "VDC_REGULATOR_ACTIVE" ;
VAL_ 1318 DI_a066_errorType 4 "CAN_RECEIVE_ERROR_SEQUENCE" 5 "CAN_RECEIVE_ERROR_DATA_INVALID" 1 "CAN_RECEIVE_ERROR_LENGTH_SHORT" 2 "CAN_RECEIVE_ERROR_LENGTH_LONG" 6 "CAN_RECEIVE_ERROR_UNKNOWN_ID" 0 "CAN_RECEIVE_ERROR_NONE" 3 "CAN_RECEIVE_ERROR_CHECKSUM" ;
VAL_ 1318 DI_a199_decelControlActive 0 "VDC_REGULATOR_NOT_ACTIVE" 1 "VDC_REGULATOR_ACTIVE" ;
VAL_ 1318 DI_a199_oversteerdMzActive 0 "VDC_REGULATOR_NOT_ACTIVE" 1 "VDC_REGULATOR_ACTIVE" ;
VAL_ 1318 DI_a199_preControlActive 0 "VDC_REGULATOR_NOT_ACTIVE" 1 "VDC_REGULATOR_ACTIVE" ;
VAL_ 1318 DI_a159_ESP_ebrStatus 1 "EBR_IS_AVAILABLE" 0 "EBR_IS_NOT_AVAILABLE" 3 "EBR_COMMAND_INVALID" 2 "ACTUATING_DI_EBR" ;
VAL_ 1318 DI_a223_regenTCActive 0 "INACTIVE" 1 "ACTIVE" ;
VAL_ 1318 DI_a223_driveTCActive 0 "INACTIVE" 1 "ACTIVE" ;
VAL_ 1318 DI_a038_reason 0 "UNDERVOLTAGE_PRE_CHARGE" 2 "DI_BMS_VOLTAGE_MISMATCH" 1 "UNDERVOLTAGE_HV_UP" ;
VAL_ 1318 DI_a162_requestedGear 1 "DI_GEAR_P" 0 "DI_GEAR_INVALID" 7 "DI_GEAR_SNA" 2 "DI_GEAR_R" 3 "DI_GEAR_N" 4 "DI_GEAR_D" ;
VAL_ 1318 DI_a115_sensors 1 "PHASEDIFF_12" 0 "PHASEDIFF_IRR" 3 "PHASEDIFF_23" 2 "PHASEDIFF_13" ;
VAL_ 1318 DI_a066_canID 659 "UI_chassisControl" 530 "BMS_status" 962 "VCLEFT_switchStatus" 577 "VCFRONT_coolant" 1925 "DBG_dynoOpenLoop" 1926 "DBG_dynoVehicleSim" 1862 "DBG_dynoControl" 340 "PM_state" 768 "BMS_info" 306 "BMS_hvBusStatus" 605 "CP_status" 259 "VCRIGHT_doorStatus" 548 "PCS_dcdcStatus" 2015 "UDS_functionalRequest" 583 "CMP_HVStatus" 801 "VCFRONT_sensors" 872 "GTW_updateStatus" 741 "DIS_power" 722 "BMS_driveLimits" 2047 "GTW_carConfig" 929 "VCFRONT_vehicleStatus" 737 "VCFRONT_status" 1798 "DBG_xcpDICommand" 531 "UI_cruiseControl" 1863 "DBG_DI_vdcControl" 804 "PM_crossCheck" 519 "PTC_feedbackStatus" 985 "VCSEC_authenticityResponse" 594 "BMS_powerAvailable" 680 "EPBL_status" 553 "SCCM_rightStalk" 644 "UI_vehicleModes" 258 "VCLEFT_doorStatus" 787 "UI_powertrainControl" 1320 "GTW_time" 744 "EPBR_status" 1280 "UI_debugECU" 1542 "UDS_diRequest" 545 "VCFRONT_LVPowerState" ;
VAL_ 1318 DI_a162_currentGear 1 "DI_GEAR_P" 0 "DI_GEAR_INVALID" 7 "DI_GEAR_SNA" 2 "DI_GEAR_R" 3 "DI_GEAR_N" 4 "DI_GEAR_D" ;
VAL_ 1318 DI_a093_errorType 0 "DI_CAN_HARDWARE_RECEIVE_ERROR" 1 "DI_CAN_HARDWARE_TRANSMIT_ERROR" ;
VAL_ 1318 DI_a232_steerAngleValid 0 "INVALID" 1 "VALID" ;
VAL_ 1318 DI_a232_yawRateValid 0 "INVALID" 1 "VALID" ;
VAL_ 1318 DI_a232_longitudinalAccelValid 0 "INVALID" 1 "VALID" ;
VAL_ 1318 DI_a055_torqueType 2 "PEDAL_POSITION" 1 "TORQUE_COMMAND" 0 "TORQUE_ESTIMATE" ;
VAL_ 1318 DI_a232_lateralAccelValid 0 "INVALID" 1 "VALID" ;
VAL_ 1318 DI_a232_DIS_torqueMotorValid 0 "INVALID" 1 "VALID" ;
VAL_ 1318 DI_a041_reason 1 "STUCK" 0 "CRUISECANCEL" ;
VAL_ 1318 DI_a232_OversteerActiveValid 0 "INVALID" 1 "VALID" ;
VAL_ 1318 DI_a232_UndersteerActiveValid 0 "INVALID" 1 "VALID" ;
VAL_ 1318 DI_a232_AbsBrakeEventActiveValid 0 "INVALID" 1 "VALID" ;
VAL_ 1318 DI_a193_brakeTorqueFrR 2 "VDC_SIGNAL_FREEZE" 6 "VDC_SIGNAL_QF_VALIDITY" 3 "VDC_SIGNAL_RATE" 4 "VDC_SIGNAL_QF" 0 "VDC_SIGNAL_VALID" 7 "VDC_SIGNAL_TEMP_QF_INVALID" 1 "VDC_SIGNAL_RANGE" 5 "VDC_SIGNAL_CAN" ;
VAL_ 1318 DI_a207_driverTorqueFr 2 "VDC_SIGNAL_FREEZE" 6 "VDC_SIGNAL_QF_VALIDITY" 3 "VDC_SIGNAL_RATE" 4 "VDC_SIGNAL_QF" 0 "VDC_SIGNAL_VALID" 7 "VDC_SIGNAL_TEMP_QF_INVALID" 1 "VDC_SIGNAL_RANGE" 5 "VDC_SIGNAL_CAN" ;
VAL_ 1318 DI_a215_wheelSpeedNonCGReR 2 "VDC_SIGNAL_FREEZE" 6 "VDC_SIGNAL_QF_VALIDITY" 3 "VDC_SIGNAL_RATE" 4 "VDC_SIGNAL_QF" 0 "VDC_SIGNAL_VALID" 7 "VDC_SIGNAL_TEMP_QF_INVALID" 1 "VDC_SIGNAL_RANGE" 5 "VDC_SIGNAL_CAN" ;
VAL_ 1318 DI_a172_currentGear 1 "DI_GEAR_P" 0 "DI_GEAR_INVALID" 7 "DI_GEAR_SNA" 2 "DI_GEAR_R" 3 "DI_GEAR_N" 4 "DI_GEAR_D" ;
VAL_ 1318 DI_a211_motorSpeedRe 2 "VDC_SIGNAL_FREEZE" 6 "VDC_SIGNAL_QF_VALIDITY" 3 "VDC_SIGNAL_RATE" 4 "VDC_SIGNAL_QF" 0 "VDC_SIGNAL_VALID" 7 "VDC_SIGNAL_TEMP_QF_INVALID" 1 "VDC_SIGNAL_RANGE" 5 "VDC_SIGNAL_CAN" ;
VAL_ 1318 DI_a206_yawRate 2 "VDC_SIGNAL_FREEZE" 6 "VDC_SIGNAL_QF_VALIDITY" 3 "VDC_SIGNAL_RATE" 4 "VDC_SIGNAL_QF" 0 "VDC_SIGNAL_VALID" 7 "VDC_SIGNAL_TEMP_QF_INVALID" 1 "VDC_SIGNAL_RANGE" 5 "VDC_SIGNAL_CAN" ;
VAL_ 1318 DI_a194_brakeTorqueReR 2 "VDC_SIGNAL_FREEZE" 6 "VDC_SIGNAL_QF_VALIDITY" 3 "VDC_SIGNAL_RATE" 4 "VDC_SIGNAL_QF" 0 "VDC_SIGNAL_VALID" 7 "VDC_SIGNAL_TEMP_QF_INVALID" 1 "VDC_SIGNAL_RANGE" 5 "VDC_SIGNAL_CAN" ;
VAL_ 1318 DI_a149_state 2 "OIL_PUMP_COLD_STARTUP" 0 "OIL_PUMP_STANDBY" 1 "OIL_PUMP_ENABLE" 6 "OIL_PUMP_FAULTED" 7 "OIL_PUMP_SNA" ;
VAL_ 1318 DI_a213_wheelSpeedCGReR 2 "VDC_SIGNAL_FREEZE" 6 "VDC_SIGNAL_QF_VALIDITY" 3 "VDC_SIGNAL_RATE" 4 "VDC_SIGNAL_QF" 0 "VDC_SIGNAL_VALID" 7 "VDC_SIGNAL_TEMP_QF_INVALID" 1 "VDC_SIGNAL_RANGE" 5 "VDC_SIGNAL_CAN" ;
VAL_ 1318 DI_a232_WheelBrakeTorquesValid 0 "INVALID" 1 "VALID" ;
VAL_ 1318 DI_a212_wheelSpeedCGFrR 2 "VDC_SIGNAL_FREEZE" 6 "VDC_SIGNAL_QF_VALIDITY" 3 "VDC_SIGNAL_RATE" 4 "VDC_SIGNAL_QF" 0 "VDC_SIGNAL_VALID" 7 "VDC_SIGNAL_TEMP_QF_INVALID" 1 "VDC_SIGNAL_RANGE" 5 "VDC_SIGNAL_CAN" ;
VAL_ 1318 DI_a198_steeringAngle 2 "VDC_SIGNAL_FREEZE" 6 "VDC_SIGNAL_QF_VALIDITY" 3 "VDC_SIGNAL_RATE" 4 "VDC_SIGNAL_QF" 0 "VDC_SIGNAL_VALID" 7 "VDC_SIGNAL_TEMP_QF_INVALID" 1 "VDC_SIGNAL_RANGE" 5 "VDC_SIGNAL_CAN" ;
VAL_ 1318 DI_a204_rollRate 2 "VDC_SIGNAL_FREEZE" 6 "VDC_SIGNAL_QF_VALIDITY" 3 "VDC_SIGNAL_RATE" 4 "VDC_SIGNAL_QF" 0 "VDC_SIGNAL_VALID" 7 "VDC_SIGNAL_TEMP_QF_INVALID" 1 "VDC_SIGNAL_RANGE" 5 "VDC_SIGNAL_CAN" ;
VAL_ 1318 DI_a195_wheelSlipFrR 2 "VDC_SIGNAL_FREEZE" 6 "VDC_SIGNAL_QF_VALIDITY" 3 "VDC_SIGNAL_RATE" 4 "VDC_SIGNAL_QF" 0 "VDC_SIGNAL_VALID" 7 "VDC_SIGNAL_TEMP_QF_INVALID" 1 "VDC_SIGNAL_RANGE" 5 "VDC_SIGNAL_CAN" ;
VAL_ 1318 DI_a196_wheelSlipReR 2 "VDC_SIGNAL_FREEZE" 6 "VDC_SIGNAL_QF_VALIDITY" 3 "VDC_SIGNAL_RATE" 4 "VDC_SIGNAL_QF" 0 "VDC_SIGNAL_VALID" 7 "VDC_SIGNAL_TEMP_QF_INVALID" 1 "VDC_SIGNAL_RANGE" 5 "VDC_SIGNAL_CAN" ;
VAL_ 1318 DI_a214_wheelSpeedNonCGFrR 2 "VDC_SIGNAL_FREEZE" 6 "VDC_SIGNAL_QF_VALIDITY" 3 "VDC_SIGNAL_RATE" 4 "VDC_SIGNAL_QF" 0 "VDC_SIGNAL_VALID" 7 "VDC_SIGNAL_TEMP_QF_INVALID" 1 "VDC_SIGNAL_RANGE" 5 "VDC_SIGNAL_CAN" ;
VAL_ 1318 DI_a208_driverTorqueRe 2 "VDC_SIGNAL_FREEZE" 6 "VDC_SIGNAL_QF_VALIDITY" 3 "VDC_SIGNAL_RATE" 4 "VDC_SIGNAL_QF" 0 "VDC_SIGNAL_VALID" 7 "VDC_SIGNAL_TEMP_QF_INVALID" 1 "VDC_SIGNAL_RANGE" 5 "VDC_SIGNAL_CAN" ;
VAL_ 1318 DI_a205_pitchRate 2 "VDC_SIGNAL_FREEZE" 6 "VDC_SIGNAL_QF_VALIDITY" 3 "VDC_SIGNAL_RATE" 4 "VDC_SIGNAL_QF" 0 "VDC_SIGNAL_VALID" 7 "VDC_SIGNAL_TEMP_QF_INVALID" 1 "VDC_SIGNAL_RANGE" 5 "VDC_SIGNAL_CAN" ;
VAL_ 1318 DI_a232_BrakeMasterCylPressValid 0 "INVALID" 1 "VALID" ;
VAL_ 1318 DI_a153_state 2 "OIL_PUMP_COLD_STARTUP" 0 "OIL_PUMP_STANDBY" 1 "OIL_PUMP_ENABLE" 6 "OIL_PUMP_FAULTED" 7 "OIL_PUMP_SNA" ;
VAL_ 1318 DI_a232_allWhlSpeedRotationAvail 0 "UNAVAILABLE" 1 "AVAILABLE" ;
VAL_ 1318 DI_a191_requestedGear 1 "DI_GEAR_P" 0 "DI_GEAR_INVALID" 7 "DI_GEAR_SNA" 2 "DI_GEAR_R" 3 "DI_GEAR_N" 4 "DI_GEAR_D" ;
VAL_ 1318 DI_a223_UI_tractionControlMode 4 "TC_ROLLS_MODE_SELECTED" 1 "TC_SLIP_START_SELECTED" 0 "TC_NORMAL_SELECTED" 3 "TC_DEV_MODE_2_SELECTED" 2 "TC_DEV_MODE_1_SELECTED" 5 "TC_DYNO_MODE_SELECTED" ;
VAL_ 1318 DI_a156_safeStateRecommend 0 "PSTG_SAFESTATE_NONE" 3 "PSTG_SAFESTATE_3PS_LOW" 2 "PSTG_SAFESTATE_3PS_HIGH" 1 "PSTG_SAFESTATE_ALL_OFF" ;
VAL_ 1318 DI_a191_currentGear 1 "DI_GEAR_P" 0 "DI_GEAR_INVALID" 7 "DI_GEAR_SNA" 2 "DI_GEAR_R" 3 "DI_GEAR_N" 4 "DI_GEAR_D" ;
VAL_ 1318 DI_a156_result 2 "PSTG_OBS_RESULT_SPEED_LOW" 0 "PSTG_OBS_RESULT_SUCCESS" 1 "PSTG_OBS_RESULT_SENSOR_BAD" ;
VAL_ 1318 DI_a184_crsNotAvailableReason 17 "DI_CRUISE_NOT_AVAILABLE_WAIT_INIT" 12 "DI_CRUISE_NOT_AVAILABLE_DI_STATE" 8 "DI_CRUISE_NOT_AVAILABLE_SEAT_BELT_UNBUCKLED" 13 "DI_CRUISE_NOT_AVAILABLE_CONFIG" 16 "DI_CRUISE_NOT_AVAILABLE_VEL_EST" 7 "DI_CRUISE_NOT_AVAILABLE_CLOSURE_OPEN" 0 "DI_CRUISE_NOT_AVAILABLE_NONE" 15 "DI_CRUISE_NOT_AVAILABLE_MIN_SPEED" 4 "DI_CRUISE_NOT_AVAILABLE_TC_ACTIVE" 5 "DI_CRUISE_NOT_AVAILABLE_ABS_ACTIVE" 2 "DI_CRUISE_NOT_AVAILABLE_VDC_OR_TC_OFF" 18 "DI_CRUISE_NOT_AVAILABLE_UI_MIA" 14 "DI_CRUISE_NOT_AVAILABLE_AEB" 9 "DI_CRUISE_NOT_AVAILABLE_VALET_MODE" 19 "DI_CRUISE_NOT_AVAILABLE_DAS_SNA" 10 "DI_CRUISE_NOT_AVAILABLE_EBR" 20 "DI_CRUISE_NOT_AVAILABLE_TRACK_MODE_ACTIVE" 6 "DI_CRUISE_NOT_AVAILABLE_ACC_CANCEL" 1 "DI_CRUISE_NOT_AVAILABLE_NO_ALERT" 3 "DI_CRUISE_NOT_AVAILABLE_VDC_ACTIVE_OR_DEGRADED" 11 "DI_CRUISE_NOT_AVAILABLE_MOTOR_SPEED" ;
VAL_ 1318 DI_a108_blockingAlert 195 "DI_a195_vdcEspSlipFr" 31 "DI_a031_phaseAcurrentOffset" 185 "DI_a185_autoparkAborted" 60 "DI_a060_heatsinkUT" 147 "DI_a147_highTorqueWearLimit" 160 "DI_a160_busVoltageAnomaly" 146 "DI_a146_pbrkPanicEpbFault" 9 "DI_a009_hwEncoderB" 5 "DI_a005_hwPhaseBpeak" 171 "DI_a171_driveRailNotRequested" 191 "DI_a191_brakeShiftReq" 241 "DI_a241_systemThermallyLimited" 30 "DI_a030_phaseCrms" 233 "DI_a233_diMsgMissed" 1 "DI_a001_hwPhaseAgateDrive" 208 "DI_a208_vdcPowertrainTorqueRe" 145 "DI_a145_pbrkPanicSkid" 220 "DI_a220_vdcUndersteerDecelActive" 199 "DI_a199_vdcFaulted" 167 "DI_a167_keyNotAuthenticated" 228 "DI_a228_brakeTempEstUnavailable" 172 "DI_a172_accelPressedInNP" 100 "DI_a100_assertion" 3 "DI_a003_hwPhaseCgateDrive" 71 "DI_a071_busDisconnected" 215 "DI_a215_velEstWheelSpeedNonCGRe" 18 "DI_a018_hw12vSupplyUV" 91 "DI_a091_espMIA" 134 "DI_a134_wheelSpeedIrrational" 12 "DI_a012_accel5VSupply" 54 "DI_a054_driveInverterOT" 222 "DI_a222_vdcDisabled" 217 "DI_a217_vdcOutputIrrational" 124 "DI_a124_cruiseFault" 240 "DI_a240_torqueSplitStuck" 51 "DI_a051_batteryOvercurrent" 61 "DI_a061_heatsinkSensor" 96 "DI_a096_memoryError" 87 "DI_a087_gtwMIA" 154 "DI_a154_resolver" 85 "DI_a085_proximityInEnable" 142 "DI_a142_highLashAngle" 180 "DI_a180_crsSeatbeltUnbuckled" 35 "DI_a035_phaseCurrentBalance" 227 "DI_a227_contactorsNotClosed" 26 "DI_a026_phaseBpeak" 131 "DI_a131_highSpeedWearLimit" 109 "DI_a109_cruiseMIA" 229 "DI_a229_batteryIsHeating" 104 "DI_a104_proximityIrrational" 163 "DI_a163_unparkReq" 244 "DI_a244_mechanical3PS" 90 "DI_a090_pmMIA" 17 "DI_a017_hwPedalMonitor" 88 "DI_a088_uiMIA" 98 "DI_a098_intTimeTooLong" 205 "DI_a205_vdcRcmLateral" 11 "DI_a011_swPowerStageNotReady" 14 "DI_a014_activeDamping" 21 "DI_a021_hwBusOV" 183 "DI_a183_holdReleaseRqrd" 202 "DI_a202_excessHeatUnavailable" 224 "DI_a224_brakeOverTemp" 74 "DI_a074_motorEncoder" 22 "DI_a022_hw5vSupplyUV" 115 "DI_a115_heatsinkTempImbalance" 103 "DI_a103_lowFlow" 235 "DI_a235_trackModeActive" 108 "DI_a108_stateTrans" 186 "DI_a186_brakeStand" 181 "DI_a181_rearMotorMode" 159 "DI_a159_cruiseSelfCheck" 200 "DI_a200_vdcModelBasedPlausibility" 197 "DI_a197_vdcEspWheelSaturations" 201 "DI_a201_regenLimited" 82 "DI_a082_accelTrack2" 187 "DI_a187_pedalMisapplication" 64 "DI_a064_torqueIntervention" 193 "DI_a193_vdcEspBrakeTorqueFr" 43 "DI_a043_outletOT" 123 "DI_a123_lossMotorControl" 40 "DI_a040_disMIA" 65 "DI_a065_canHardwareBusB" 81 "DI_a081_accelTrack1" 79 "DI_a079_adcRefHigh" 0 "DI_ALERT_DO_NOT_USE_ZERO" 80 "DI_a080_accelSynch" 207 "DI_a207_vdcPowertrainTorqueFr" 225 "DI_a225_tmpEstPlausibility" 182 "DI_a182_frontMotorMode" 232 "DI_a232_velocityEstimatorDegraded" 29 "DI_a029_phaseBrms" 162 "DI_a162_shiftDenied" 170 "DI_a170_pedalFoul" 110 "DI_a110_brakeMIA" 218 "DI_a218_vdcOSPreControlActive" 66 "DI_a066_canDataBusB" 165 "DI_a165_cruiseCancelled" 44 "DI_a044_outletUT" 157 "DI_a157_rcmMIA" 213 "DI_a213_velEstWheelSpeedCGRe" 133 "DI_a133_capacitorOT" 105 "DI_a105_cpMIA" 221 "DI_a221_vdcUndersteerdMzActive" 135 "DI_a135_vehicleHoldFault" 231 "DI_a231_ptcMIA" 230 "DI_a230_cmpMIA" 20 "DI_a020_hwMotorEncoder" 158 "DI_a158_ibstMIA" 175 "DI_a175_crsNotAvailable" 50 "DI_a050_noStatorSensor" 112 "DI_a112_noPhaseCurrent" 173 "DI_a173_bothPedalsPressed" 7 "DI_a007_hwHvilNotPresent" 125 "DI_a125_noBatteryPower" 129 "DI_a129_epbNotApplied" 152 "DI_a152_linError" 184 "DI_a184_autoparkCanceled" 137 "DI_a137_noCapableDriveUnits" 63 "DI_a063_systemGracefulPowerOff" 226 "DI_a226_sysStartConditionNotMet" 138 "DI_a138_frontUnitDisabled" 177 "DI_a177_tireFitmentChanged" 28 "DI_a028_phaseArms" 198 "DI_a198_vdcEspMCPressAndSteering" 59 "DI_a059_heatsinkOT" 56 "DI_a056_ambientOT" 32 "DI_a032_phaseBcurrentOffset" 164 "DI_a164_brakeOverride" 39 "DI_a039_noRegen" 234 "DI_a234_pcsMIA" 176 "DI_a176_EBRreleased" 72 "DI_a072_gateDriveFaultCounter" 73 "DI_a073_motorSpeed" 203 "DI_a203_TCReducedByADD" 196 "DI_a196_vdcEspSlipRe" 155 "DI_a155_vcfrontMIA" 36 "DI_a036_busOV" 212 "DI_a212_velEstWheelSpeedCGFr" 47 "DI_a047_statorSensor1" 86 "DI_a086_hvilNotPresent" 57 "DI_a057_ambientUT" 37 "DI_a037_busUV" 156 "DI_a156_currentObserver" 243 "DI_a243_ecuLogAvailable" 194 "DI_a194_vdcEspBrakeTorqueRe" 58 "DI_a058_ambientSensor" 206 "DI_a206_vdcRcmVertical" 151 "DI_a151_shockTorqueLimiter" 2 "DI_a002_hwPhaseBgateDrive" 83 "DI_a083_brakePedalSensor" 210 "DI_a210_vdcOtherControllerStates" 169 "DI_a169_regenOffOverride" 97 "DI_a097_eepromError" 136 "DI_a136_spiError" 25 "DI_a025_phaseApeak" 46 "DI_a046_statorOT" 76 "DI_a076_12vSupplyOV" 130 "DI_a130_aebFault" 149 "DI_a149_oilPumpFailure" 41 "DI_a041_driverBrakeApplyCheck" 126 "DI_a126_limpMode" 27 "DI_a027_phaseCpeak" 15 "DI_a015_immobilizer" 214 "DI_a214_velEstWheelSpeedNonCGFr" 189 "DI_a189_garageShiftWithPedal" 127 "DI_a127_gracefulPowerOff" 99 "DI_a099_threadOverrun" 114 "DI_a114_noMotorSpeed" 139 "DI_a139_rearUnitDisabled" 33 "DI_a033_phaseAcurrentSensor" 242 "DI_a242_rotorOffsetLearning" 116 "DI_a116_powerConvIrrational" 45 "DI_a045_outletSensor" 16 "DI_a016_safeStateApplied" 143 "DI_a143_mcuLimitActive" 78 "DI_a078_adcRefLow" 223 "DI_a223_tractionControlDisabled" 211 "DI_a211_vdcMotorSpeeds" 94 "DI_a094_canDataBusA" 67 "DI_a067_canOverrunBusB" 24 "DI_a024_selfTest" 148 "DI_a148_overtorqueUsed" 19 "DI_a019_hwAccelPedalPower" 166 "DI_a166_driverLeft" 192 "DI_a192_invalidOdometer" 174 "DI_a174_notOkToStartDrive" 122 "DI_a122_highStackUsage" 204 "DI_a204_vdcRcmLongitudinal" 161 "DI_a161_epas3pMIA" 219 "DI_a219_vdcOversteerdMzActive" 55 "DI_a055_trqCrossCheck" 144 "DI_a144_configMismatch" 117 "DI_a117_diMIA" 38 "DI_a038_busVsensor" 141 "DI_a141_dasMIA" 70 "DI_a070_12vSupplySensor" 95 "DI_a095_canOverrunBusA" 42 "DI_a042_inletSensor" 150 "DI_a150_busVD" 92 "DI_a092_bmsMIA" 121 "DI_a121_motorControlRegulation" 239 "DI_a239_neutralRequestByPM" 8 "DI_a008_hwEncoderA" 4 "DI_a004_hwPhaseApeak" 89 "DI_a089_sccmMIA" 6 "DI_a006_hwPhaseCpeak" 106 "DI_a106_absMIA" 75 "DI_a075_motorSpeedMismatch" 62 "DI_a062_systemLimpMode" 93 "DI_a093_canHardwareBusA" 168 "DI_a168_proximityDriveDenial" 77 "DI_a077_12vSupplyUV" 34 "DI_a034_phaseBcurrentSensor" 209 "DI_a209_vdcVehicleSpeed" 153 "DI_a153_oilPump" 216 "DI_a216_vdcMBPAlmostTripped" 23 "DI_a023_carNotParked" 113 "DI_a113_noFuncHeatsinkSensor" ;
VAL_ 1318 DI_a185_crsNotAvailableReason 17 "DI_CRUISE_NOT_AVAILABLE_WAIT_INIT" 12 "DI_CRUISE_NOT_AVAILABLE_DI_STATE" 8 "DI_CRUISE_NOT_AVAILABLE_SEAT_BELT_UNBUCKLED" 13 "DI_CRUISE_NOT_AVAILABLE_CONFIG" 16 "DI_CRUISE_NOT_AVAILABLE_VEL_EST" 7 "DI_CRUISE_NOT_AVAILABLE_CLOSURE_OPEN" 0 "DI_CRUISE_NOT_AVAILABLE_NONE" 15 "DI_CRUISE_NOT_AVAILABLE_MIN_SPEED" 4 "DI_CRUISE_NOT_AVAILABLE_TC_ACTIVE" 5 "DI_CRUISE_NOT_AVAILABLE_ABS_ACTIVE" 2 "DI_CRUISE_NOT_AVAILABLE_VDC_OR_TC_OFF" 18 "DI_CRUISE_NOT_AVAILABLE_UI_MIA" 14 "DI_CRUISE_NOT_AVAILABLE_AEB" 9 "DI_CRUISE_NOT_AVAILABLE_VALET_MODE" 19 "DI_CRUISE_NOT_AVAILABLE_DAS_SNA" 10 "DI_CRUISE_NOT_AVAILABLE_EBR" 20 "DI_CRUISE_NOT_AVAILABLE_TRACK_MODE_ACTIVE" 6 "DI_CRUISE_NOT_AVAILABLE_ACC_CANCEL" 1 "DI_CRUISE_NOT_AVAILABLE_NO_ALERT" 3 "DI_CRUISE_NOT_AVAILABLE_VDC_ACTIVE_OR_DEGRADED" 11 "DI_CRUISE_NOT_AVAILABLE_MOTOR_SPEED" ;
VAL_ 1318 DI_a065_errorType 0 "DI_CAN_HARDWARE_RECEIVE_ERROR" 1 "DI_CAN_HARDWARE_TRANSMIT_ERROR" ;
VAL_ 1318 DI_a095_canID 659 "UI_chassisControl" 530 "BMS_status" 962 "VCLEFT_switchStatus" 577 "VCFRONT_coolant" 1925 "DBG_dynoOpenLoop" 1926 "DBG_dynoVehicleSim" 1862 "DBG_dynoControl" 340 "PM_state" 768 "BMS_info" 306 "BMS_hvBusStatus" 605 "CP_status" 259 "VCRIGHT_doorStatus" 548 "PCS_dcdcStatus" 2015 "UDS_functionalRequest" 583 "CMP_HVStatus" 801 "VCFRONT_sensors" 872 "GTW_updateStatus" 741 "DIS_power" 722 "BMS_driveLimits" 2047 "GTW_carConfig" 929 "VCFRONT_vehicleStatus" 737 "VCFRONT_status" 1798 "DBG_xcpDICommand" 531 "UI_cruiseControl" 1863 "DBG_DI_vdcControl" 804 "PM_crossCheck" 519 "PTC_feedbackStatus" 985 "VCSEC_authenticityResponse" 594 "BMS_powerAvailable" 680 "EPBL_status" 553 "SCCM_rightStalk" 644 "UI_vehicleModes" 258 "VCLEFT_doorStatus" 787 "UI_powertrainControl" 1320 "GTW_time" 744 "EPBR_status" 1280 "UI_debugECU" 1542 "UDS_diRequest" 545 "VCFRONT_LVPowerState" ;
VAL_ 1318 DI_a223_DI_tractionControlMode 0 "TC_NORMAL" 1 "TC_SLIP_START" 4 "TC_ROLLS_MODE" 2 "TC_DEV_MODE_1" 5 "TC_DYNO_MODE" 3 "TC_DEV_MODE_2" ;
VAL_ 1318 DI_a124_cruiseFaultReason 6 "DI_CRUISE_FAULT_CRUISE_MIA" 5 "DI_CRUISE_FAULT_BRAKE_INVALID" 15 "DI_CRUISE_FAULT_ACCEL_OUT_OF_BOUNDS" 4 "DI_CRUISE_FAULT_STALK" 21 "DI_CRUISE_FAULT_CONFIG_MISMATCH" 3 "DI_CRUISE_FAULT_PM_REQUEST" 14 "DI_CRUISE_FAULT_EBR_FAULT" 17 "DI_CRUISE_FAULT_DAS_SNA" 13 "DI_CRUISE_FAULT_TC_FAULT" 7 "DI_CRUISE_FAULT_ABS_MIA" 19 "DI_CRUISE_FAULT_ACCEL_JERK_OUT_OF_ISO_BOUNDS" 2 "DI_CRUISE_FAULT_PM_MIA" 8 "DI_CRUISE_FAULT_CRS_STATE_MISM" 18 "DI_CRUISE_FAULT_DAS_CONTROL_MIA" 11 "DI_CRUISE_FAULT_VDC_FAULT" 12 "DI_CRUISE_FAULT_ESP_MIA" 16 "DI_CRUISE_FAULT_VELOCITY_ESTIMATE_NOT_NORMAL" 1 "DI_CRUISE_FAULT_MOTOR_SPEED_MISMATCH" 20 "DI_CRUISE_FAULT_EPB_MIA" 9 "DI_CRUISE_FAULT_BRAKE_MIA" 10 "DI_CRUISE_FAULT_EPB_FAULT" 0 "DI_CRUISE_FAULT_NONE" ;
VAL_ 1318 DI_a098_fluxState 2 "DI_FLUXSTATE_STANDBY" 0 "DI_FLUXSTATE_START" 5 "DI_FLUXSTATE_ENABLED" 1 "DI_FLUXSTATE_TEST" 7 "DI_FLUXSTATE_VCONTROL" 4 "DI_FLUXSTATE_FLUX_DOWN" 9 "DI_FLUXSTATE_FAULT" 3 "DI_FLUXSTATE_FLUX_UP" 6 "DI_FLUXSTATE_ICONTROL" ;
VAL_ 1318 DI_a093_canID 659 "UI_chassisControl" 530 "BMS_status" 962 "VCLEFT_switchStatus" 577 "VCFRONT_coolant" 1925 "DBG_dynoOpenLoop" 1926 "DBG_dynoVehicleSim" 1862 "DBG_dynoControl" 340 "PM_state" 768 "BMS_info" 306 "BMS_hvBusStatus" 605 "CP_status" 259 "VCRIGHT_doorStatus" 548 "PCS_dcdcStatus" 2015 "UDS_functionalRequest" 583 "CMP_HVStatus" 801 "VCFRONT_sensors" 872 "GTW_updateStatus" 741 "DIS_power" 722 "BMS_driveLimits" 2047 "GTW_carConfig" 929 "VCFRONT_vehicleStatus" 737 "VCFRONT_status" 1798 "DBG_xcpDICommand" 531 "UI_cruiseControl" 1863 "DBG_DI_vdcControl" 804 "PM_crossCheck" 519 "PTC_feedbackStatus" 985 "VCSEC_authenticityResponse" 594 "BMS_powerAvailable" 680 "EPBL_status" 553 "SCCM_rightStalk" 644 "UI_vehicleModes" 258 "VCLEFT_doorStatus" 787 "UI_powertrainControl" 1320 "GTW_time" 744 "EPBR_status" 1280 "UI_debugECU" 1542 "UDS_diRequest" 545 "VCFRONT_LVPowerState" ;
VAL_ 1318 DI_a014_adState 0 "AD_STATE_STARTUP" 3 "AD_STATE_FAULTED" 1 "AD_STATE_NORMAL" 2 "AD_STATE_BACKUP" ;
VAL_ 1318 DI_a223_slaveADDState 0 "AD_STATE_STARTUP" 3 "AD_STATE_FAULTED" 1 "AD_STATE_NORMAL" 2 "AD_STATE_BACKUP" ;
VAL_ 1318 DI_a094_errorType 4 "CAN_RECEIVE_ERROR_SEQUENCE" 5 "CAN_RECEIVE_ERROR_DATA_INVALID" 1 "CAN_RECEIVE_ERROR_LENGTH_SHORT" 2 "CAN_RECEIVE_ERROR_LENGTH_LONG" 6 "CAN_RECEIVE_ERROR_UNKNOWN_ID" 0 "CAN_RECEIVE_ERROR_NONE" 3 "CAN_RECEIVE_ERROR_CHECKSUM" ;
VAL_ 1318 DI_a156_powerPolarity 3 "PSTG_OBS_POLARITY_ALL" 0 "PSTG_OBS_POLARITY_ZERO" 1 "PSTG_OBS_POLARITY_NEGATIVE" 2 "PSTG_OBS_POLARITY_POSITIVE" ;
VAL_ 1318 DI_a197_wheelSaturationReR 2 "VDC_SIGNAL_FREEZE" 6 "VDC_SIGNAL_QF_VALIDITY" 3 "VDC_SIGNAL_RATE" 4 "VDC_SIGNAL_QF" 0 "VDC_SIGNAL_VALID" 7 "VDC_SIGNAL_TEMP_QF_INVALID" 1 "VDC_SIGNAL_RANGE" 5 "VDC_SIGNAL_CAN" ;
VAL_ 1318 DI_a024_state 1 "SOPT_STATE_PSTG_BRING_UP" 5 "SOPT_STATE_CURRENT_TEST_POS" 6 "SOPT_STATE_CURRENT_TEST_NEG" 2 "SOPT_STATE_ASC_TEST" 0 "SOPT_STATE_INIT" 10 "SOPT_STATE_TEST_FAILED" 3 "SOPT_STATE_ASC_TEST_PASSED" 4 "SOPT_STATE_PWM_ENABLE" 9 "SOPT_STATE_TEST_SKIPPED" 8 "SOPT_STATE_TEST_PASSED" 7 "SOPT_STATE_TEST_PRE_PASSED" 11 "SOPT_STATE_TEST_RESTART" ;
VAL_ 1318 DI_a223_addState 0 "AD_STATE_STARTUP" 3 "AD_STATE_FAULTED" 1 "AD_STATE_NORMAL" 2 "AD_STATE_BACKUP" ;
VAL_ 1318 DI_a156_phaseCPolarity 3 "PSTG_OBS_POLARITY_ALL" 0 "PSTG_OBS_POLARITY_ZERO" 1 "PSTG_OBS_POLARITY_NEGATIVE" 2 "PSTG_OBS_POLARITY_POSITIVE" ;
VAL_ 1318 DI_a223_velocityEstimatorState 0 "VE_STATE_NOT_INITIALIZED" 1 "VE_STATE_WHEELS_NORMAL" 3 "VE_STATE_BACKUP_WHEELS_B" 2 "VE_STATE_BACKUP_WHEELS_A" 4 "VE_STATE_BACKUP_MOTOR" ;
VAL_ 1318 DI_a184_apcUnavailableReason 5 "DI_APC_UNAVAILABLE_GRADE_TOO_STEEP" 7 "DI_APC_UNAVAILABLE_EPB" 3 "DI_APC_UNAVAILABLE_CLOSURE_OPEN" 0 "DI_APC_UNAVAILABLE_NONE" 2 "DI_APC_UNAVAILABLE_VDC" 10 "DI_APC_UNAVAILABLE_GEAR" 9 "DI_APC_UNAVAILABLE_NOT_SUPPORTED" 6 "DI_APC_UNAVAILABLE_VALET_MODE" 11 "DI_APC_UNAVAILABLE_EBR" 4 "DI_APC_UNAVAILABLE_DRIVER_LEAVING" 8 "DI_APC_UNAVAILABLE_TRAILER_MODE" 1 "DI_APC_UNAVAILABLE_CRUISE" ;
VAL_ 1318 DI_a130_dasAebEvent 2 "AEB_FAULT" 0 "AEB_NOT_ACTIVE" 3 "AEB_SNA" 1 "AEB_ACTIVE" ;
VAL_ 1318 DI_a197_wheelSaturationReL 2 "VDC_SIGNAL_FREEZE" 6 "VDC_SIGNAL_QF_VALIDITY" 3 "VDC_SIGNAL_RATE" 4 "VDC_SIGNAL_QF" 0 "VDC_SIGNAL_VALID" 7 "VDC_SIGNAL_TEMP_QF_INVALID" 1 "VDC_SIGNAL_RANGE" 5 "VDC_SIGNAL_CAN" ;
VAL_ 1318 DI_a156_phaseBPolarity 3 "PSTG_OBS_POLARITY_ALL" 0 "PSTG_OBS_POLARITY_ZERO" 1 "PSTG_OBS_POLARITY_NEGATIVE" 2 "PSTG_OBS_POLARITY_POSITIVE" ;
VAL_ 1318 DI_a185_apcUnavailableReason 5 "DI_APC_UNAVAILABLE_GRADE_TOO_STEEP" 7 "DI_APC_UNAVAILABLE_EPB" 3 "DI_APC_UNAVAILABLE_CLOSURE_OPEN" 0 "DI_APC_UNAVAILABLE_NONE" 2 "DI_APC_UNAVAILABLE_VDC" 10 "DI_APC_UNAVAILABLE_GEAR" 9 "DI_APC_UNAVAILABLE_NOT_SUPPORTED" 6 "DI_APC_UNAVAILABLE_VALET_MODE" 11 "DI_APC_UNAVAILABLE_EBR" 4 "DI_APC_UNAVAILABLE_DRIVER_LEAVING" 8 "DI_APC_UNAVAILABLE_TRAILER_MODE" 1 "DI_APC_UNAVAILABLE_CRUISE" ;
VAL_ 1318 DI_a024_failReason 4 "SOPT_FAIL_TIMEDOUT" 2 "SOPT_FAIL_NEG_CURRENT" 1 "SOPT_FAIL_POS_CURRENT" 3 "SOPT_FAIL_DISAGREE" 5 "SOPT_FAIL_GATE_DRIVE_ERROR" 6 "SOPT_FAIL_FAULT_PRESENT" 0 "SOPT_FAIL_CACHED" 7 "SOPT_FAIL_ASC_TEST" ;
VAL_ 1318 DI_a223_btcTargetState 3 "SNA" 1 "BACKUP" 0 "OFF" 2 "ON" ;
VAL_ 1318 DI_a156_phaseAPolarity 3 "PSTG_OBS_POLARITY_ALL" 0 "PSTG_OBS_POLARITY_ZERO" 1 "PSTG_OBS_POLARITY_NEGATIVE" 2 "PSTG_OBS_POLARITY_POSITIVE" ;
VAL_ 1318 DI_a210_espActuatorState 3 "VDC_COMMAND_INVALID" 1 "VDC_ACTUATOR_DEGRADED" 0 "VDC_ACTUATOR_UNAVAILABLE" 2 "VDC_ACTUATOR_AVAILABLE" ;
VAL_ 1318 DI_a223_ptcTargetState 3 "SNA" 1 "BACKUP" 0 "FAULT" 2 "ON" ;
VAL_ 1318 DI_a064_torqueCmdState 8 "TorqueCmd_Invalid" 6 "TorqueCmd_Valid" 0 "TorqueCmd_SNA" ;
VAL_ 1318 DI_a130_aebSmState 3 "DI_AEB_STATE_ENABLE" 6 "DI_AEB_STATE_EXIT" 7 "DI_AEB_STATE_FAULT" 0 "DI_AEB_STATE_UNAVAILABLE" 1 "DI_AEB_STATE_STANDBY" 2 "DI_AEB_STATE_ENABLE_INIT" 4 "DI_AEB_STATE_STOPPING" 5 "DI_AEB_STATE_STANDSTILL" ;
VAL_ 1318 DI_a223_btcState 0 "OFF" 1 "ON" ;
VAL_ 1318 DI_a197_wheelSaturationFrR 2 "VDC_SIGNAL_FREEZE" 6 "VDC_SIGNAL_QF_VALIDITY" 3 "VDC_SIGNAL_RATE" 4 "VDC_SIGNAL_QF" 0 "VDC_SIGNAL_VALID" 7 "VDC_SIGNAL_TEMP_QF_INVALID" 1 "VDC_SIGNAL_RANGE" 5 "VDC_SIGNAL_CAN" ;
VAL_ 1318 DI_a227_vehiclePowerState 3 "VEHICLE_POWER_STATE_DRIVE" 1 "VEHICLE_POWER_STATE_CONDITIONING" 2 "VEHICLE_POWER_STATE_ACCESSORY" 0 "VEHICLE_POWER_STATE_OFF" ;
VAL_ 1318 DI_a232_UI_tractionControlMode 4 "TC_ROLLS_MODE_SELECTED" 1 "TC_SLIP_START_SELECTED" 0 "TC_NORMAL_SELECTED" 3 "TC_DEV_MODE_2_SELECTED" 2 "TC_DEV_MODE_1_SELECTED" 5 "TC_DYNO_MODE_SELECTED" ;
VAL_ 1318 DI_a210_tractionControlState 3 "SNA" 0 "FAULTED" 1 "BACKUP" 2 "ON" ;
VAL_ 1318 DI_a061_reason 1 "RAILED" 0 "RATE_OF_CHANGE" ;
VAL_ 1318 DI_a016_oldSafeState 0 "PSTG_SAFESTATE_NONE" 3 "PSTG_SAFESTATE_3PS_LOW" 2 "PSTG_SAFESTATE_3PS_HIGH" 1 "PSTG_SAFESTATE_ALL_OFF" ;
VAL_ 1318 DI_a156_observation 9 "PSTG_OBS_SINGLE_OPEN_PHASE" 8 "PSTG_OBS_DIODE_OPEN_LOW" 1 "PSTG_OBS_THREE_PHASE_SHORT" 6 "PSTG_OBS_DOUBLE_SHORT_LOW" 2 "PSTG_OBS_UNCONTROLLED_REGEN" 10 "PSTG_OBS_UNKNOWN" 5 "PSTG_OBS_DOUBLE_SHORT_HIGH" 7 "PSTG_OBS_DIODE_OPEN_HIGH" 4 "PSTG_OBS_SINGLE_SHORT_LOW" 3 "PSTG_OBS_SINGLE_SHORT_HIGH" 0 "PSTG_OBS_NO_CURRENT" ;
VAL_ 1318 DI_a185_apcCancelReason 0 "DI_APC_CANCEL_NONE" 8 "DI_APC_ABORT_DAS_STATE" 1 "DI_APC_CANCEL_GEAR" 16 "DI_APC_ABORT_DRIVER_LEAVING" 22 "DI_APC_ABORT_EPB_FAULT" 15 "DI_APC_ABORT_CLOSURE" 12 "DI_APC_ABORT_STOPPING_TIMEOUT" 17 "DI_APC_CANCEL_SELFPARK_STATE_TIMEOUT" 13 "DI_APC_ABORT_CRUISE_STATE" 18 "DI_APC_ABORT_DAS_SPEED" 20 "DI_APC_ABORT_GRADE_TOO_STEEP" 3 "DI_APC_CANCEL_OVERRIDE" 7 "DI_APC_ABORT_DAS_REQUEST" 2 "DI_APC_CANCEL_EPB_APPLY" 19 "DI_APC_ABORT_VEHICLE_SPEED" 6 "DI_APC_CANCEL_CRUISE" 14 "DI_APC_ABORT_BRAKE" 4 "DI_APC_ABORT_MOTION_TIMEOUT" 5 "DI_APC_CANCEL_AEB_ACTIVE" 10 "DI_APC_ABORT_SHIFT_TIMEOUT" 9 "DI_APC_ABORT_CONTROL_INTEGRATOR" 21 "DI_APC_ABORT_DISTANCE" 11 "DI_APC_ABORT_DI_SYS_STATE" ;
VAL_ 1318 DI_a216_MBPFailedCase 16 "VDC_VERT_ACCEL" 25 "VDC_RWD_FR_LEFT_WHEEL_SPEED" 26 "VDC_RWD_FR_RIGHT_WHEEL_SPEED" 23 "VDC_RER_WHEEL_SLIP_WHEELS_SPEEDS_VEHICLE_VELOCITY" 12 "VDC_PITCH_RATE" 30 "VDC_PERSIST_PITCH_RATE" 29 "VDC_PERSIST_ROLL_RATE" 6 "VDC_US_VELOCITY_YAW_RATE_VS_LAT_ACCEL" 18 "VDC_FR_WHEEL_SPEED_VS_VDC_MOTOR_SPEED" 11 "VDC_ROLL_RATE" 9 "VDC_MC_PRESSURE_BRAKE_PEDAL" 1 "VDC_LAT_ACCEL_STEERING_ANGLE_VELOCITY" 5 "VDC_OS_VELOCITY_YAW_RATE_VS_LAT_ACCEL" 13 "VDC_YAW_RATE" 10 "VDC_STEERING_ANGLE_OFFSET" 4 "VDC_VELOCITY_YAW_RATE_VS_LAT_ACCEL" 8 "VDC_BRAKE_TORQUES_VS_LONG_ACCEL" 28 "VDC_GRADE_ANGLE" 19 "VDC_RE_WHEEL_SPEED_VS_VDC_MOTOR_SPEED" 7 "VDC_VELOCITY_ESTIMATE_VS_WHEEL_SPEEDS" 15 "VDC_LAT_ACCEL" 20 "VDC_FRL_WHEEL_SLIP_WHEELS_SPEEDS_VEHICLE_VELOCITY" 0 "VDC_YAW_RATE_STEERING_ANGLE_VELOCITY" 24 "VDC_IBST_STROKE_VS_MC_PRESSURE" 22 "VDC_REL_WHEEL_SLIP_WHEELS_SPEEDS_VEHICLE_VELOCITY" 14 "VDC_LONG_ACCEL" 2 "VDC_YAW_RATE_WHEEL_SPEEDS" 27 "VDC_BANK_ANGLE" 3 "VDC_TIRE_MISMATCH_DETECTED" 21 "VDC_FRR_WHEEL_SLIP_WHEELS_SPEEDS_VEHICLE_VELOCITY" 17 "VDC_OFFSET_VERT_ACCEL" ;
VAL_ 1318 DI_a200_MBPFailedCase 16 "VDC_VERT_ACCEL" 25 "VDC_RWD_FR_LEFT_WHEEL_SPEED" 26 "VDC_RWD_FR_RIGHT_WHEEL_SPEED" 23 "VDC_RER_WHEEL_SLIP_WHEELS_SPEEDS_VEHICLE_VELOCITY" 12 "VDC_PITCH_RATE" 30 "VDC_PERSIST_PITCH_RATE" 29 "VDC_PERSIST_ROLL_RATE" 6 "VDC_US_VELOCITY_YAW_RATE_VS_LAT_ACCEL" 18 "VDC_FR_WHEEL_SPEED_VS_VDC_MOTOR_SPEED" 11 "VDC_ROLL_RATE" 9 "VDC_MC_PRESSURE_BRAKE_PEDAL" 1 "VDC_LAT_ACCEL_STEERING_ANGLE_VELOCITY" 5 "VDC_OS_VELOCITY_YAW_RATE_VS_LAT_ACCEL" 13 "VDC_YAW_RATE" 10 "VDC_STEERING_ANGLE_OFFSET" 4 "VDC_VELOCITY_YAW_RATE_VS_LAT_ACCEL" 8 "VDC_BRAKE_TORQUES_VS_LONG_ACCEL" 28 "VDC_GRADE_ANGLE" 19 "VDC_RE_WHEEL_SPEED_VS_VDC_MOTOR_SPEED" 7 "VDC_VELOCITY_ESTIMATE_VS_WHEEL_SPEEDS" 15 "VDC_LAT_ACCEL" 20 "VDC_FRL_WHEEL_SLIP_WHEELS_SPEEDS_VEHICLE_VELOCITY" 0 "VDC_YAW_RATE_STEERING_ANGLE_VELOCITY" 24 "VDC_IBST_STROKE_VS_MC_PRESSURE" 22 "VDC_REL_WHEEL_SLIP_WHEELS_SPEEDS_VEHICLE_VELOCITY" 14 "VDC_LONG_ACCEL" 2 "VDC_YAW_RATE_WHEEL_SPEEDS" 27 "VDC_BANK_ANGLE" 3 "VDC_TIRE_MISMATCH_DETECTED" 21 "VDC_FRR_WHEEL_SLIP_WHEELS_SPEEDS_VEHICLE_VELOCITY" 17 "VDC_OFFSET_VERT_ACCEL" ;
VAL_ 1318 DI_a090_reason 0 "TOOSLOW" 1 "TOOFAST" ;
VAL_ 1318 DI_a210_velocityEstimateState 0 "VE_STATE_NOT_INITIALIZED" 1 "VE_STATE_WHEELS_NORMAL" 3 "VE_STATE_BACKUP_WHEELS_B" 2 "VE_STATE_BACKUP_WHEELS_A" 4 "VE_STATE_BACKUP_MOTOR" ;
VAL_ 1318 DI_a184_apcCancelReason 0 "DI_APC_CANCEL_NONE" 8 "DI_APC_ABORT_DAS_STATE" 1 "DI_APC_CANCEL_GEAR" 16 "DI_APC_ABORT_DRIVER_LEAVING" 22 "DI_APC_ABORT_EPB_FAULT" 15 "DI_APC_ABORT_CLOSURE" 12 "DI_APC_ABORT_STOPPING_TIMEOUT" 17 "DI_APC_CANCEL_SELFPARK_STATE_TIMEOUT" 13 "DI_APC_ABORT_CRUISE_STATE" 18 "DI_APC_ABORT_DAS_SPEED" 20 "DI_APC_ABORT_GRADE_TOO_STEEP" 3 "DI_APC_CANCEL_OVERRIDE" 7 "DI_APC_ABORT_DAS_REQUEST" 2 "DI_APC_CANCEL_EPB_APPLY" 19 "DI_APC_ABORT_VEHICLE_SPEED" 6 "DI_APC_CANCEL_CRUISE" 14 "DI_APC_ABORT_BRAKE" 4 "DI_APC_ABORT_MOTION_TIMEOUT" 5 "DI_APC_CANCEL_AEB_ACTIVE" 10 "DI_APC_ABORT_SHIFT_TIMEOUT" 9 "DI_APC_ABORT_CONTROL_INTEGRATOR" 21 "DI_APC_ABORT_DISTANCE" 11 "DI_APC_ABORT_DI_SYS_STATE" ;
VAL_ 1318 DI_a065_canID 659 "UI_chassisControl" 530 "BMS_status" 962 "VCLEFT_switchStatus" 577 "VCFRONT_coolant" 1925 "DBG_dynoOpenLoop" 1926 "DBG_dynoVehicleSim" 1862 "DBG_dynoControl" 340 "PM_state" 768 "BMS_info" 306 "BMS_hvBusStatus" 605 "CP_status" 259 "VCRIGHT_doorStatus" 548 "PCS_dcdcStatus" 2015 "UDS_functionalRequest" 583 "CMP_HVStatus" 801 "VCFRONT_sensors" 872 "GTW_updateStatus" 741 "DIS_power" 722 "BMS_driveLimits" 2047 "GTW_carConfig" 929 "VCFRONT_vehicleStatus" 737 "VCFRONT_status" 1798 "DBG_xcpDICommand" 531 "UI_cruiseControl" 1863 "DBG_DI_vdcControl" 804 "PM_crossCheck" 519 "PTC_feedbackStatus" 985 "VCSEC_authenticityResponse" 594 "BMS_powerAvailable" 680 "EPBL_status" 553 "SCCM_rightStalk" 644 "UI_vehicleModes" 258 "VCLEFT_doorStatus" 787 "UI_powertrainControl" 1320 "GTW_time" 744 "EPBR_status" 1280 "UI_debugECU" 1542 "UDS_diRequest" 545 "VCFRONT_LVPowerState" ;
VAL_ 1318 DI_a165_crsCancelReason 0 "DI_CRUISE_CANCEL_NONE" 4 "DI_CRUISE_CANCEL_STALK" 7 "DI_CRUISE_CANCEL_DAS" 6 "DI_CRUISE_CANCEL_PARK" 2 "DI_CRUISE_CANCEL_SKID" 3 "DI_CRUISE_CANCEL_BRAKE" 1 "DI_CRUISE_CANCEL_APC_REQUEST" 5 "DI_CRUISE_CANCEL_GEAR" ;
VAL_ 1318 DI_a221_vdcActivationAlertType 0 "VDC_ACT_ALERT_80_PRCNT_OF_THRESH" 1 "VDC_ACT_ALERT_VDCR_CONTROL_ACTIVE" 2 "VDC_ACT_ALERT_VDCA_BRAKE_TORQUE_REQ" ;
VAL_ 1318 DI_a130_aebFaultReason 0 "DI_AEB_FAULT_NONE" 15 "DI_AEB_FAULT_DAS_REQ_DI_UNAVAIL" 9 "DI_AEB_FAULT_ACCEL_OUT_OF_BOUNDS" 11 "DI_AEB_FAULT_ESP_FAULT" 10 "DI_AEB_FAULT_EPB_NOT_PARKED" 1 "DI_AEB_FAULT_EPB_MIA" 4 "DI_AEB_FAULT_SPEED_DELTA" 13 "DI_AEB_FAULT_MIN_TIME_BTWN_EVENTS" 2 "DI_AEB_FAULT_PM_MIA" 14 "DI_AEB_FAULT_ACCEL_REQ_INVALID" 12 "DI_AEB_FAULT_ESP_MIA" 5 "DI_AEB_FAULT_DAS_CONTROL_MIA" 8 "DI_AEB_FAULT_PM_REQUEST" 7 "DI_AEB_FAULT_VEL_EST_ABNORMAL" 6 "DI_AEB_FAULT_DAS_SNA" 3 "DI_AEB_FAULT_EBR_FAULT" ;
VAL_ 1318 DI_a211_motorSpeedFr 2 "VDC_SIGNAL_FREEZE" 6 "VDC_SIGNAL_QF_VALIDITY" 3 "VDC_SIGNAL_RATE" 4 "VDC_SIGNAL_QF" 0 "VDC_SIGNAL_VALID" 7 "VDC_SIGNAL_TEMP_QF_INVALID" 1 "VDC_SIGNAL_RANGE" 5 "VDC_SIGNAL_CAN" ;
VAL_ 1318 DI_a215_wheelSpeedNonCGReL 2 "VDC_SIGNAL_FREEZE" 6 "VDC_SIGNAL_QF_VALIDITY" 3 "VDC_SIGNAL_RATE" 4 "VDC_SIGNAL_QF" 0 "VDC_SIGNAL_VALID" 7 "VDC_SIGNAL_TEMP_QF_INVALID" 1 "VDC_SIGNAL_RANGE" 5 "VDC_SIGNAL_CAN" ;
VAL_ 1318 DI_a146_panicReason 1 "PBRK_PANIC_EPB_FAULT" 5 "PBRK_PANIC_SKID_DETECTED" 6 "PBRK_PANIC_EPB_RELEASE_TIMEOUT" 3 "PBRK_PANIC_EPB_APPLY_TIMEOUT" 0 "PBRK_PANIC_NONE" 4 "PBRK_PANIC_EPB_INVALID" 2 "PBRK_PANIC_EPB_MIA" ;
VAL_ 1318 DI_a064_interventionType 7 "TRQP_excessiveRegenTorque" 8 "TRQP_torqueInNeutral" 0 "TRQP_masterTorqueMonitorShutoff" 2 "TRQP_torqueCmdInvalid" 1 "TRQP_resolver" 3 "TRQP_cruiseFault" 10 "TRQP_switchOffPathTestFail" 5 "TRQP_accumulatedTorque" 9 "TRQP_inconsistentTorqueSign" 6 "TRQP_torqueReversal" 4 "TRQP_motorMovementDetected" ;
VAL_ 1318 DI_a200_MBPCheckStatus 1 "VDC_CHECK_ACTIVE" 0 "VDC_CHECK_GHOSTED" ;
VAL_ 1318 DI_a011_reason 0 "GATE_DRIVE_SUPPLY" 3 "FAULT_DURING_CONFIG" 1 "REG_DATA_MISMATCH" 2 "CRC_MISMATCH" ;
VAL_ 1318 DI_a193_brakeTorqueFrL 2 "VDC_SIGNAL_FREEZE" 6 "VDC_SIGNAL_QF_VALIDITY" 3 "VDC_SIGNAL_RATE" 4 "VDC_SIGNAL_QF" 0 "VDC_SIGNAL_VALID" 7 "VDC_SIGNAL_TEMP_QF_INVALID" 1 "VDC_SIGNAL_RANGE" 5 "VDC_SIGNAL_CAN" ;
VAL_ 1318 DI_a177_newFitment 0 "FITMENT_SQUARE" 3 "FITMENT_SNA" 1 "FITMENT_STAGGERED" ;
VAL_ 1318 DI_a212_wheelSpeedCGFrL 2 "VDC_SIGNAL_FREEZE" 6 "VDC_SIGNAL_QF_VALIDITY" 3 "VDC_SIGNAL_RATE" 4 "VDC_SIGNAL_QF" 0 "VDC_SIGNAL_VALID" 7 "VDC_SIGNAL_TEMP_QF_INVALID" 1 "VDC_SIGNAL_RANGE" 5 "VDC_SIGNAL_CAN" ;
VAL_ 1318 DI_a175_crsNotAvailableReason 17 "DI_CRUISE_NOT_AVAILABLE_WAIT_INIT" 12 "DI_CRUISE_NOT_AVAILABLE_DI_STATE" 8 "DI_CRUISE_NOT_AVAILABLE_SEAT_BELT_UNBUCKLED" 13 "DI_CRUISE_NOT_AVAILABLE_CONFIG" 16 "DI_CRUISE_NOT_AVAILABLE_VEL_EST" 7 "DI_CRUISE_NOT_AVAILABLE_CLOSURE_OPEN" 0 "DI_CRUISE_NOT_AVAILABLE_NONE" 15 "DI_CRUISE_NOT_AVAILABLE_MIN_SPEED" 4 "DI_CRUISE_NOT_AVAILABLE_TC_ACTIVE" 5 "DI_CRUISE_NOT_AVAILABLE_ABS_ACTIVE" 2 "DI_CRUISE_NOT_AVAILABLE_VDC_OR_TC_OFF" 18 "DI_CRUISE_NOT_AVAILABLE_UI_MIA" 14 "DI_CRUISE_NOT_AVAILABLE_AEB" 9 "DI_CRUISE_NOT_AVAILABLE_VALET_MODE" 19 "DI_CRUISE_NOT_AVAILABLE_DAS_SNA" 10 "DI_CRUISE_NOT_AVAILABLE_EBR" 20 "DI_CRUISE_NOT_AVAILABLE_TRACK_MODE_ACTIVE" 6 "DI_CRUISE_NOT_AVAILABLE_ACC_CANCEL" 1 "DI_CRUISE_NOT_AVAILABLE_NO_ALERT" 3 "DI_CRUISE_NOT_AVAILABLE_VDC_ACTIVE_OR_DEGRADED" 11 "DI_CRUISE_NOT_AVAILABLE_MOTOR_SPEED" ;
VAL_ 1318 DI_a152_errorType 5 "LIN_HEADER_ERROR" 4 "LIN_OVERFLOW_ERROR" 6 "LIN_TIMEOUT_ERROR" 2 "LIN_CHECKSUM_ERROR" 3 "LIN_SCHEDULE_ERROR" 0 "LIN_NO_ERROR" 1 "LIN_FRAMING_ERROR" ;
VAL_ 1318 DI_a208_motorTorqueRe 2 "VDC_SIGNAL_FREEZE" 6 "VDC_SIGNAL_QF_VALIDITY" 3 "VDC_SIGNAL_RATE" 4 "VDC_SIGNAL_QF" 0 "VDC_SIGNAL_VALID" 7 "VDC_SIGNAL_TEMP_QF_INVALID" 1 "VDC_SIGNAL_RANGE" 5 "VDC_SIGNAL_CAN" ;
VAL_ 1318 DI_a217_IrrationalOutputReason 2 "VDC_INCOMPATIBLE_WHEEL_LEVEL_REQUEST" 3 "VDC_UNVALIDATED_WHEEL_LEVEL_REQUEST" 1 "VDC_WHEEL_LEVEL_REQUEST_INCOMPLETE" 4 "VDC_INVALID_COMMAND_TYPE" 0 "VDC_ALL_WHEELS_FEED_THROUGH" ;
VAL_ 1318 DI_a220_vdcActivationAlertType 0 "VDC_ACT_ALERT_80_PRCNT_OF_THRESH" 1 "VDC_ACT_ALERT_VDCR_CONTROL_ACTIVE" 2 "VDC_ACT_ALERT_VDCA_BRAKE_TORQUE_REQ" ;
VAL_ 1318 DI_a213_wheelSpeedCGReL 2 "VDC_SIGNAL_FREEZE" 6 "VDC_SIGNAL_QF_VALIDITY" 3 "VDC_SIGNAL_RATE" 4 "VDC_SIGNAL_QF" 0 "VDC_SIGNAL_VALID" 7 "VDC_SIGNAL_TEMP_QF_INVALID" 1 "VDC_SIGNAL_RANGE" 5 "VDC_SIGNAL_CAN" ;
VAL_ 1318 DI_a198_MCPressure 2 "VDC_SIGNAL_FREEZE" 6 "VDC_SIGNAL_QF_VALIDITY" 3 "VDC_SIGNAL_RATE" 4 "VDC_SIGNAL_QF" 0 "VDC_SIGNAL_VALID" 7 "VDC_SIGNAL_TEMP_QF_INVALID" 1 "VDC_SIGNAL_RANGE" 5 "VDC_SIGNAL_CAN" ;
VAL_ 1318 DI_a214_wheelSpeedNonCGFrL 2 "VDC_SIGNAL_FREEZE" 6 "VDC_SIGNAL_QF_VALIDITY" 3 "VDC_SIGNAL_RATE" 4 "VDC_SIGNAL_QF" 0 "VDC_SIGNAL_VALID" 7 "VDC_SIGNAL_TEMP_QF_INVALID" 1 "VDC_SIGNAL_RANGE" 5 "VDC_SIGNAL_CAN" ;
VAL_ 1318 DI_a067_canID 659 "UI_chassisControl" 530 "BMS_status" 962 "VCLEFT_switchStatus" 577 "VCFRONT_coolant" 1925 "DBG_dynoOpenLoop" 1926 "DBG_dynoVehicleSim" 1862 "DBG_dynoControl" 340 "PM_state" 768 "BMS_info" 306 "BMS_hvBusStatus" 605 "CP_status" 259 "VCRIGHT_doorStatus" 548 "PCS_dcdcStatus" 2015 "UDS_functionalRequest" 583 "CMP_HVStatus" 801 "VCFRONT_sensors" 872 "GTW_updateStatus" 741 "DIS_power" 722 "BMS_driveLimits" 2047 "GTW_carConfig" 929 "VCFRONT_vehicleStatus" 737 "VCFRONT_status" 1798 "DBG_xcpDICommand" 531 "UI_cruiseControl" 1863 "DBG_DI_vdcControl" 804 "PM_crossCheck" 519 "PTC_feedbackStatus" 985 "VCSEC_authenticityResponse" 594 "BMS_powerAvailable" 680 "EPBL_status" 553 "SCCM_rightStalk" 644 "UI_vehicleModes" 258 "VCLEFT_doorStatus" 787 "UI_powertrainControl" 1320 "GTW_time" 744 "EPBR_status" 1280 "UI_debugECU" 1542 "UDS_diRequest" 545 "VCFRONT_LVPowerState" ;
VAL_ 1318 DI_a062_limpReason 7 "DI_LIMP_LOW_FLOW" 13 "DI_LIMP_WRONG_CS_CALIBRATION" 19 "DI_LIMP_CONFIG_MISMATCH" 28 "DI_LIMP_OIL_PUMP_FAILURE" 26 "DI_LIMP_SLAVE_MIA" 30 "DI_LIMP_HEATSINK_SENSOR_IRRATIONAL" 8 "DI_LIMP_OUTLET_TEMP" 23 "DI_LIMP_CAPACITOR_OVERTEMP" 16 "DI_LIMP_PMHEARTBEAT" 1 "DI_LIMP_BUSV_SENSOR_IRRATIONAL" 25 "DI_LIMP_SLAVE_REQUEST" 11 "DI_LIMP_DELTAT_TOO_NEGATIVE" 17 "DI_LIMP_PMREQUEST" 5 "DI_LIMP_12V_SUPPLY_UNDERVOLTAGE" 3 "DI_LIMP_NO_FUNC_HEATSINK_SENSOR" 0 "DI_LIMP_PHASE_IMBALANCE" 27 "DI_LIMP_FACTORY_GLIDER" 20 "DI_LIMP_DI_MIA" 15 "DI_LIMP_TRQ_CROSS_CHECK" 21 "DI_LIMP_TRQCMD_VALIDITY_UNKNOWN" 24 "DI_LIMP_CONTACTOR_WELD" 29 "DI_LIMP_OIL_PUMP_FLUID_OVERTEMP" 2 "DI_LIMP_NO_FUNC_STATORT_SENSOR" 14 "DI_LIMP_EXTERNAL_COMMAND" 6 "DI_LIMP_BMS_MIA" 22 "DI_LIMP_GTW_MIA" 9 "DI_LIMP_AMBIENT_TEMP" 10 "DI_LIMP_DELTAT_TOO_POSITIVE" 18 "DI_LIMP_HEATSINK_TEMP" 12 "DI_LIMP_STATOR_TEMP" 4 "DI_LIMP_NO_FLUID" ;
VAL_ 1318 DI_a196_wheelSlipReL 2 "VDC_SIGNAL_FREEZE" 6 "VDC_SIGNAL_QF_VALIDITY" 3 "VDC_SIGNAL_RATE" 4 "VDC_SIGNAL_QF" 0 "VDC_SIGNAL_VALID" 7 "VDC_SIGNAL_TEMP_QF_INVALID" 1 "VDC_SIGNAL_RANGE" 5 "VDC_SIGNAL_CAN" ;
VAL_ 1318 DI_a195_wheelSlipFrL 2 "VDC_SIGNAL_FREEZE" 6 "VDC_SIGNAL_QF_VALIDITY" 3 "VDC_SIGNAL_RATE" 4 "VDC_SIGNAL_QF" 0 "VDC_SIGNAL_VALID" 7 "VDC_SIGNAL_TEMP_QF_INVALID" 1 "VDC_SIGNAL_RANGE" 5 "VDC_SIGNAL_CAN" ;
VAL_ 1318 DI_a218_vdcActivationAlertType 0 "VDC_ACT_ALERT_80_PRCNT_OF_THRESH" 1 "VDC_ACT_ALERT_VDCR_CONTROL_ACTIVE" 2 "VDC_ACT_ALERT_VDCA_BRAKE_TORQUE_REQ" ;
VAL_ 1318 DI_a216_MBPCheckStatus 1 "VDC_CHECK_ACTIVE" 0 "VDC_CHECK_GHOSTED" ;
VAL_ 1318 DI_a232_velocityEstimatorState 0 "VE_STATE_NOT_INITIALIZED" 1 "VE_STATE_WHEELS_NORMAL" 3 "VE_STATE_BACKUP_WHEELS_B" 2 "VE_STATE_BACKUP_WHEELS_A" 4 "VE_STATE_BACKUP_MOTOR" ;
VAL_ 1318 DI_a104_proxIrrationalReason 1 "CP_MISMATCH" 0 "PROX_HARDLINE_TOGGLE" ;
VAL_ 1318 DI_a016_newSafeState 0 "PSTG_SAFESTATE_NONE" 3 "PSTG_SAFESTATE_3PS_LOW" 2 "PSTG_SAFESTATE_3PS_HIGH" 1 "PSTG_SAFESTATE_ALL_OFF" ;
VAL_ 1318 DI_a207_motorTorqueFr 2 "VDC_SIGNAL_FREEZE" 6 "VDC_SIGNAL_QF_VALIDITY" 3 "VDC_SIGNAL_RATE" 4 "VDC_SIGNAL_QF" 0 "VDC_SIGNAL_VALID" 7 "VDC_SIGNAL_TEMP_QF_INVALID" 1 "VDC_SIGNAL_RANGE" 5 "VDC_SIGNAL_CAN" ;
VAL_ 1318 DI_a156_initialSafeState 0 "PSTG_SAFESTATE_NONE" 3 "PSTG_SAFESTATE_3PS_LOW" 2 "PSTG_SAFESTATE_3PS_HIGH" 1 "PSTG_SAFESTATE_ALL_OFF" ;
VAL_ 1318 DI_a135_vhldFaultReason 9 "DI_VHLD_FAULT_VDC_FAULT" 10 "DI_VHLD_FAULT_ESP_MIA" 6 "DI_VHLD_FAULT_PM_REQUEST" 5 "DI_VHLD_FAULT_WHEEL_SPDS_INVAL" 3 "DI_VHLD_FAULT_EBR_FAULT" 0 "DI_VHLD_FAULT_NONE" 4 "DI_VHLD_FAULT_BRAKE_INVALID" 8 "DI_VHLD_FAULT_NOT_STOPPED" 7 "DI_VHLD_FAULT_EPB_NOT_PARKED" 2 "DI_VHLD_FAULT_EPB_MIA" 1 "DI_VHLD_FAULT_PM_MIA" ;
VAL_ 1318 DI_a123_lossReason 3 "HIGH_VARIANCE" 1 "NO_FLUX_UP" 2 "NO_TORQUE" ;
VAL_ 1318 DI_a094_canID 659 "UI_chassisControl" 530 "BMS_status" 962 "VCLEFT_switchStatus" 577 "VCFRONT_coolant" 1925 "DBG_dynoOpenLoop" 1926 "DBG_dynoVehicleSim" 1862 "DBG_dynoControl" 340 "PM_state" 768 "BMS_info" 306 "BMS_hvBusStatus" 605 "CP_status" 259 "VCRIGHT_doorStatus" 548 "PCS_dcdcStatus" 2015 "UDS_functionalRequest" 583 "CMP_HVStatus" 801 "VCFRONT_sensors" 872 "GTW_updateStatus" 741 "DIS_power" 722 "BMS_driveLimits" 2047 "GTW_carConfig" 929 "VCFRONT_vehicleStatus" 737 "VCFRONT_status" 1798 "DBG_xcpDICommand" 531 "UI_cruiseControl" 1863 "DBG_DI_vdcControl" 804 "PM_crossCheck" 519 "PTC_feedbackStatus" 985 "VCSEC_authenticityResponse" 594 "BMS_powerAvailable" 680 "EPBL_status" 553 "SCCM_rightStalk" 644 "UI_vehicleModes" 258 "VCLEFT_doorStatus" 787 "UI_powertrainControl" 1320 "GTW_time" 744 "EPBR_status" 1280 "UI_debugECU" 1542 "UDS_diRequest" 545 "VCFRONT_LVPowerState" ;
VAL_ 1318 DI_a202_reason 1 "DI_WASTE_UNAVAILABLE_NO_ALERT" 5 "DI_WASTE_UNAVAILABLE_GPO" 3 "DI_WASTE_UNAVAILABLE_MOVEMENT" 2 "DI_WASTE_UNAVAILABLE_PARKBRAKE" 0 "DI_WASTE_UNAVAILABLE_NONE" 4 "DI_WASTE_UNAVAILABLE_LIMP" 7 "DI_WASTE_UNAVAILABLE_SERVICE_MODE" 6 "DI_WASTE_UNAVAILABLE_UPDATE_STARTED" ;
VAL_ 1318 DI_a204_longAccel 2 "VDC_SIGNAL_FREEZE" 6 "VDC_SIGNAL_QF_VALIDITY" 3 "VDC_SIGNAL_RATE" 4 "VDC_SIGNAL_QF" 0 "VDC_SIGNAL_VALID" 7 "VDC_SIGNAL_TEMP_QF_INVALID" 1 "VDC_SIGNAL_RANGE" 5 "VDC_SIGNAL_CAN" ;
VAL_ 1318 DI_a226_systState 6 "SSM_STATE_WAIT_FOR_RETRY" 8 "SSM_STATE_FAULT" 1 "SSM_STATE_UNAVAILABLE" 2 "SSM_STATE_IDLE" 7 "SSM_STATE_RETRY" 0 "SSM_STATE_START" 3 "SSM_STATE_STANDBY" 5 "SSM_STATE_ABORT" 4 "SSM_STATE_ENABLE" ;
VAL_ 1318 DI_a209_vehicleSpeed 2 "VDC_SIGNAL_FREEZE" 6 "VDC_SIGNAL_QF_VALIDITY" 3 "VDC_SIGNAL_RATE" 4 "VDC_SIGNAL_QF" 0 "VDC_SIGNAL_VALID" 7 "VDC_SIGNAL_TEMP_QF_INVALID" 1 "VDC_SIGNAL_RANGE" 5 "VDC_SIGNAL_CAN" ;
VAL_ 1318 DI_a219_vdcActivationAlertType 0 "VDC_ACT_ALERT_80_PRCNT_OF_THRESH" 1 "VDC_ACT_ALERT_VDCR_CONTROL_ACTIVE" 2 "VDC_ACT_ALERT_VDCA_BRAKE_TORQUE_REQ" ;
VAL_ 1318 DI_a122_taskID 1 "DI_STACK_CONTROL" 7 "DI_STACK_IMM" 0 "DI_STACK_SYSTEM" 2 "DI_STACK_IDLE" 8 "DI_STACK_10Hz" 6 "DI_STACK_XCP" 4 "DI_STACK_EEP" 3 "DI_STACK_DHWF" 5 "DI_STACK_UDS" ;
VAL_ 1318 DI_a121_badRegReason 3 "IQ_OFF_TARGET" 5 "TORQUE_OFF_TARGET" 2 "ID_OFF_TARGET" 1 "RMS_I_HIGH" 4 "FLUX_OFF_TARGET" ;
VAL_ 1318 DI_a061_sensor 1 "PH2" 2 "PH3" 0 "PH1" ;
VAL_ 1318 DI_a063_gpoReason 3 "DI_GPO_FLUID_DELTAT" 4 "DI_GPO_AMBIENT_OVERTEMP" 0 "DI_GPO_OUTLET_OVERTEMP" 8 "DI_GPO_MOTOR_HALT_REQUEST" 1 "DI_GPO_HEATSINK_OVERTEMP" 2 "DI_GPO_STATOR_OVERTEMP" 7 "DI_GPO_CAPACITOR_OVERTEMP" 6 "DI_GPO_NOT_ENOUGH_12V" 5 "DI_GPO_NO_BATTERY_POWER" ;
VAL_ 1318 DI_a126_limpReason 7 "DI_LIMP_LOW_FLOW" 13 "DI_LIMP_WRONG_CS_CALIBRATION" 19 "DI_LIMP_CONFIG_MISMATCH" 28 "DI_LIMP_OIL_PUMP_FAILURE" 26 "DI_LIMP_SLAVE_MIA" 30 "DI_LIMP_HEATSINK_SENSOR_IRRATIONAL" 8 "DI_LIMP_OUTLET_TEMP" 23 "DI_LIMP_CAPACITOR_OVERTEMP" 16 "DI_LIMP_PMHEARTBEAT" 1 "DI_LIMP_BUSV_SENSOR_IRRATIONAL" 25 "DI_LIMP_SLAVE_REQUEST" 11 "DI_LIMP_DELTAT_TOO_NEGATIVE" 17 "DI_LIMP_PMREQUEST" 5 "DI_LIMP_12V_SUPPLY_UNDERVOLTAGE" 3 "DI_LIMP_NO_FUNC_HEATSINK_SENSOR" 0 "DI_LIMP_PHASE_IMBALANCE" 27 "DI_LIMP_FACTORY_GLIDER" 20 "DI_LIMP_DI_MIA" 15 "DI_LIMP_TRQ_CROSS_CHECK" 21 "DI_LIMP_TRQCMD_VALIDITY_UNKNOWN" 24 "DI_LIMP_CONTACTOR_WELD" 29 "DI_LIMP_OIL_PUMP_FLUID_OVERTEMP" 2 "DI_LIMP_NO_FUNC_STATORT_SENSOR" 14 "DI_LIMP_EXTERNAL_COMMAND" 6 "DI_LIMP_BMS_MIA" 22 "DI_LIMP_GTW_MIA" 9 "DI_LIMP_AMBIENT_TEMP" 10 "DI_LIMP_DELTAT_TOO_POSITIVE" 18 "DI_LIMP_HEATSINK_TEMP" 12 "DI_LIMP_STATOR_TEMP" 4 "DI_LIMP_NO_FLUID" ;
VAL_ 1318 DI_a227_hvState 6 "HV_UP" 5 "HV_UP_FOR_DC_CHARGE" 0 "HV_DOWN" 2 "HV_GOING_DOWN" 1 "HV_COMING_UP" 4 "HV_UP_FOR_CHARGE" 3 "HV_UP_FOR_DRIVE" ;
VAL_ 1318 DI_a205_latAccel 2 "VDC_SIGNAL_FREEZE" 6 "VDC_SIGNAL_QF_VALIDITY" 3 "VDC_SIGNAL_RATE" 4 "VDC_SIGNAL_QF" 0 "VDC_SIGNAL_VALID" 7 "VDC_SIGNAL_TEMP_QF_INVALID" 1 "VDC_SIGNAL_RANGE" 5 "VDC_SIGNAL_CAN" ;
VAL_ 1318 DI_a097_errorType 4 "LOST" 5 "DPOT_READ" 1 "READ" 6 "DPOT_WRITE" 2 "WRITE" 0 "OPEN" 3 "CRC" ;
VAL_ 1318 DI_a136_spiErrorType 4 "DI_SPI_CANID_MISMATCH" 2 "DI_SPI_SYNC_BIT" 7 "DI_SPI_BUFFER0_OVERWRITE" 1 "DI_SPI_RESERVED" 3 "DI_SPI_SUBID_SEQUENCE" 0 "DI_SPI_NONE" 6 "DI_SPI_UNKNOWN_ID" 5 "DI_SPI_CRC_MISMATCH" ;
VAL_ 1318 DI_a206_verticalAccel 2 "VDC_SIGNAL_FREEZE" 6 "VDC_SIGNAL_QF_VALIDITY" 3 "VDC_SIGNAL_RATE" 4 "VDC_SIGNAL_QF" 0 "VDC_SIGNAL_VALID" 7 "VDC_SIGNAL_TEMP_QF_INVALID" 1 "VDC_SIGNAL_RANGE" 5 "VDC_SIGNAL_CAN" ;
VAL_ 1318 DI_a180_crsNotAvailableReason 17 "DI_CRUISE_NOT_AVAILABLE_WAIT_INIT" 12 "DI_CRUISE_NOT_AVAILABLE_DI_STATE" 8 "DI_CRUISE_NOT_AVAILABLE_SEAT_BELT_UNBUCKLED" 13 "DI_CRUISE_NOT_AVAILABLE_CONFIG" 16 "DI_CRUISE_NOT_AVAILABLE_VEL_EST" 7 "DI_CRUISE_NOT_AVAILABLE_CLOSURE_OPEN" 0 "DI_CRUISE_NOT_AVAILABLE_NONE" 15 "DI_CRUISE_NOT_AVAILABLE_MIN_SPEED" 4 "DI_CRUISE_NOT_AVAILABLE_TC_ACTIVE" 5 "DI_CRUISE_NOT_AVAILABLE_ABS_ACTIVE" 2 "DI_CRUISE_NOT_AVAILABLE_VDC_OR_TC_OFF" 18 "DI_CRUISE_NOT_AVAILABLE_UI_MIA" 14 "DI_CRUISE_NOT_AVAILABLE_AEB" 9 "DI_CRUISE_NOT_AVAILABLE_VALET_MODE" 19 "DI_CRUISE_NOT_AVAILABLE_DAS_SNA" 10 "DI_CRUISE_NOT_AVAILABLE_EBR" 20 "DI_CRUISE_NOT_AVAILABLE_TRACK_MODE_ACTIVE" 6 "DI_CRUISE_NOT_AVAILABLE_ACC_CANCEL" 1 "DI_CRUISE_NOT_AVAILABLE_NO_ALERT" 3 "DI_CRUISE_NOT_AVAILABLE_VDC_ACTIVE_OR_DEGRADED" 11 "DI_CRUISE_NOT_AVAILABLE_MOTOR_SPEED" ;
VAL_ 1318 DI_a223_ptcState 2 "LOCAL_PTC_STATE_ADD_REDUCED" 0 "LOCAL_PTC_STATE_FAULTED" 1 "LOCAL_PTC_STATE_BACKUP" 3 "LOCAL_PTC_STATE_ON" 4 "LOCAL_PTC_STATE_SNA" ;
VAL_ 1318 DI_a127_gpoReason 3 "DI_GPO_FLUID_DELTAT" 4 "DI_GPO_AMBIENT_OVERTEMP" 0 "DI_GPO_OUTLET_OVERTEMP" 8 "DI_GPO_MOTOR_HALT_REQUEST" 1 "DI_GPO_HEATSINK_OVERTEMP" 2 "DI_GPO_STATOR_OVERTEMP" 7 "DI_GPO_CAPACITOR_OVERTEMP" 6 "DI_GPO_NOT_ENOUGH_12V" 5 "DI_GPO_NO_BATTERY_POWER" ;
VAL_ 1318 DI_a015_reason 1 "ARMED_AFTER_PREAUTH" 0 "AUTH_FAIL" ;
VAL_ 1318 DI_a194_brakeTorqueReL 2 "VDC_SIGNAL_FREEZE" 6 "VDC_SIGNAL_QF_VALIDITY" 3 "VDC_SIGNAL_RATE" 4 "VDC_SIGNAL_QF" 0 "VDC_SIGNAL_VALID" 7 "VDC_SIGNAL_TEMP_QF_INVALID" 1 "VDC_SIGNAL_RANGE" 5 "VDC_SIGNAL_CAN" ;
VAL_ 1318 DI_a197_wheelSaturationFrL 2 "VDC_SIGNAL_FREEZE" 6 "VDC_SIGNAL_QF_VALIDITY" 3 "VDC_SIGNAL_RATE" 4 "VDC_SIGNAL_QF" 0 "VDC_SIGNAL_VALID" 7 "VDC_SIGNAL_TEMP_QF_INVALID" 1 "VDC_SIGNAL_RANGE" 5 "VDC_SIGNAL_CAN" ;
VAL_ 1318 DI_alertType 0 "ALERT_CLEARED" 1 "ALERT_SET" ;
VAL_ 1318 DI_alertID 195 "DI_a195_vdcEspSlipFr" 31 "DI_a031_phaseAcurrentOffset" 185 "DI_a185_autoparkAborted" 60 "DI_a060_heatsinkUT" 147 "DI_a147_highTorqueWearLimit" 160 "DI_a160_busVoltageAnomaly" 146 "DI_a146_pbrkPanicEpbFault" 9 "DI_a009_hwEncoderB" 5 "DI_a005_hwPhaseBpeak" 171 "DI_a171_driveRailNotRequested" 191 "DI_a191_brakeShiftReq" 241 "DI_a241_systemThermallyLimited" 30 "DI_a030_phaseCrms" 233 "DI_a233_diMsgMissed" 1 "DI_a001_hwPhaseAgateDrive" 208 "DI_a208_vdcPowertrainTorqueRe" 145 "DI_a145_pbrkPanicSkid" 220 "DI_a220_vdcUndersteerDecelActive" 199 "DI_a199_vdcFaulted" 167 "DI_a167_keyNotAuthenticated" 228 "DI_a228_brakeTempEstUnavailable" 172 "DI_a172_accelPressedInNP" 100 "DI_a100_assertion" 3 "DI_a003_hwPhaseCgateDrive" 71 "DI_a071_busDisconnected" 215 "DI_a215_velEstWheelSpeedNonCGRe" 18 "DI_a018_hw12vSupplyUV" 91 "DI_a091_espMIA" 134 "DI_a134_wheelSpeedIrrational" 12 "DI_a012_accel5VSupply" 54 "DI_a054_driveInverterOT" 222 "DI_a222_vdcDisabled" 217 "DI_a217_vdcOutputIrrational" 124 "DI_a124_cruiseFault" 240 "DI_a240_torqueSplitStuck" 51 "DI_a051_batteryOvercurrent" 61 "DI_a061_heatsinkSensor" 96 "DI_a096_memoryError" 87 "DI_a087_gtwMIA" 154 "DI_a154_resolver" 85 "DI_a085_proximityInEnable" 142 "DI_a142_highLashAngle" 180 "DI_a180_crsSeatbeltUnbuckled" 35 "DI_a035_phaseCurrentBalance" 227 "DI_a227_contactorsNotClosed" 26 "DI_a026_phaseBpeak" 131 "DI_a131_highSpeedWearLimit" 109 "DI_a109_cruiseMIA" 229 "DI_a229_batteryIsHeating" 104 "DI_a104_proximityIrrational" 163 "DI_a163_unparkReq" 244 "DI_a244_mechanical3PS" 90 "DI_a090_pmMIA" 17 "DI_a017_hwPedalMonitor" 88 "DI_a088_uiMIA" 98 "DI_a098_intTimeTooLong" 205 "DI_a205_vdcRcmLateral" 11 "DI_a011_swPowerStageNotReady" 14 "DI_a014_activeDamping" 21 "DI_a021_hwBusOV" 183 "DI_a183_holdReleaseRqrd" 202 "DI_a202_excessHeatUnavailable" 224 "DI_a224_brakeOverTemp" 74 "DI_a074_motorEncoder" 22 "DI_a022_hw5vSupplyUV" 115 "DI_a115_heatsinkTempImbalance" 103 "DI_a103_lowFlow" 235 "DI_a235_trackModeActive" 108 "DI_a108_stateTrans" 186 "DI_a186_brakeStand" 181 "DI_a181_rearMotorMode" 159 "DI_a159_cruiseSelfCheck" 200 "DI_a200_vdcModelBasedPlausibility" 197 "DI_a197_vdcEspWheelSaturations" 201 "DI_a201_regenLimited" 82 "DI_a082_accelTrack2" 187 "DI_a187_pedalMisapplication" 64 "DI_a064_torqueIntervention" 193 "DI_a193_vdcEspBrakeTorqueFr" 43 "DI_a043_outletOT" 123 "DI_a123_lossMotorControl" 40 "DI_a040_disMIA" 65 "DI_a065_canHardwareBusB" 81 "DI_a081_accelTrack1" 79 "DI_a079_adcRefHigh" 0 "DI_ALERT_DO_NOT_USE_ZERO" 80 "DI_a080_accelSynch" 207 "DI_a207_vdcPowertrainTorqueFr" 225 "DI_a225_tmpEstPlausibility" 182 "DI_a182_frontMotorMode" 232 "DI_a232_velocityEstimatorDegraded" 29 "DI_a029_phaseBrms" 162 "DI_a162_shiftDenied" 170 "DI_a170_pedalFoul" 110 "DI_a110_brakeMIA" 218 "DI_a218_vdcOSPreControlActive" 66 "DI_a066_canDataBusB" 165 "DI_a165_cruiseCancelled" 44 "DI_a044_outletUT" 157 "DI_a157_rcmMIA" 213 "DI_a213_velEstWheelSpeedCGRe" 133 "DI_a133_capacitorOT" 105 "DI_a105_cpMIA" 221 "DI_a221_vdcUndersteerdMzActive" 135 "DI_a135_vehicleHoldFault" 231 "DI_a231_ptcMIA" 230 "DI_a230_cmpMIA" 20 "DI_a020_hwMotorEncoder" 158 "DI_a158_ibstMIA" 175 "DI_a175_crsNotAvailable" 50 "DI_a050_noStatorSensor" 112 "DI_a112_noPhaseCurrent" 173 "DI_a173_bothPedalsPressed" 7 "DI_a007_hwHvilNotPresent" 125 "DI_a125_noBatteryPower" 129 "DI_a129_epbNotApplied" 152 "DI_a152_linError" 184 "DI_a184_autoparkCanceled" 137 "DI_a137_noCapableDriveUnits" 63 "DI_a063_systemGracefulPowerOff" 226 "DI_a226_sysStartConditionNotMet" 138 "DI_a138_frontUnitDisabled" 177 "DI_a177_tireFitmentChanged" 28 "DI_a028_phaseArms" 198 "DI_a198_vdcEspMCPressAndSteering" 59 "DI_a059_heatsinkOT" 56 "DI_a056_ambientOT" 32 "DI_a032_phaseBcurrentOffset" 164 "DI_a164_brakeOverride" 39 "DI_a039_noRegen" 234 "DI_a234_pcsMIA" 176 "DI_a176_EBRreleased" 72 "DI_a072_gateDriveFaultCounter" 73 "DI_a073_motorSpeed" 203 "DI_a203_TCReducedByADD" 196 "DI_a196_vdcEspSlipRe" 155 "DI_a155_vcfrontMIA" 36 "DI_a036_busOV" 212 "DI_a212_velEstWheelSpeedCGFr" 47 "DI_a047_statorSensor1" 86 "DI_a086_hvilNotPresent" 57 "DI_a057_ambientUT" 37 "DI_a037_busUV" 156 "DI_a156_currentObserver" 243 "DI_a243_ecuLogAvailable" 194 "DI_a194_vdcEspBrakeTorqueRe" 58 "DI_a058_ambientSensor" 206 "DI_a206_vdcRcmVertical" 151 "DI_a151_shockTorqueLimiter" 2 "DI_a002_hwPhaseBgateDrive" 83 "DI_a083_brakePedalSensor" 210 "DI_a210_vdcOtherControllerStates" 169 "DI_a169_regenOffOverride" 97 "DI_a097_eepromError" 136 "DI_a136_spiError" 25 "DI_a025_phaseApeak" 46 "DI_a046_statorOT" 76 "DI_a076_12vSupplyOV" 130 "DI_a130_aebFault" 149 "DI_a149_oilPumpFailure" 41 "DI_a041_driverBrakeApplyCheck" 126 "DI_a126_limpMode" 27 "DI_a027_phaseCpeak" 15 "DI_a015_immobilizer" 214 "DI_a214_velEstWheelSpeedNonCGFr" 189 "DI_a189_garageShiftWithPedal" 127 "DI_a127_gracefulPowerOff" 99 "DI_a099_threadOverrun" 114 "DI_a114_noMotorSpeed" 139 "DI_a139_rearUnitDisabled" 33 "DI_a033_phaseAcurrentSensor" 242 "DI_a242_rotorOffsetLearning" 116 "DI_a116_powerConvIrrational" 45 "DI_a045_outletSensor" 16 "DI_a016_safeStateApplied" 143 "DI_a143_mcuLimitActive" 78 "DI_a078_adcRefLow" 223 "DI_a223_tractionControlDisabled" 211 "DI_a211_vdcMotorSpeeds" 94 "DI_a094_canDataBusA" 67 "DI_a067_canOverrunBusB" 24 "DI_a024_selfTest" 148 "DI_a148_overtorqueUsed" 19 "DI_a019_hwAccelPedalPower" 166 "DI_a166_driverLeft" 192 "DI_a192_invalidOdometer" 174 "DI_a174_notOkToStartDrive" 122 "DI_a122_highStackUsage" 204 "DI_a204_vdcRcmLongitudinal" 161 "DI_a161_epas3pMIA" 219 "DI_a219_vdcOversteerdMzActive" 55 "DI_a055_trqCrossCheck" 144 "DI_a144_configMismatch" 117 "DI_a117_diMIA" 38 "DI_a038_busVsensor" 141 "DI_a141_dasMIA" 70 "DI_a070_12vSupplySensor" 95 "DI_a095_canOverrunBusA" 42 "DI_a042_inletSensor" 150 "DI_a150_busVD" 92 "DI_a092_bmsMIA" 121 "DI_a121_motorControlRegulation" 239 "DI_a239_neutralRequestByPM" 8 "DI_a008_hwEncoderA" 4 "DI_a004_hwPhaseApeak" 89 "DI_a089_sccmMIA" 6 "DI_a006_hwPhaseCpeak" 106 "DI_a106_absMIA" 75 "DI_a075_motorSpeedMismatch" 62 "DI_a062_systemLimpMode" 93 "DI_a093_canHardwareBusA" 168 "DI_a168_proximityDriveDenial" 77 "DI_a077_12vSupplyUV" 34 "DI_a034_phaseBcurrentSensor" 209 "DI_a209_vdcVehicleSpeed" 153 "DI_a153_oilPump" 216 "DI_a216_vdcMBPAlmostTripped" 23 "DI_a023_carNotParked" 113 "DI_a113_noFuncHeatsinkSensor" ;
